VERSION ""

NS_ :

BS_:

BU_: APPS BMS Charger ContactorDriver Dash Dyno IMD_Monitor Inverter Logger PDU Screen TelemetryCar TelemetryPits TempMon

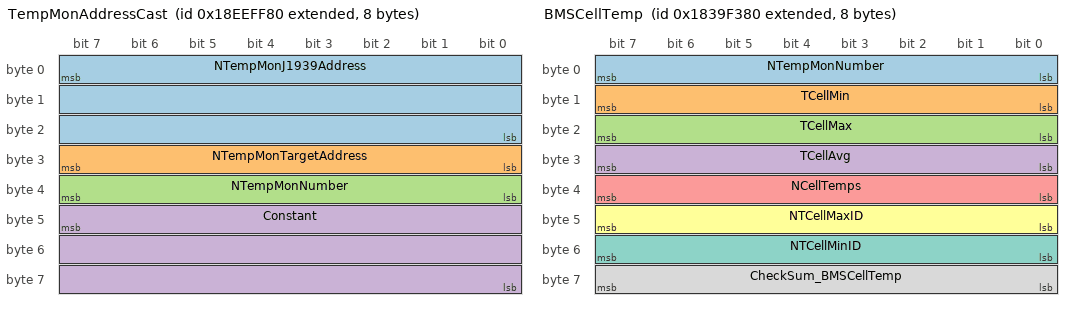
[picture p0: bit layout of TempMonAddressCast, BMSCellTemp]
BO_ 2565799808 TempMonAddressCast: 8 TempMon
 SG_ NTempMonJ1939Address : 7|24@0+ (1.000000,0.000000) [0.000000|16777215.000000] ""  BMS
 SG_ NTempMonTargetAddress : 31|8@0+ (1.000000,0.000000) [0.000000|255.000000] ""  BMS
 SG_ NTempMonNumber : 39|8@0+ (1.000000,0.000000) [0.000000|255.000000] ""  BMS
 SG_ Constant : 47|24@0+ (1.000000,0.000000) [0.000000|16777215.000000] ""  BMS

BO_ 2553934720 BMSCellTemp: 8 TempMon
 SG_ NTempMonNumber : 7|8@0+ (1.000000,0.000000) [0.000000|255.000000] ""  BMS
 SG_ TCellMin : 15|8@0- (1.000000,0.000000) [-128.000000|127.000000] "degC"  BMS
 SG_ TCellMax : 23|8@0- (1.000000,0.000000) [-128.000000|127.000000] "degC"  BMS
 SG_ TCellAvg : 31|8@0- (1.000000,0.000000) [-128.000000|127.000000] "degC"  BMS
 SG_ NCellTemps : 39|8@0+ (1.000000,0.000000) [0.000000|255.000000] ""  BMS
 SG_ NTCellMaxID : 47|8@0+ (1.000000,0.000000) [0.000000|255.000000] ""  BMS
 SG_ NTCellMinID : 55|8@0+ (1.000000,0.000000) [0.000000|255.000000] ""  BMS
 SG_ CheckSum_BMSCellTemp : 63|8@0+ (1.000000,0.000000) [0.000000|255.000000] ""  BMS

BO_ 2553869184 CellTempGeneral: 8 TempMon
 SG_ NTCellID M : 7|16@0+ (1.000000,0.000000) [0.000000|65535.000000] ""  BMS
 SG_ TCell001 m0 : 23|8@0- (1.000000,0.000000) [-128.000000|127.000000] "degC"  BMS
 SG_ TCell002 m1 : 23|8@0- (1.000000,0.000000) [-128.000000|127.000000] "degC"  BMS
 SG_ TCell003 m2 : 23|8@0- (1.000000,0.000000) [-128.000000|127.000000] "degC"  BMS
 SG_ TCell004 m3 : 23|8@0- (1.000000,0.000000) [-128.000000|127.000000] "degC"  BMS
 SG_ TCell005 m4 : 23|8@0- (1.000000,0.000000) [-128.000000|127.000000] "degC"  BMS
 SG_ TCell006 m5 : 23|8@0- (1.000000,0.000000) [-128.000000|127.000000] "degC"  BMS
 SG_ TCell007 m6 : 23|8@0- (1.000000,0.000000) [-128.000000|127.000000] "degC"  BMS
 SG_ TCell008 m7 : 23|8@0- (1.000000,0.000000) [-128.000000|127.000000] "degC"  BMS
 SG_ TCell009 m8 : 23|8@0- (1.000000,0.000000) [-128.000000|127.000000] "degC"  BMS
 SG_ TCell010 m9 : 23|8@0- (1.000000,0.000000) [-128.000000|127.000000] "degC"  BMS
 SG_ TCell011 m10 : 23|8@0- (1.000000,0.000000) [-128.000000|127.000000] "degC"  BMS
 SG_ TCell012 m11 : 23|8@0- (1.000000,0.000000) [-128.000000|127.000000] "degC"  BMS
 SG_ TCell013 m12 : 23|8@0- (1.000000,0.000000) [-128.000000|127.000000] "degC"  BMS
 SG_ TCell014 m13 : 23|8@0- (1.000000,0.000000) [-128.000000|127.000000] "degC"  BMS
 SG_ TCell015 m14 : 23|8@0- (1.000000,0.000000) [-128.000000|127.000000] "degC"  BMS
 SG_ TCell016 m15 : 23|8@0- (1.000000,0.000000) [-128.000000|127.000000] "degC"  BMS
 SG_ TCell017 m16 : 23|8@0- (1.000000,0.000000) [-128.000000|127.000000] "degC"  BMS
 SG_ TCell018 m17 : 23|8@0- (1.000000,0.000000) [-128.000000|127.000000] "degC"  BMS
 SG_ TCell019 m18 : 23|8@0- (1.000000,0.000000) [-128.000000|127.000000] "degC"  BMS
 SG_ TCell020 m19 : 23|8@0- (1.000000,0.000000) [-128.000000|127.000000] "degC"  BMS
 SG_ TCell021 m20 : 23|8@0- (1.000000,0.000000) [-128.000000|127.000000] "degC"  BMS
 SG_ TCell022 m21 : 23|8@0- (1.000000,0.000000) [-128.000000|127.000000] "degC"  BMS
 SG_ TCell023 m22 : 23|8@0- (1.000000,0.000000) [-128.000000|127.000000] "degC"  BMS
 SG_ TCell024 m23 : 23|8@0- (1.000000,0.000000) [-128.000000|127.000000] "degC"  BMS
 SG_ TCell025 m24 : 23|8@0- (1.000000,0.000000) [-128.000000|127.000000] "degC"  BMS
 SG_ TCell026 m25 : 23|8@0- (1.000000,0.000000) [-128.000000|127.000000] "degC"  BMS
 SG_ TCell027 m26 : 23|8@0- (1.000000,0.000000) [-128.000000|127.000000] "degC"  BMS
 SG_ TCell028 m27 : 23|8@0- (1.000000,0.000000) [-128.000000|127.000000] "degC"  BMS
 SG_ TCell029 m28 : 23|8@0- (1.000000,0.000000) [-128.000000|127.000000] "degC"  BMS
 SG_ TCell030 m29 : 23|8@0- (1.000000,0.000000) [-128.000000|127.000000] "degC"  BMS
 SG_ TCell031 m30 : 23|8@0- (1.000000,0.000000) [-128.000000|127.000000] "degC"  BMS
 SG_ TCell032 m31 : 23|8@0- (1.000000,0.000000) [-128.000000|127.000000] "degC"  BMS
 SG_ TCell033 m32 : 23|8@0- (1.000000,0.000000) [-128.000000|127.000000] "degC"  BMS
 SG_ TCell034 m33 : 23|8@0- (1.000000,0.000000) [-128.000000|127.000000] "degC"  BMS
 SG_ TCell035 m34 : 23|8@0- (1.000000,0.000000) [-128.000000|127.000000] "degC"  BMS
 SG_ TCell036 m35 : 23|8@0- (1.000000,0.000000) [-128.000000|127.000000] "degC"  BMS
 SG_ TCell037 m36 : 23|8@0- (1.000000,0.000000) [-128.000000|127.000000] "degC"  BMS
 SG_ TCell038 m37 : 23|8@0- (1.000000,0.000000) [-128.000000|127.000000] "degC"  BMS
 SG_ TCell039 m38 : 23|8@0- (1.000000,0.000000) [-128.000000|127.000000] "degC"  BMS
 SG_ TCell040 m39 : 23|8@0- (1.000000,0.000000) [-128.000000|127.000000] "degC"  BMS
 SG_ TCell041 m40 : 23|8@0- (1.000000,0.000000) [-128.000000|127.000000] "degC"  BMS
 SG_ TCell042 m41 : 23|8@0- (1.000000,0.000000) [-128.000000|127.000000] "degC"  BMS
 SG_ TCell043 m42 : 23|8@0- (1.000000,0.000000) [-128.000000|127.000000] "degC"  BMS
 SG_ TCell044 m43 : 23|8@0- (1.000000,0.000000) [-128.000000|127.000000] "degC"  BMS
 SG_ TCell045 m44 : 23|8@0- (1.000000,0.000000) [-128.000000|127.000000] "degC"  BMS
 SG_ TCell046 m45 : 23|8@0- (1.000000,0.000000) [-128.000000|127.000000] "degC"  BMS
 SG_ TCell047 m46 : 23|8@0- (1.000000,0.000000) [-128.000000|127.000000] "degC"  BMS
 SG_ TCell048 m47 : 23|8@0- (1.000000,0.000000) [-128.000000|127.000000] "degC"  BMS
 SG_ TCell049 m48 : 23|8@0- (1.000000,0.000000) [-128.000000|127.000000] "degC"  BMS
 SG_ TCell050 m49 : 23|8@0- (1.000000,0.000000) [-128.000000|127.000000] "degC"  BMS
 SG_ TCell051 m50 : 23|8@0- (1.000000,0.000000) [-128.000000|127.000000] "degC"  BMS
 SG_ TCell052 m51 : 23|8@0- (1.000000,0.000000) [-128.000000|127.000000] "degC"  BMS
 SG_ TCell053 m52 : 23|8@0- (1.000000,0.000000) [-128.000000|127.000000] "degC"  BMS
 SG_ TCell054 m53 : 23|8@0- (1.000000,0.000000) [-128.000000|127.000000] "degC"  BMS
 SG_ TCell055 m54 : 23|8@0- (1.000000,0.000000) [-128.000000|127.000000] "degC"  BMS
 SG_ TCell056 m55 : 23|8@0- (1.000000,0.000000) [-128.000000|127.000000] "degC"  BMS
 SG_ TCell057 m56 : 23|8@0- (1.000000,0.000000) [-128.000000|127.000000] "degC"  BMS
 SG_ TCell058 m57 : 23|8@0- (1.000000,0.000000) [-128.000000|127.000000] "degC"  BMS
 SG_ TCell059 m58 : 23|8@0- (1.000000,0.000000) [-128.000000|127.000000] "degC"  BMS
 SG_ TCell060 m59 : 23|8@0- (1.000000,0.000000) [-128.000000|127.000000] "degC"  BMS
 SG_ TCell061 m60 : 23|8@0- (1.000000,0.000000) [-128.000000|127.000000] "degC"  BMS
 SG_ TCell062 m61 : 23|8@0- (1.000000,0.000000) [-128.000000|127.000000] "degC"  BMS
 SG_ TCell063 m62 : 23|8@0- (1.000000,0.000000) [-128.000000|127.000000] "degC"  BMS
 SG_ TCell064 m63 : 23|8@0- (1.000000,0.000000) [-128.000000|127.000000] "degC"  BMS
 SG_ TCell065 m64 : 23|8@0- (1.000000,0.000000) [-128.000000|127.000000] "degC"  BMS
 SG_ TCell066 m65 : 23|8@0- (1.000000,0.000000) [-128.000000|127.000000] "degC"  BMS
 SG_ TCell067 m66 : 23|8@0- (1.000000,0.000000) [-128.000000|127.000000] "degC"  BMS
 SG_ TCell068 m67 : 23|8@0- (1.000000,0.000000) [-128.000000|127.000000] "degC"  BMS
 SG_ TCell069 m68 : 23|8@0- (1.000000,0.000000) [-128.000000|127.000000] "degC"  BMS
 SG_ TCell070 m69 : 23|8@0- (1.000000,0.000000) [-128.000000|127.000000] "degC"  BMS
 SG_ TCell071 m70 : 23|8@0- (1.000000,0.000000) [-128.000000|127.000000] "degC"  BMS
 SG_ TCell072 m71 : 23|8@0- (1.000000,0.000000) [-128.000000|127.000000] "degC"  BMS
 SG_ TCell073 m72 : 23|8@0- (1.000000,0.000000) [-128.000000|127.000000] "degC"  BMS
 SG_ TCell074 m73 : 23|8@0- (1.000000,0.000000) [-128.000000|127.000000] "degC"  BMS
 SG_ TCell075 m74 : 23|8@0- (1.000000,0.000000) [-128.000000|127.000000] "degC"  BMS
 SG_ TCell076 m75 : 23|8@0- (1.000000,0.000000) [-128.000000|127.000000] "degC"  BMS
 SG_ TCell077 m76 : 23|8@0- (1.000000,0.000000) [-128.000000|127.000000] "degC"  BMS
 SG_ TCell078 m77 : 23|8@0- (1.000000,0.000000) [-128.000000|127.000000] "degC"  BMS
 SG_ TCell079 m78 : 23|8@0- (1.000000,0.000000) [-128.000000|127.000000] "degC"  BMS
 SG_ TCell080 m79 : 23|8@0- (1.000000,0.000000) [-128.000000|127.000000] "degC"  BMS
 SG_ TCell081 m80 : 23|8@0- (1.000000,0.000000) [-128.000000|127.000000] "degC"  BMS
 SG_ TCell082 m81 : 23|8@0- (1.000000,0.000000) [-128.000000|127.000000] "degC"  BMS
 SG_ TCell083 m82 : 23|8@0- (1.000000,0.000000) [-128.000000|127.000000] "degC"  BMS
 SG_ TCell084 m83 : 23|8@0- (1.000000,0.000000) [-128.000000|127.000000] "degC"  BMS
 SG_ TCell085 m84 : 23|8@0- (1.000000,0.000000) [-128.000000|127.000000] "degC"  BMS
 SG_ TCell086 m85 : 23|8@0- (1.000000,0.000000) [-128.000000|127.000000] "degC"  BMS
 SG_ TCell087 m86 : 23|8@0- (1.000000,0.000000) [-128.000000|127.000000] "degC"  BMS
 SG_ TCell088 m87 : 23|8@0- (1.000000,0.000000) [-128.000000|127.000000] "degC"  BMS
 SG_ TCell089 m88 : 23|8@0- (1.000000,0.000000) [-128.000000|127.000000] "degC"  BMS
 SG_ TCell090 m89 : 23|8@0- (1.000000,0.000000) [-128.000000|127.000000] "degC"  BMS
 SG_ TCell091 m90 : 23|8@0- (1.000000,0.000000) [-128.000000|127.000000] "degC"  BMS
 SG_ TCell092 m91 : 23|8@0- (1.000000,0.000000) [-128.000000|127.000000] "degC"  BMS
 SG_ TCell093 m92 : 23|8@0- (1.000000,0.000000) [-128.000000|127.000000] "degC"  BMS
 SG_ TCell094 m93 : 23|8@0- (1.000000,0.000000) [-128.000000|127.000000] "degC"  BMS
 SG_ TCell095 m94 : 23|8@0- (1.000000,0.000000) [-128.000000|127.000000] "degC"  BMS
 SG_ TCell096 m95 : 23|8@0- (1.000000,0.000000) [-128.000000|127.000000] "degC"  BMS
 SG_ TCell097 m96 : 23|8@0- (1.000000,0.000000) [-128.000000|127.000000] "degC"  BMS
 SG_ TCell098 m97 : 23|8@0- (1.000000,0.000000) [-128.000000|127.000000] "degC"  BMS
 SG_ TCell099 m98 : 23|8@0- (1.000000,0.000000) [-128.000000|127.000000] "degC"  BMS
 SG_ TCell100 m99 : 23|8@0- (1.000000,0.000000) [-128.000000|127.000000] "degC"  BMS
 SG_ TCell101 m100 : 23|8@0- (1.000000,0.000000) [-128.000000|127.000000] "degC"  BMS
 SG_ TCell102 m101 : 23|8@0- (1.000000,0.000000) [-128.000000|127.000000] "degC"  BMS
 SG_ TCell103 m102 : 23|8@0- (1.000000,0.000000) [-128.000000|127.000000] "degC"  BMS
 SG_ TCell104 m103 : 23|8@0- (1.000000,0.000000) [-128.000000|127.000000] "degC"  BMS
 SG_ TCell105 m104 : 23|8@0- (1.000000,0.000000) [-128.000000|127.000000] "degC"  BMS
 SG_ TCell106 m105 : 23|8@0- (1.000000,0.000000) [-128.000000|127.000000] "degC"  BMS
 SG_ TCell107 m106 : 23|8@0- (1.000000,0.000000) [-128.000000|127.000000] "degC"  BMS
 SG_ TCell108 m107 : 23|8@0- (1.000000,0.000000) [-128.000000|127.000000] "degC"  BMS
 SG_ TCell109 m108 : 23|8@0- (1.000000,0.000000) [-128.000000|127.000000] "degC"  BMS
 SG_ TCell110 m109 : 23|8@0- (1.000000,0.000000) [-128.000000|127.000000] "degC"  BMS
 SG_ Constant m0 : 31|8@0+ (1.000000,0.000000) [0.000000|255.000000] ""  BMS
 SG_ Constant m1 : 31|8@0+ (1.000000,0.000000) [0.000000|255.000000] ""  BMS
 SG_ Constant m2 : 31|8@0+ (1.000000,0.000000) [0.000000|255.000000] ""  BMS
 SG_ Constant m3 : 31|8@0+ (1.000000,0.000000) [0.000000|255.000000] ""  BMS
 SG_ Constant m4 : 31|8@0+ (1.000000,0.000000) [0.000000|255.000000] ""  BMS
 SG_ Constant m5 : 31|8@0+ (1.000000,0.000000) [0.000000|255.000000] ""  BMS
 SG_ Constant m6 : 31|8@0+ (1.000000,0.000000) [0.000000|255.000000] ""  BMS
 SG_ Constant m7 : 31|8@0+ (1.000000,0.000000) [0.000000|255.000000] ""  BMS
 SG_ Constant m8 : 31|8@0+ (1.000000,0.000000) [0.000000|255.000000] ""  BMS
 SG_ Constant m9 : 31|8@0+ (1.000000,0.000000) [0.000000|255.000000] ""  BMS
 SG_ Constant m10 : 31|8@0+ (1.000000,0.000000) [0.000000|255.000000] ""  BMS
 SG_ Constant m11 : 31|8@0+ (1.000000,0.000000) [0.000000|255.000000] ""  BMS
 SG_ Constant m12 : 31|8@0+ (1.000000,0.000000) [0.000000|255.000000] ""  BMS
 SG_ Constant m13 : 31|8@0+ (1.000000,0.000000) [0.000000|255.000000] ""  BMS
 SG_ Constant m14 : 31|8@0+ (1.000000,0.000000) [0.000000|255.000000] ""  BMS
 SG_ Constant m15 : 31|8@0+ (1.000000,0.000000) [0.000000|255.000000] ""  BMS
 SG_ Constant m16 : 31|8@0+ (1.000000,0.000000) [0.000000|255.000000] ""  BMS
 SG_ Constant m17 : 31|8@0+ (1.000000,0.000000) [0.000000|255.000000] ""  BMS
 SG_ Constant m18 : 31|8@0+ (1.000000,0.000000) [0.000000|255.000000] ""  BMS
 SG_ Constant m19 : 31|8@0+ (1.000000,0.000000) [0.000000|255.000000] ""  BMS
 SG_ Constant m20 : 31|8@0+ (1.000000,0.000000) [0.000000|255.000000] ""  BMS
 SG_ Constant m21 : 31|8@0+ (1.000000,0.000000) [0.000000|255.000000] ""  BMS
 SG_ Constant m22 : 31|8@0+ (1.000000,0.000000) [0.000000|255.000000] ""  BMS
 SG_ Constant m23 : 31|8@0+ (1.000000,0.000000) [0.000000|255.000000] ""  BMS
 SG_ Constant m24 : 31|8@0+ (1.000000,0.000000) [0.000000|255.000000] ""  BMS
 SG_ Constant m25 : 31|8@0+ (1.000000,0.000000) [0.000000|255.000000] ""  BMS
 SG_ Constant m26 : 31|8@0+ (1.000000,0.000000) [0.000000|255.000000] ""  BMS
 SG_ Constant m27 : 31|8@0+ (1.000000,0.000000) [0.000000|255.000000] ""  BMS
 SG_ Constant m28 : 31|8@0+ (1.000000,0.000000) [0.000000|255.000000] ""  BMS
 SG_ Constant m29 : 31|8@0+ (1.000000,0.000000) [0.000000|255.000000] ""  BMS
 SG_ Constant m30 : 31|8@0+ (1.000000,0.000000) [0.000000|255.000000] ""  BMS
 SG_ Constant m31 : 31|8@0+ (1.000000,0.000000) [0.000000|255.000000] ""  BMS
 SG_ Constant m32 : 31|8@0+ (1.000000,0.000000) [0.000000|255.000000] ""  BMS
 SG_ Constant m33 : 31|8@0+ (1.000000,0.000000) [0.000000|255.000000] ""  BMS
 SG_ Constant m34 : 31|8@0+ (1.000000,0.000000) [0.000000|255.000000] ""  BMS
 SG_ Constant m35 : 31|8@0+ (1.000000,0.000000) [0.000000|255.000000] ""  BMS
 SG_ Constant m36 : 31|8@0+ (1.000000,0.000000) [0.000000|255.000000] ""  BMS
 SG_ Constant m37 : 31|8@0+ (1.000000,0.000000) [0.000000|255.000000] ""  BMS
 SG_ Constant m38 : 31|8@0+ (1.000000,0.000000) [0.000000|255.000000] ""  BMS
 SG_ Constant m39 : 31|8@0+ (1.000000,0.000000) [0.000000|255.000000] ""  BMS
 SG_ Constant m40 : 31|8@0+ (1.000000,0.000000) [0.000000|255.000000] ""  BMS
 SG_ Constant m41 : 31|8@0+ (1.000000,0.000000) [0.000000|255.000000] ""  BMS
 SG_ Constant m42 : 31|8@0+ (1.000000,0.000000) [0.000000|255.000000] ""  BMS
 SG_ Constant m43 : 31|8@0+ (1.000000,0.000000) [0.000000|255.000000] ""  BMS
 SG_ Constant m44 : 31|8@0+ (1.000000,0.000000) [0.000000|255.000000] ""  BMS
 SG_ Constant m45 : 31|8@0+ (1.000000,0.000000) [0.000000|255.000000] ""  BMS
 SG_ Constant m46 : 31|8@0+ (1.000000,0.000000) [0.000000|255.000000] ""  BMS
 SG_ Constant m47 : 31|8@0+ (1.000000,0.000000) [0.000000|255.000000] ""  BMS
 SG_ Constant m48 : 31|8@0+ (1.000000,0.000000) [0.000000|255.000000] ""  BMS
 SG_ Constant m49 : 31|8@0+ (1.000000,0.000000) [0.000000|255.000000] ""  BMS
 SG_ Constant m50 : 31|8@0+ (1.000000,0.000000) [0.000000|255.000000] ""  BMS
 SG_ Constant m51 : 31|8@0+ (1.000000,0.000000) [0.000000|255.000000] ""  BMS
 SG_ Constant m52 : 31|8@0+ (1.000000,0.000000) [0.000000|255.000000] ""  BMS
 SG_ Constant m53 : 31|8@0+ (1.000000,0.000000) [0.000000|255.000000] ""  BMS
 SG_ Constant m54 : 31|8@0+ (1.000000,0.000000) [0.000000|255.000000] ""  BMS
 SG_ Constant m55 : 31|8@0+ (1.000000,0.000000) [0.000000|255.000000] ""  BMS
 SG_ Constant m56 : 31|8@0+ (1.000000,0.000000) [0.000000|255.000000] ""  BMS
 SG_ Constant m57 : 31|8@0+ (1.000000,0.000000) [0.000000|255.000000] ""  BMS
 SG_ Constant m58 : 31|8@0+ (1.000000,0.000000) [0.000000|255.000000] ""  BMS
 SG_ Constant m59 : 31|8@0+ (1.000000,0.000000) [0.000000|255.000000] ""  BMS
 SG_ Constant m60 : 31|8@0+ (1.000000,0.000000) [0.000000|255.000000] ""  BMS
 SG_ Constant m61 : 31|8@0+ (1.000000,0.000000) [0.000000|255.000000] ""  BMS
 SG_ Constant m62 : 31|8@0+ (1.000000,0.000000) [0.000000|255.000000] ""  BMS
 SG_ Constant m63 : 31|8@0+ (1.000000,0.000000) [0.000000|255.000000] ""  BMS
 SG_ Constant m64 : 31|8@0+ (1.000000,0.000000) [0.000000|255.000000] ""  BMS
 SG_ Constant m65 : 31|8@0+ (1.000000,0.000000) [0.000000|255.000000] ""  BMS
 SG_ Constant m66 : 31|8@0+ (1.000000,0.000000) [0.000000|255.000000] ""  BMS
 SG_ Constant m67 : 31|8@0+ (1.000000,0.000000) [0.000000|255.000000] ""  BMS
 SG_ Constant m68 : 31|8@0+ (1.000000,0.000000) [0.000000|255.000000] ""  BMS
 SG_ Constant m69 : 31|8@0+ (1.000000,0.000000) [0.000000|255.000000] ""  BMS
 SG_ Constant m70 : 31|8@0+ (1.000000,0.000000) [0.000000|255.000000] ""  BMS
 SG_ Constant m71 : 31|8@0+ (1.000000,0.000000) [0.000000|255.000000] ""  BMS
 SG_ Constant m72 : 31|8@0+ (1.000000,0.000000) [0.000000|255.000000] ""  BMS
 SG_ Constant m73 : 31|8@0+ (1.000000,0.000000) [0.000000|255.000000] ""  BMS
 SG_ Constant m74 : 31|8@0+ (1.000000,0.000000) [0.000000|255.000000] ""  BMS
 SG_ Constant m75 : 31|8@0+ (1.000000,0.000000) [0.000000|255.000000] ""  BMS
 SG_ Constant m76 : 31|8@0+ (1.000000,0.000000) [0.000000|255.000000] ""  BMS
 SG_ Constant m77 : 31|8@0+ (1.000000,0.000000) [0.000000|255.000000] ""  BMS
 SG_ Constant m78 : 31|8@0+ (1.000000,0.000000) [0.000000|255.000000] ""  BMS
 SG_ Constant m79 : 31|8@0+ (1.000000,0.000000) [0.000000|255.000000] ""  BMS
 SG_ Constant m80 : 31|8@0+ (1.000000,0.000000) [0.000000|255.000000] ""  BMS
 SG_ Constant m81 : 31|8@0+ (1.000000,0.000000) [0.000000|255.000000] ""  BMS
 SG_ Constant m82 : 31|8@0+ (1.000000,0.000000) [0.000000|255.000000] ""  BMS
 SG_ Constant m83 : 31|8@0+ (1.000000,0.000000) [0.000000|255.000000] ""  BMS
 SG_ Constant m84 : 31|8@0+ (1.000000,0.000000) [0.000000|255.000000] ""  BMS
 SG_ Constant m85 : 31|8@0+ (1.000000,0.000000) [0.000000|255.000000] ""  BMS
 SG_ Constant m86 : 31|8@0+ (1.000000,0.000000) [0.000000|255.000000] ""  BMS
 SG_ Constant m87 : 31|8@0+ (1.000000,0.000000) [0.000000|255.000000] ""  BMS
 SG_ Constant m88 : 31|8@0+ (1.000000,0.000000) [0.000000|255.000000] ""  BMS
 SG_ Constant m89 : 31|8@0+ (1.000000,0.000000) [0.000000|255.000000] ""  BMS
 SG_ Constant m90 : 31|8@0+ (1.000000,0.000000) [0.000000|255.000000] ""  BMS
 SG_ Constant m91 : 31|8@0+ (1.000000,0.000000) [0.000000|255.000000] ""  BMS
 SG_ Constant m92 : 31|8@0+ (1.000000,0.000000) [0.000000|255.000000] ""  BMS
 SG_ Constant m93 : 31|8@0+ (1.000000,0.000000) [0.000000|255.000000] ""  BMS
 SG_ Constant m94 : 31|8@0+ (1.000000,0.000000) [0.000000|255.000000] ""  BMS
 SG_ Constant m95 : 31|8@0+ (1.000000,0.000000) [0.000000|255.000000] ""  BMS
 SG_ Constant m96 : 31|8@0+ (1.000000,0.000000) [0.000000|255.000000] ""  BMS
 SG_ Constant m97 : 31|8@0+ (1.000000,0.000000) [0.000000|255.000000] ""  BMS
 SG_ Constant m98 : 31|8@0+ (1.000000,0.000000) [0.000000|255.000000] ""  BMS
 SG_ Constant m99 : 31|8@0+ (1.000000,0.000000) [0.000000|255.000000] ""  BMS
 SG_ Constant m100 : 31|8@0+ (1.000000,0.000000) [0.000000|255.000000] ""  BMS
 SG_ Constant m101 : 31|8@0+ (1.000000,0.000000) [0.000000|255.000000] ""  BMS
 SG_ Constant m102 : 31|8@0+ (1.000000,0.000000) [0.000000|255.000000] ""  BMS
 SG_ Constant m103 : 31|8@0+ (1.000000,0.000000) [0.000000|255.000000] ""  BMS
 SG_ Constant m104 : 31|8@0+ (1.000000,0.000000) [0.000000|255.000000] ""  BMS
 SG_ Constant m105 : 31|8@0+ (1.000000,0.000000) [0.000000|255.000000] ""  BMS
 SG_ Constant m106 : 31|8@0+ (1.000000,0.000000) [0.000000|255.000000] ""  BMS
 SG_ Constant m107 : 31|8@0+ (1.000000,0.000000) [0.000000|255.000000] ""  BMS
 SG_ Constant m108 : 31|8@0+ (1.000000,0.000000) [0.000000|255.000000] ""  BMS
 SG_ Constant m109 : 31|8@0+ (1.000000,0.000000) [0.000000|255.000000] ""  BMS
 SG_ TCellMin : 39|8@0- (1.000000,0.000000) [-128.000000|127.000000] "degC"  BMS
 SG_ TCellMax : 47|8@0- (1.000000,0.000000) [-128.000000|127.000000] "degC"  BMS
 SG_ NTCellMaxID : 55|8@0+ (1.000000,0.000000) [0.000000|255.000000] ""  BMS
 SG_ NTCellMinID : 63|8@0+ (1.000000,0.000000) [0.000000|255.000000] ""  BMS

BO_ 2550589940 ElconInterface3: 8 BMS
 SG_ Maximum_Cell_Voltage : 7|16@0+ (0.100000,0.000000) [0.000000|6553.500000] "V"  Charger
 SG_ Pack_CCL : 23|16@0+ (0.100000,0.000000) [0.000000|6553.500000] "A"  Charger
 SG_ DTC_P0A08_Charger_Safety_Relay_Fault : 32|1@1+ (1.000000,0.000000) [0.000000|1.000000] ""  Charger
 SG_ Reserved : 38|31@0+ (1.000000,0.000000) [0.000000|2147483647.000000] ""  Charger

BO_ 2550589428 ElconInterface1: 8 BMS
 SG_ Maximum_Pack_Voltage : 7|16@0+ (0.100000,0.000000) [0.000000|6553.500000] "V"  Charger
 SG_ Pack_CCL : 23|16@0- (0.100000,0.000000) [-3276.800000|3276.700000] "A"  Charger
 SG_ DTC_P0A08_Charger_Safety_Relay_Fault : 32|1@1+ (1.000000,0.000000) [0.000000|1.000000] ""  Charger
 SG_ Reserved : 38|31@0+ (1.000000,0.000000) [0.000000|2147483647.000000] ""  Charger

BO_ 2550588916 ElconInterface2: 8 BMS
 SG_ Maximum_Cell_Voltage : 7|16@0+ (0.100000,0.000000) [0.000000|6553.500000] "V"  Charger
 SG_ Pack_CCL : 23|16@0- (0.100000,0.000000) [-3276.800000|3276.700000] "A"  Charger
 SG_ DTC_P0A08_Charger_Safety_Relay_Fault : 32|1@1+ (1.000000,0.000000) [0.000000|1.000000] ""  Charger
 SG_ Reserved : 38|31@0+ (1.000000,0.000000) [0.000000|2147483647.000000] ""  Charger

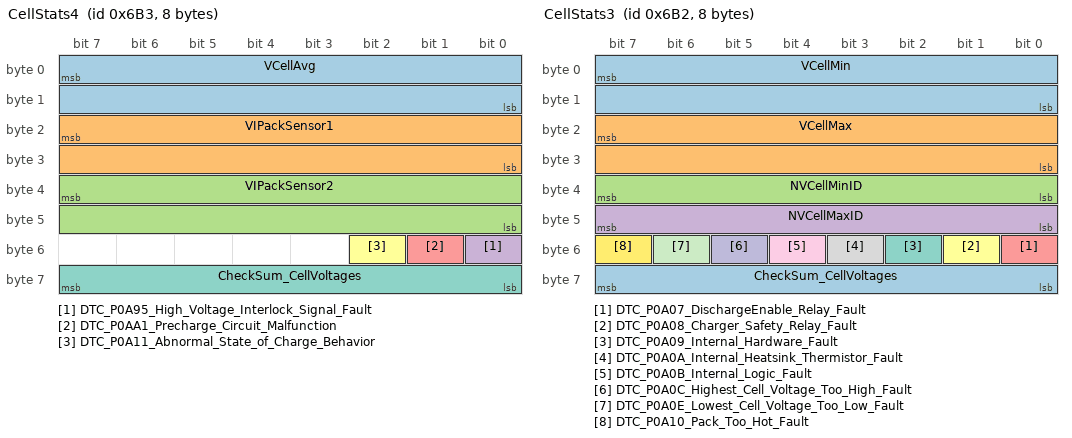
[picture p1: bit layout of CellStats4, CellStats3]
BO_ 1715 CellStats4: 8 BMS
 SG_ VCellAvg : 7|16@0+ (0.000100,0.000000) [0.000000|6.553500] "V"  Logger
 SG_ VIPackSensor1 : 23|16@0+ (1.000000,0.000000) [0.000000|65535.000000] ""  Logger
 SG_ VIPackSensor2 : 39|16@0+ (1.000000,0.000000) [0.000000|65535.000000] ""  Logger
 SG_ DTC_P0A95_High_Voltage_Interlock_Signal_Fault : 48|1@1+ (1.000000,0.000000) [0.000000|1.000000] ""  Logger
 SG_ DTC_P0AA1_Precharge_Circuit_Malfunction : 49|1@1+ (1.000000,0.000000) [0.000000|1.000000] ""  Logger
 SG_ DTC_P0A11_Abnormal_State_of_Charge_Behavior : 50|1@1+ (1.000000,0.000000) [0.000000|1.000000] ""  Logger
 SG_ CheckSum_CellVoltages : 63|8@0+ (1.000000,0.000000) [0.000000|255.000000] ""  Logger

BO_ 1714 CellStats3: 8 BMS
 SG_ VCellMin : 7|16@0+ (0.000100,0.000000) [0.000000|6.553500] "V"  Logger
 SG_ VCellMax : 23|16@0+ (0.000100,0.000000) [0.000000|6.553500] "V"  Logger
 SG_ NVCellMinID : 39|8@0+ (1.000000,0.000000) [0.000000|255.000000] "ID"  Logger
 SG_ NVCellMaxID : 47|8@0+ (1.000000,0.000000) [0.000000|255.000000] "ID"  Logger
 SG_ DTC_P0A07_DischargeEnable_Relay_Fault : 48|1@1+ (1.000000,0.000000) [0.000000|1.000000] ""  Logger
 SG_ DTC_P0A08_Charger_Safety_Relay_Fault : 49|1@1+ (1.000000,0.000000) [0.000000|1.000000] ""  Logger
 SG_ DTC_P0A09_Internal_Hardware_Fault : 50|1@1+ (1.000000,0.000000) [0.000000|1.000000] ""  Logger
 SG_ DTC_P0A0A_Internal_Heatsink_Thermistor_Fault : 51|1@1+ (1.000000,0.000000) [0.000000|1.000000] ""  Logger
 SG_ DTC_P0A0B_Internal_Logic_Fault : 52|1@1+ (1.000000,0.000000) [0.000000|1.000000] ""  Logger
 SG_ DTC_P0A0C_Highest_Cell_Voltage_Too_High_Fault : 53|1@1+ (1.000000,0.000000) [0.000000|1.000000] ""  Logger
 SG_ DTC_P0A0E_Lowest_Cell_Voltage_Too_Low_Fault : 54|1@1+ (1.000000,0.000000) [0.000000|1.000000] ""  Logger
 SG_ DTC_P0A10_Pack_Too_Hot_Fault : 55|1@1+ (1.000000,0.000000) [0.000000|1.000000] ""  Logger
 SG_ CheckSum_CellVoltages : 63|8@0+ (1.000000,0.000000) [0.000000|255.000000] ""  Logger

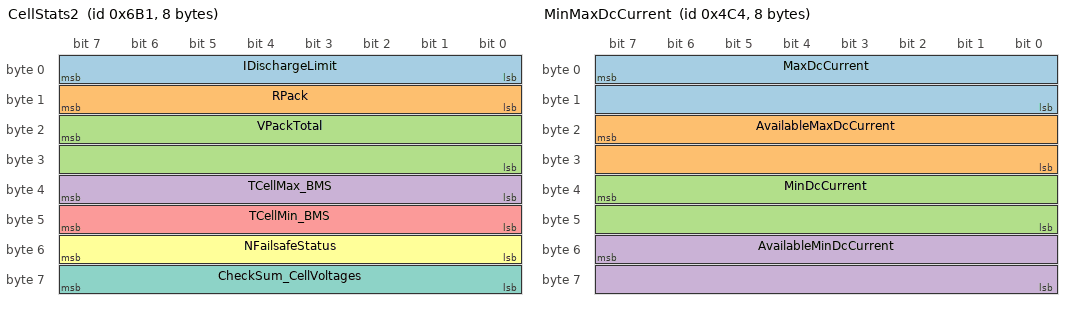
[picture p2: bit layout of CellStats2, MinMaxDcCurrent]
BO_ 1713 CellStats2: 8 BMS
 SG_ IDischargeLimit : 7|8@0+ (1.000000,0.000000) [0.000000|255.000000] "A"  Logger
 SG_ RPack : 15|8@0+ (0.001000,0.000000) [0.000000|0.255000] "Ohms"  Logger
 SG_ VPackTotal : 23|16@0+ (0.010000,0.000000) [0.000000|655.350000] "V"  Logger
 SG_ TCellMax_BMS : 39|8@0+ (1.000000,0.000000) [0.000000|255.000000] "degC"  Logger
 SG_ TCellMin_BMS : 47|8@0+ (1.000000,0.000000) [0.000000|255.000000] "degC"  Logger
 SG_ NFailsafeStatus : 55|8@0+ (1.000000,0.000000) [0.000000|255.000000] ""  Logger
 SG_ CheckSum_CellVoltages : 63|8@0+ (1.000000,1721.000000) [1721.000000|1976.000000] ""  Logger

BO_ 1712 CellStats1: 8 BMS
 SG_ IPack : 7|16@0+ (0.100000,0.000000) [0.000000|6553.500000] "A"  Logger
 SG_ VPackInstant : 23|16@0+ (0.100000,0.000000) [0.000000|6553.500000] "V"  Logger
 SG_ rSOC : 39|8@0+ (0.500000,0.000000) [0.000000|127.500000] "%"  Logger
 SG_ Ready_Power_Signal : 47|1@0+ (1.000000,0.000000) [0.000000|1.000000] ""  Logger
 SG_ Charge_Power_Signal : 41|1@1+ (1.000000,0.000000) [0.000000|1.000000] ""  Logger
 SG_ Charge_Interlock : 42|1@1+ (1.000000,0.000000) [0.000000|1.000000] ""  Logger
 SG_ Balancing_Active : 43|1@1+ (1.000000,0.000000) [0.000000|1.000000] ""  Logger
 SG_ Discharge_Enable_Inverted : 44|1@1+ (1.000000,0.000000) [0.000000|1.000000] ""  Logger
 SG_ Charge_Enable_Inverted : 45|1@1+ (1.000000,0.000000) [0.000000|1.000000] ""  Logger
 SG_ Charge_Mode_Active_CAN : 46|1@1+ (1.000000,0.000000) [0.000000|1.000000] ""  Logger
 SG_ MultiPurpose_Input : 47|1@1+ (1.000000,0.000000) [0.000000|1.000000] ""  Logger
 SG_ DTC_P0A1F_Internal_Cell_Communication_Fault : 48|1@1+ (1.000000,0.000000) [0.000000|1.000000] ""  Logger
 SG_ DTC_P0A12_Cell_Balancing_Stuck_Off_Fault : 49|1@1+ (1.000000,0.000000) [0.000000|1.000000] ""  Logger
 SG_ DTC_P0A80_Weak_Cell_Fault : 50|1@1+ (1.000000,0.000000) [0.000000|1.000000] ""  Logger
 SG_ DTC_P0AFA_Low_Cell_Voltage_Fault : 51|1@1+ (1.000000,0.000000) [0.000000|1.000000] ""  Logger
 SG_ DTC_P0A04_Cell_Open_Wiring_Fault : 52|1@1+ (1.000000,0.000000) [0.000000|1.000000] ""  Logger
 SG_ DTC_P0AC0_Current_Sensor_Fault : 53|1@1+ (1.000000,0.000000) [0.000000|1.000000] ""  Logger
 SG_ DTC_P0A0D_Cell_Voltage_Over_5V_Fault : 54|1@1+ (1.000000,0.000000) [0.000000|1.000000] ""  Logger
 SG_ DTC_P0A0F_Cell_Bank_Fault : 55|1@1+ (1.000000,0.000000) [0.000000|1.000000] ""  Logger
 SG_ CheckSum_CellVoltages : 63|8@0+ (1.000000,1720.000000) [1720.000000|1975.000000] ""  Logger

BO_ 1696 CellTempStats: 8 TempMon
 SG_ CellID_Temp M : 7|8@0+ (1.000000,0.000000) [0.000000|255.000000] ""  Logger
 SG_ BTCell001InError m1 : 15|1@0+ (1.000000,0.000000) [0.000000|1.000000] ""  Logger
 SG_ BTCell002InError m2 : 15|1@0+ (1.000000,0.000000) [0.000000|1.000000] ""  Logger
 SG_ BTCell003InError m3 : 15|1@0+ (1.000000,0.000000) [0.000000|1.000000] ""  Logger
 SG_ BTCell004InError m4 : 15|1@0+ (1.000000,0.000000) [0.000000|1.000000] ""  Logger
 SG_ BTCell005InError m5 : 15|1@0+ (1.000000,0.000000) [0.000000|1.000000] ""  Logger
 SG_ BTCell006InError m6 : 15|1@0+ (1.000000,0.000000) [0.000000|1.000000] ""  Logger
 SG_ BTCell007InError m7 : 15|1@0+ (1.000000,0.000000) [0.000000|1.000000] ""  Logger
 SG_ BTCell008InError m8 : 15|1@0+ (1.000000,0.000000) [0.000000|1.000000] ""  Logger
 SG_ BTCell009InError m9 : 15|1@0+ (1.000000,0.000000) [0.000000|1.000000] ""  Logger
 SG_ BTCell010InError m10 : 15|1@0+ (1.000000,0.000000) [0.000000|1.000000] ""  Logger
 SG_ BTCell011InError m11 : 15|1@0+ (1.000000,0.000000) [0.000000|1.000000] ""  Logger
 SG_ BTCell012InError m12 : 15|1@0+ (1.000000,0.000000) [0.000000|1.000000] ""  Logger
 SG_ BTCell013InError m13 : 15|1@0+ (1.000000,0.000000) [0.000000|1.000000] ""  Logger
 SG_ BTCell014InError m14 : 15|1@0+ (1.000000,0.000000) [0.000000|1.000000] ""  Logger
 SG_ BTCell015InError m15 : 15|1@0+ (1.000000,0.000000) [0.000000|1.000000] ""  Logger
 SG_ BTCell016InError m16 : 15|1@0+ (1.000000,0.000000) [0.000000|1.000000] ""  Logger
 SG_ BTCell017InError m17 : 15|1@0+ (1.000000,0.000000) [0.000000|1.000000] ""  Logger
 SG_ BTCell018InError m18 : 15|1@0+ (1.000000,0.000000) [0.000000|1.000000] ""  Logger
 SG_ BTCell019InError m19 : 15|1@0+ (1.000000,0.000000) [0.000000|1.000000] ""  Logger
 SG_ BTCell020InError m20 : 15|1@0+ (1.000000,0.000000) [0.000000|1.000000] ""  Logger
 SG_ BTCell021InError m21 : 15|1@0+ (1.000000,0.000000) [0.000000|1.000000] ""  Logger
 SG_ BTCell022InError m22 : 15|1@0+ (1.000000,0.000000) [0.000000|1.000000] ""  Logger
 SG_ BTCell023InError m23 : 15|1@0+ (1.000000,0.000000) [0.000000|1.000000] ""  Logger
 SG_ BTCell024InError m24 : 15|1@0+ (1.000000,0.000000) [0.000000|1.000000] ""  Logger
 SG_ BTCell025InError m25 : 15|1@0+ (1.000000,0.000000) [0.000000|1.000000] ""  Logger
 SG_ BTCell026InError m26 : 15|1@0+ (1.000000,0.000000) [0.000000|1.000000] ""  Logger
 SG_ BTCell027InError m27 : 15|1@0+ (1.000000,0.000000) [0.000000|1.000000] ""  Logger
 SG_ BTCell028InError m28 : 15|1@0+ (1.000000,0.000000) [0.000000|1.000000] ""  Logger
 SG_ BTCell029InError m29 : 15|1@0+ (1.000000,0.000000) [0.000000|1.000000] ""  Logger
 SG_ BTCell030InError m30 : 15|1@0+ (1.000000,0.000000) [0.000000|1.000000] ""  Logger
 SG_ BTCell031InError m31 : 15|1@0+ (1.000000,0.000000) [0.000000|1.000000] ""  Logger
 SG_ BTCell032InError m32 : 15|1@0+ (1.000000,0.000000) [0.000000|1.000000] ""  Logger
 SG_ BTCell033InError m33 : 15|1@0+ (1.000000,0.000000) [0.000000|1.000000] ""  Logger
 SG_ BTCell034InError m34 : 15|1@0+ (1.000000,0.000000) [0.000000|1.000000] ""  Logger
 SG_ BTCell035InError m35 : 15|1@0+ (1.000000,0.000000) [0.000000|1.000000] ""  Logger
 SG_ BTCell036InError m36 : 15|1@0+ (1.000000,0.000000) [0.000000|1.000000] ""  Logger
 SG_ BTCell037InError m37 : 15|1@0+ (1.000000,0.000000) [0.000000|1.000000] ""  Logger
 SG_ BTCell038InError m38 : 15|1@0+ (1.000000,0.000000) [0.000000|1.000000] ""  Logger
 SG_ BTCell039InError m39 : 15|1@0+ (1.000000,0.000000) [0.000000|1.000000] ""  Logger
 SG_ BTCell040InError m40 : 15|1@0+ (1.000000,0.000000) [0.000000|1.000000] ""  Logger
 SG_ BTCell041InError m41 : 15|1@0+ (1.000000,0.000000) [0.000000|1.000000] ""  Logger
 SG_ BTCell042InError m42 : 15|1@0+ (1.000000,0.000000) [0.000000|1.000000] ""  Logger
 SG_ BTCell043InError m43 : 15|1@0+ (1.000000,0.000000) [0.000000|1.000000] ""  Logger
 SG_ BTCell044InError m44 : 15|1@0+ (1.000000,0.000000) [0.000000|1.000000] ""  Logger
 SG_ BTCell045InError m45 : 15|1@0+ (1.000000,0.000000) [0.000000|1.000000] ""  Logger
 SG_ BTCell046InError m46 : 15|1@0+ (1.000000,0.000000) [0.000000|1.000000] ""  Logger
 SG_ BTCell047InError m47 : 15|1@0+ (1.000000,0.000000) [0.000000|1.000000] ""  Logger
 SG_ BTCell048InError m48 : 15|1@0+ (1.000000,0.000000) [0.000000|1.000000] ""  Logger
 SG_ BTCell049InError m49 : 15|1@0+ (1.000000,0.000000) [0.000000|1.000000] ""  Logger
 SG_ BTCell050InError m50 : 15|1@0+ (1.000000,0.000000) [0.000000|1.000000] ""  Logger
 SG_ BTCell051InError m51 : 15|1@0+ (1.000000,0.000000) [0.000000|1.000000] ""  Logger
 SG_ BTCell052InError m52 : 15|1@0+ (1.000000,0.000000) [0.000000|1.000000] ""  Logger
 SG_ BTCell053InError m53 : 15|1@0+ (1.000000,0.000000) [0.000000|1.000000] ""  Logger
 SG_ BTCell054InError m54 : 15|1@0+ (1.000000,0.000000) [0.000000|1.000000] ""  Logger
 SG_ BTCell055InError m55 : 15|1@0+ (1.000000,0.000000) [0.000000|1.000000] ""  Logger
 SG_ BTCell056InError m56 : 15|1@0+ (1.000000,0.000000) [0.000000|1.000000] ""  Logger
 SG_ BTCell057InError m57 : 15|1@0+ (1.000000,0.000000) [0.000000|1.000000] ""  Logger
 SG_ BTCell058InError m58 : 15|1@0+ (1.000000,0.000000) [0.000000|1.000000] ""  Logger
 SG_ BTCell059InError m59 : 15|1@0+ (1.000000,0.000000) [0.000000|1.000000] ""  Logger
 SG_ BTCell060InError m60 : 15|1@0+ (1.000000,0.000000) [0.000000|1.000000] ""  Logger
 SG_ BTCell061InError m61 : 15|1@0+ (1.000000,0.000000) [0.000000|1.000000] ""  Logger
 SG_ BTCell062InError m62 : 15|1@0+ (1.000000,0.000000) [0.000000|1.000000] ""  Logger
 SG_ BTCell063InError m63 : 15|1@0+ (1.000000,0.000000) [0.000000|1.000000] ""  Logger
 SG_ BTCell064InError m64 : 15|1@0+ (1.000000,0.000000) [0.000000|1.000000] ""  Logger
 SG_ BTCell065InError m65 : 15|1@0+ (1.000000,0.000000) [0.000000|1.000000] ""  Logger
 SG_ BTCell066InError m66 : 15|1@0+ (1.000000,0.000000) [0.000000|1.000000] ""  Logger
 SG_ BTCell067InError m67 : 15|1@0+ (1.000000,0.000000) [0.000000|1.000000] ""  Logger
 SG_ BTCell068InError m68 : 15|1@0+ (1.000000,0.000000) [0.000000|1.000000] ""  Logger
 SG_ BTCell069InError m69 : 15|1@0+ (1.000000,0.000000) [0.000000|1.000000] ""  Logger
 SG_ BTCell070InError m70 : 15|1@0+ (1.000000,0.000000) [0.000000|1.000000] ""  Logger
 SG_ BTCell071InError m71 : 15|1@0+ (1.000000,0.000000) [0.000000|1.000000] ""  Logger
 SG_ BTCell072InError m72 : 15|1@0+ (1.000000,0.000000) [0.000000|1.000000] ""  Logger
 SG_ BTCell073InError m73 : 15|1@0+ (1.000000,0.000000) [0.000000|1.000000] ""  Logger
 SG_ BTCell074InError m74 : 15|1@0+ (1.000000,0.000000) [0.000000|1.000000] ""  Logger
 SG_ BTCell075InError m75 : 15|1@0+ (1.000000,0.000000) [0.000000|1.000000] ""  Logger
 SG_ BTCell076InError m76 : 15|1@0+ (1.000000,0.000000) [0.000000|1.000000] ""  Logger
 SG_ BTCell077InError m77 : 15|1@0+ (1.000000,0.000000) [0.000000|1.000000] ""  Logger
 SG_ BTCell078InError m78 : 15|1@0+ (1.000000,0.000000) [0.000000|1.000000] ""  Logger
 SG_ BTCell079InError m79 : 15|1@0+ (1.000000,0.000000) [0.000000|1.000000] ""  Logger
 SG_ BTCell080InError m80 : 15|1@0+ (1.000000,0.000000) [0.000000|1.000000] ""  Logger
 SG_ BTCell081InError m81 : 15|1@0+ (1.000000,0.000000) [0.000000|1.000000] ""  Logger
 SG_ BTCell082InError m82 : 15|1@0+ (1.000000,0.000000) [0.000000|1.000000] ""  Logger
 SG_ BTCell083InError m83 : 15|1@0+ (1.000000,0.000000) [0.000000|1.000000] ""  Logger
 SG_ BTCell084InError m84 : 15|1@0+ (1.000000,0.000000) [0.000000|1.000000] ""  Logger
 SG_ BTCell085InError m85 : 15|1@0+ (1.000000,0.000000) [0.000000|1.000000] ""  Logger
 SG_ BTCell086InError m86 : 15|1@0+ (1.000000,0.000000) [0.000000|1.000000] ""  Logger
 SG_ BTCell087InError m87 : 15|1@0+ (1.000000,0.000000) [0.000000|1.000000] ""  Logger
 SG_ BTCell088InError m88 : 15|1@0+ (1.000000,0.000000) [0.000000|1.000000] ""  Logger
 SG_ BTCell001Simulated m1 : 14|1@0+ (1.000000,0.000000) [0.000000|1.000000] ""  Logger
 SG_ BTCell002Simulated m2 : 14|1@0+ (1.000000,0.000000) [0.000000|1.000000] ""  Logger
 SG_ BTCell003Simulated m3 : 14|1@0+ (1.000000,0.000000) [0.000000|1.000000] ""  Logger
 SG_ BTCell004Simulated m4 : 14|1@0+ (1.000000,0.000000) [0.000000|1.000000] ""  Logger
 SG_ BTCell005Simulated m5 : 14|1@0+ (1.000000,0.000000) [0.000000|1.000000] ""  Logger
 SG_ BTCell006Simulated m6 : 14|1@0+ (1.000000,0.000000) [0.000000|1.000000] ""  Logger
 SG_ BTCell007Simulated m7 : 14|1@0+ (1.000000,0.000000) [0.000000|1.000000] ""  Logger
 SG_ BTCell008Simulated m8 : 14|1@0+ (1.000000,0.000000) [0.000000|1.000000] ""  Logger
 SG_ BTCell009Simulated m9 : 14|1@0+ (1.000000,0.000000) [0.000000|1.000000] ""  Logger
 SG_ BTCell010Simulated m10 : 14|1@0+ (1.000000,0.000000) [0.000000|1.000000] ""  Logger
 SG_ BTCell011Simulated m11 : 14|1@0+ (1.000000,0.000000) [0.000000|1.000000] ""  Logger
 SG_ BTCell012Simulated m12 : 14|1@0+ (1.000000,0.000000) [0.000000|1.000000] ""  Logger
 SG_ BTCell013Simulated m13 : 14|1@0+ (1.000000,0.000000) [0.000000|1.000000] ""  Logger
 SG_ BTCell014Simulated m14 : 14|1@0+ (1.000000,0.000000) [0.000000|1.000000] ""  Logger
 SG_ BTCell015Simulated m15 : 14|1@0+ (1.000000,0.000000) [0.000000|1.000000] ""  Logger
 SG_ BTCell016Simulated m16 : 14|1@0+ (1.000000,0.000000) [0.000000|1.000000] ""  Logger
 SG_ BTCell017Simulated m17 : 14|1@0+ (1.000000,0.000000) [0.000000|1.000000] ""  Logger
 SG_ BTCell018Simulated m18 : 14|1@0+ (1.000000,0.000000) [0.000000|1.000000] ""  Logger
 SG_ BTCell019Simulated m19 : 14|1@0+ (1.000000,0.000000) [0.000000|1.000000] ""  Logger
 SG_ BTCell020Simulated m20 : 14|1@0+ (1.000000,0.000000) [0.000000|1.000000] ""  Logger
 SG_ BTCell021Simulated m21 : 14|1@0+ (1.000000,0.000000) [0.000000|1.000000] ""  Logger
 SG_ BTCell022Simulated m22 : 14|1@0+ (1.000000,0.000000) [0.000000|1.000000] ""  Logger
 SG_ BTCell023Simulated m23 : 14|1@0+ (1.000000,0.000000) [0.000000|1.000000] ""  Logger
 SG_ BTCell024Simulated m24 : 14|1@0+ (1.000000,0.000000) [0.000000|1.000000] ""  Logger
 SG_ BTCell025Simulated m25 : 14|1@0+ (1.000000,0.000000) [0.000000|1.000000] ""  Logger
 SG_ BTCell026Simulated m26 : 14|1@0+ (1.000000,0.000000) [0.000000|1.000000] ""  Logger
 SG_ BTCell027Simulated m27 : 14|1@0+ (1.000000,0.000000) [0.000000|1.000000] ""  Logger
 SG_ BTCell028Simulated m28 : 14|1@0+ (1.000000,0.000000) [0.000000|1.000000] ""  Logger
 SG_ BTCell029Simulated m29 : 14|1@0+ (1.000000,0.000000) [0.000000|1.000000] ""  Logger
 SG_ BTCell030Simulated m30 : 14|1@0+ (1.000000,0.000000) [0.000000|1.000000] ""  Logger
 SG_ BTCell031Simulated m31 : 14|1@0+ (1.000000,0.000000) [0.000000|1.000000] ""  Logger
 SG_ BTCell032Simulated m32 : 14|1@0+ (1.000000,0.000000) [0.000000|1.000000] ""  Logger
 SG_ BTCell033Simulated m33 : 14|1@0+ (1.000000,0.000000) [0.000000|1.000000] ""  Logger
 SG_ BTCell034Simulated m34 : 14|1@0+ (1.000000,0.000000) [0.000000|1.000000] ""  Logger
 SG_ BTCell035Simulated m35 : 14|1@0+ (1.000000,0.000000) [0.000000|1.000000] ""  Logger
 SG_ BTCell036Simulated m36 : 14|1@0+ (1.000000,0.000000) [0.000000|1.000000] ""  Logger
 SG_ BTCell037Simulated m37 : 14|1@0+ (1.000000,0.000000) [0.000000|1.000000] ""  Logger
 SG_ BTCell038Simulated m38 : 14|1@0+ (1.000000,0.000000) [0.000000|1.000000] ""  Logger
 SG_ BTCell039Simulated m39 : 14|1@0+ (1.000000,0.000000) [0.000000|1.000000] ""  Logger
 SG_ BTCell040Simulated m40 : 14|1@0+ (1.000000,0.000000) [0.000000|1.000000] ""  Logger
 SG_ BTCell041Simulated m41 : 14|1@0+ (1.000000,0.000000) [0.000000|1.000000] ""  Logger
 SG_ BTCell042Simulated m42 : 14|1@0+ (1.000000,0.000000) [0.000000|1.000000] ""  Logger
 SG_ BTCell043Simulated m43 : 14|1@0+ (1.000000,0.000000) [0.000000|1.000000] ""  Logger
 SG_ BTCell044Simulated m44 : 14|1@0+ (1.000000,0.000000) [0.000000|1.000000] ""  Logger
 SG_ BTCell045Simulated m45 : 14|1@0+ (1.000000,0.000000) [0.000000|1.000000] ""  Logger
 SG_ BTCell046Simulated m46 : 14|1@0+ (1.000000,0.000000) [0.000000|1.000000] ""  Logger
 SG_ BTCell047Simulated m47 : 14|1@0+ (1.000000,0.000000) [0.000000|1.000000] ""  Logger
 SG_ BTCell048Simulated m48 : 14|1@0+ (1.000000,0.000000) [0.000000|1.000000] ""  Logger
 SG_ BTCell049Simulated m49 : 14|1@0+ (1.000000,0.000000) [0.000000|1.000000] ""  Logger
 SG_ BTCell050Simulated m50 : 14|1@0+ (1.000000,0.000000) [0.000000|1.000000] ""  Logger
 SG_ BTCell051Simulated m51 : 14|1@0+ (1.000000,0.000000) [0.000000|1.000000] ""  Logger
 SG_ BTCell052Simulated m52 : 14|1@0+ (1.000000,0.000000) [0.000000|1.000000] ""  Logger
 SG_ BTCell053Simulated m53 : 14|1@0+ (1.000000,0.000000) [0.000000|1.000000] ""  Logger
 SG_ BTCell054Simulated m54 : 14|1@0+ (1.000000,0.000000) [0.000000|1.000000] ""  Logger
 SG_ BTCell055Simulated m55 : 14|1@0+ (1.000000,0.000000) [0.000000|1.000000] ""  Logger
 SG_ BTCell056Simulated m56 : 14|1@0+ (1.000000,0.000000) [0.000000|1.000000] ""  Logger
 SG_ BTCell057Simulated m57 : 14|1@0+ (1.000000,0.000000) [0.000000|1.000000] ""  Logger
 SG_ BTCell058Simulated m58 : 14|1@0+ (1.000000,0.000000) [0.000000|1.000000] ""  Logger
 SG_ BTCell059Simulated m59 : 14|1@0+ (1.000000,0.000000) [0.000000|1.000000] ""  Logger
 SG_ BTCell060Simulated m60 : 14|1@0+ (1.000000,0.000000) [0.000000|1.000000] ""  Logger
 SG_ BTCell061Simulated m61 : 14|1@0+ (1.000000,0.000000) [0.000000|1.000000] ""  Logger
 SG_ BTCell062Simulated m62 : 14|1@0+ (1.000000,0.000000) [0.000000|1.000000] ""  Logger
 SG_ BTCell063Simulated m63 : 14|1@0+ (1.000000,0.000000) [0.000000|1.000000] ""  Logger
 SG_ BTCell064Simulated m64 : 14|1@0+ (1.000000,0.000000) [0.000000|1.000000] ""  Logger
 SG_ BTCell065Simulated m65 : 14|1@0+ (1.000000,0.000000) [0.000000|1.000000] ""  Logger
 SG_ BTCell066Simulated m66 : 14|1@0+ (1.000000,0.000000) [0.000000|1.000000] ""  Logger
 SG_ BTCell067Simulated m67 : 14|1@0+ (1.000000,0.000000) [0.000000|1.000000] ""  Logger
 SG_ BTCell068Simulated m68 : 14|1@0+ (1.000000,0.000000) [0.000000|1.000000] ""  Logger
 SG_ BTCell069Simulated m69 : 14|1@0+ (1.000000,0.000000) [0.000000|1.000000] ""  Logger
 SG_ BTCell070Simulated m70 : 14|1@0+ (1.000000,0.000000) [0.000000|1.000000] ""  Logger
 SG_ BTCell071Simulated m71 : 14|1@0+ (1.000000,0.000000) [0.000000|1.000000] ""  Logger
 SG_ BTCell072Simulated m72 : 14|1@0+ (1.000000,0.000000) [0.000000|1.000000] ""  Logger
 SG_ BTCell073Simulated m73 : 14|1@0+ (1.000000,0.000000) [0.000000|1.000000] ""  Logger
 SG_ BTCell074Simulated m74 : 14|1@0+ (1.000000,0.000000) [0.000000|1.000000] ""  Logger
 SG_ BTCell075Simulated m75 : 14|1@0+ (1.000000,0.000000) [0.000000|1.000000] ""  Logger
 SG_ BTCell076Simulated m76 : 14|1@0+ (1.000000,0.000000) [0.000000|1.000000] ""  Logger
 SG_ BTCell077Simulated m77 : 14|1@0+ (1.000000,0.000000) [0.000000|1.000000] ""  Logger
 SG_ BTCell078Simulated m78 : 14|1@0+ (1.000000,0.000000) [0.000000|1.000000] ""  Logger
 SG_ BTCell079Simulated m79 : 14|1@0+ (1.000000,0.000000) [0.000000|1.000000] ""  Logger
 SG_ BTCell080Simulated m80 : 14|1@0+ (1.000000,0.000000) [0.000000|1.000000] ""  Logger
 SG_ BTCell081Simulated m81 : 14|1@0+ (1.000000,0.000000) [0.000000|1.000000] ""  Logger
 SG_ BTCell082Simulated m82 : 14|1@0+ (1.000000,0.000000) [0.000000|1.000000] ""  Logger
 SG_ BTCell083Simulated m83 : 14|1@0+ (1.000000,0.000000) [0.000000|1.000000] ""  Logger
 SG_ BTCell084Simulated m84 : 14|1@0+ (1.000000,0.000000) [0.000000|1.000000] ""  Logger
 SG_ BTCell085Simulated m85 : 14|1@0+ (1.000000,0.000000) [0.000000|1.000000] ""  Logger
 SG_ BTCell086Simulated m86 : 14|1@0+ (1.000000,0.000000) [0.000000|1.000000] ""  Logger
 SG_ BTCell087Simulated m87 : 14|1@0+ (1.000000,0.000000) [0.000000|1.000000] ""  Logger
 SG_ BTCell088Simulated m88 : 14|1@0+ (1.000000,0.000000) [0.000000|1.000000] ""  Logger
 SG_ NTConversionMethodCell001 m1 : 13|2@0+ (1.000000,0.000000) [0.000000|3.000000] ""  Logger
 SG_ NTConversionMethodCell002 m2 : 13|2@0+ (1.000000,0.000000) [0.000000|3.000000] ""  Logger
 SG_ NTConversionMethodCell003 m3 : 13|2@0+ (1.000000,0.000000) [0.000000|3.000000] ""  Logger
 SG_ NTConversionMethodCell004 m4 : 13|2@0+ (1.000000,0.000000) [0.000000|3.000000] ""  Logger
 SG_ NTConversionMethodCell005 m5 : 13|2@0+ (1.000000,0.000000) [0.000000|3.000000] ""  Logger
 SG_ NTConversionMethodCell006 m6 : 13|2@0+ (1.000000,0.000000) [0.000000|3.000000] ""  Logger
 SG_ NTConversionMethodCell007 m7 : 13|2@0+ (1.000000,0.000000) [0.000000|3.000000] ""  Logger
 SG_ NTConversionMethodCell008 m8 : 13|2@0+ (1.000000,0.000000) [0.000000|3.000000] ""  Logger
 SG_ NTConversionMethodCell009 m9 : 13|2@0+ (1.000000,0.000000) [0.000000|3.000000] ""  Logger
 SG_ NTConversionMethodCell010 m10 : 13|2@0+ (1.000000,0.000000) [0.000000|3.000000] ""  Logger
 SG_ NTConversionMethodCell011 m11 : 13|2@0+ (1.000000,0.000000) [0.000000|3.000000] ""  Logger
 SG_ NTConversionMethodCell012 m12 : 13|2@0+ (1.000000,0.000000) [0.000000|3.000000] ""  Logger
 SG_ NTConversionMethodCell013 m13 : 13|2@0+ (1.000000,0.000000) [0.000000|3.000000] ""  Logger
 SG_ NTConversionMethodCell014 m14 : 13|2@0+ (1.000000,0.000000) [0.000000|3.000000] ""  Logger
 SG_ NTConversionMethodCell015 m15 : 13|2@0+ (1.000000,0.000000) [0.000000|3.000000] ""  Logger
 SG_ NTConversionMethodCell016 m16 : 13|2@0+ (1.000000,0.000000) [0.000000|3.000000] ""  Logger
 SG_ NTConversionMethodCell017 m17 : 13|2@0+ (1.000000,0.000000) [0.000000|3.000000] ""  Logger
 SG_ NTConversionMethodCell018 m18 : 13|2@0+ (1.000000,0.000000) [0.000000|3.000000] ""  Logger
 SG_ NTConversionMethodCell019 m19 : 13|2@0+ (1.000000,0.000000) [0.000000|3.000000] ""  Logger
 SG_ NTConversionMethodCell020 m20 : 13|2@0+ (1.000000,0.000000) [0.000000|3.000000] ""  Logger
 SG_ NTConversionMethodCell021 m21 : 13|2@0+ (1.000000,0.000000) [0.000000|3.000000] ""  Logger
 SG_ NTConversionMethodCell022 m22 : 13|2@0+ (1.000000,0.000000) [0.000000|3.000000] ""  Logger
 SG_ NTConversionMethodCell023 m23 : 13|2@0+ (1.000000,0.000000) [0.000000|3.000000] ""  Logger
 SG_ NTConversionMethodCell024 m24 : 13|2@0+ (1.000000,0.000000) [0.000000|3.000000] ""  Logger
 SG_ NTConversionMethodCell025 m25 : 13|2@0+ (1.000000,0.000000) [0.000000|3.000000] ""  Logger
 SG_ NTConversionMethodCell026 m26 : 13|2@0+ (1.000000,0.000000) [0.000000|3.000000] ""  Logger
 SG_ NTConversionMethodCell027 m27 : 13|2@0+ (1.000000,0.000000) [0.000000|3.000000] ""  Logger
 SG_ NTConversionMethodCell028 m28 : 13|2@0+ (1.000000,0.000000) [0.000000|3.000000] ""  Logger
 SG_ NTConversionMethodCell029 m29 : 13|2@0+ (1.000000,0.000000) [0.000000|3.000000] ""  Logger
 SG_ NTConversionMethodCell030 m30 : 13|2@0+ (1.000000,0.000000) [0.000000|3.000000] ""  Logger
 SG_ NTConversionMethodCell031 m31 : 13|2@0+ (1.000000,0.000000) [0.000000|3.000000] ""  Logger
 SG_ NTConversionMethodCell032 m32 : 13|2@0+ (1.000000,0.000000) [0.000000|3.000000] ""  Logger
 SG_ NTConversionMethodCell033 m33 : 13|2@0+ (1.000000,0.000000) [0.000000|3.000000] ""  Logger
 SG_ NTConversionMethodCell034 m34 : 13|2@0+ (1.000000,0.000000) [0.000000|3.000000] ""  Logger
 SG_ NTConversionMethodCell035 m35 : 13|2@0+ (1.000000,0.000000) [0.000000|3.000000] ""  Logger
 SG_ NTConversionMethodCell036 m36 : 13|2@0+ (1.000000,0.000000) [0.000000|3.000000] ""  Logger
 SG_ NTConversionMethodCell037 m37 : 13|2@0+ (1.000000,0.000000) [0.000000|3.000000] ""  Logger
 SG_ NTConversionMethodCell038 m38 : 13|2@0+ (1.000000,0.000000) [0.000000|3.000000] ""  Logger
 SG_ NTConversionMethodCell039 m39 : 13|2@0+ (1.000000,0.000000) [0.000000|3.000000] ""  Logger
 SG_ NTConversionMethodCell040 m40 : 13|2@0+ (1.000000,0.000000) [0.000000|3.000000] ""  Logger
 SG_ NTConversionMethodCell041 m41 : 13|2@0+ (1.000000,0.000000) [0.000000|3.000000] ""  Logger
 SG_ NTConversionMethodCell042 m42 : 13|2@0+ (1.000000,0.000000) [0.000000|3.000000] ""  Logger
 SG_ NTConversionMethodCell043 m43 : 13|2@0+ (1.000000,0.000000) [0.000000|3.000000] ""  Logger
 SG_ NTConversionMethodCell044 m44 : 13|2@0+ (1.000000,0.000000) [0.000000|3.000000] ""  Logger
 SG_ NTConversionMethodCell045 m45 : 13|2@0+ (1.000000,0.000000) [0.000000|3.000000] ""  Logger
 SG_ NTConversionMethodCell046 m46 : 13|2@0+ (1.000000,0.000000) [0.000000|3.000000] ""  Logger
 SG_ NTConversionMethodCell047 m47 : 13|2@0+ (1.000000,0.000000) [0.000000|3.000000] ""  Logger
 SG_ NTConversionMethodCell048 m48 : 13|2@0+ (1.000000,0.000000) [0.000000|3.000000] ""  Logger
 SG_ NTConversionMethodCell049 m49 : 13|2@0+ (1.000000,0.000000) [0.000000|3.000000] ""  Logger
 SG_ NTConversionMethodCell050 m50 : 13|2@0+ (1.000000,0.000000) [0.000000|3.000000] ""  Logger
 SG_ NTConversionMethodCell051 m51 : 13|2@0+ (1.000000,0.000000) [0.000000|3.000000] ""  Logger
 SG_ NTConversionMethodCell052 m52 : 13|2@0+ (1.000000,0.000000) [0.000000|3.000000] ""  Logger
 SG_ NTConversionMethodCell053 m53 : 13|2@0+ (1.000000,0.000000) [0.000000|3.000000] ""  Logger
 SG_ NTConversionMethodCell054 m54 : 13|2@0+ (1.000000,0.000000) [0.000000|3.000000] ""  Logger
 SG_ NTConversionMethodCell055 m55 : 13|2@0+ (1.000000,0.000000) [0.000000|3.000000] ""  Logger
 SG_ NTConversionMethodCell056 m56 : 13|2@0+ (1.000000,0.000000) [0.000000|3.000000] ""  Logger
 SG_ NTConversionMethodCell057 m57 : 13|2@0+ (1.000000,0.000000) [0.000000|3.000000] ""  Logger
 SG_ NTConversionMethodCell058 m58 : 13|2@0+ (1.000000,0.000000) [0.000000|3.000000] ""  Logger
 SG_ NTConversionMethodCell059 m59 : 13|2@0+ (1.000000,0.000000) [0.000000|3.000000] ""  Logger
 SG_ NTConversionMethodCell060 m60 : 13|2@0+ (1.000000,0.000000) [0.000000|3.000000] ""  Logger
 SG_ NTConversionMethodCell061 m61 : 13|2@0+ (1.000000,0.000000) [0.000000|3.000000] ""  Logger
 SG_ NTConversionMethodCell062 m62 : 13|2@0+ (1.000000,0.000000) [0.000000|3.000000] ""  Logger
 SG_ NTConversionMethodCell063 m63 : 13|2@0+ (1.000000,0.000000) [0.000000|3.000000] ""  Logger
 SG_ NTConversionMethodCell064 m64 : 13|2@0+ (1.000000,0.000000) [0.000000|3.000000] ""  Logger
 SG_ NTConversionMethodCell065 m65 : 13|2@0+ (1.000000,0.000000) [0.000000|3.000000] ""  Logger
 SG_ NTConversionMethodCell066 m66 : 13|2@0+ (1.000000,0.000000) [0.000000|3.000000] ""  Logger
 SG_ NTConversionMethodCell067 m67 : 13|2@0+ (1.000000,0.000000) [0.000000|3.000000] ""  Logger
 SG_ NTConversionMethodCell068 m68 : 13|2@0+ (1.000000,0.000000) [0.000000|3.000000] ""  Logger
 SG_ NTConversionMethodCell069 m69 : 13|2@0+ (1.000000,0.000000) [0.000000|3.000000] ""  Logger
 SG_ NTConversionMethodCell070 m70 : 13|2@0+ (1.000000,0.000000) [0.000000|3.000000] ""  Logger
 SG_ NTConversionMethodCell071 m71 : 13|2@0+ (1.000000,0.000000) [0.000000|3.000000] ""  Logger
 SG_ NTConversionMethodCell072 m72 : 13|2@0+ (1.000000,0.000000) [0.000000|3.000000] ""  Logger
 SG_ NTConversionMethodCell073 m73 : 13|2@0+ (1.000000,0.000000) [0.000000|3.000000] ""  Logger
 SG_ NTConversionMethodCell074 m74 : 13|2@0+ (1.000000,0.000000) [0.000000|3.000000] ""  Logger
 SG_ NTConversionMethodCell075 m75 : 13|2@0+ (1.000000,0.000000) [0.000000|3.000000] ""  Logger
 SG_ NTConversionMethodCell076 m76 : 13|2@0+ (1.000000,0.000000) [0.000000|3.000000] ""  Logger
 SG_ NTConversionMethodCell077 m77 : 13|2@0+ (1.000000,0.000000) [0.000000|3.000000] ""  Logger
 SG_ NTConversionMethodCell078 m78 : 13|2@0+ (1.000000,0.000000) [0.000000|3.000000] ""  Logger
 SG_ NTConversionMethodCell079 m79 : 13|2@0+ (1.000000,0.000000) [0.000000|3.000000] ""  Logger
 SG_ NTConversionMethodCell080 m80 : 13|2@0+ (1.000000,0.000000) [0.000000|3.000000] ""  Logger
 SG_ NTConversionMethodCell081 m81 : 13|2@0+ (1.000000,0.000000) [0.000000|3.000000] ""  Logger
 SG_ NTConversionMethodCell082 m82 : 13|2@0+ (1.000000,0.000000) [0.000000|3.000000] ""  Logger
 SG_ NTConversionMethodCell083 m83 : 13|2@0+ (1.000000,0.000000) [0.000000|3.000000] ""  Logger
 SG_ NTConversionMethodCell084 m84 : 13|2@0+ (1.000000,0.000000) [0.000000|3.000000] ""  Logger
 SG_ NTConversionMethodCell085 m85 : 13|2@0+ (1.000000,0.000000) [0.000000|3.000000] ""  Logger
 SG_ NTConversionMethodCell086 m86 : 13|2@0+ (1.000000,0.000000) [0.000000|3.000000] ""  Logger
 SG_ NTConversionMethodCell087 m87 : 13|2@0+ (1.000000,0.000000) [0.000000|3.000000] ""  Logger
 SG_ NTConversionMethodCell088 m88 : 13|2@0+ (1.000000,0.000000) [0.000000|3.000000] ""  Logger
 SG_ VTADCCell001 m1 : 11|16@0+ (0.000100,0.000000) [0.000000|6.553500] "V"  Logger
 SG_ VTADCCell002 m2 : 11|16@0+ (0.000100,0.000000) [0.000000|6.553500] "V"  Logger
 SG_ VTADCCell003 m3 : 11|16@0+ (0.000100,0.000000) [0.000000|6.553500] "V"  Logger
 SG_ VTADCCell004 m4 : 11|16@0+ (0.000100,0.000000) [0.000000|6.553500] "V"  Logger
 SG_ VTADCCell005 m5 : 11|16@0+ (0.000100,0.000000) [0.000000|6.553500] "V"  Logger
 SG_ VTADCCell006 m6 : 11|16@0+ (0.000100,0.000000) [0.000000|6.553500] "V"  Logger
 SG_ VTADCCell007 m7 : 11|16@0+ (0.000100,0.000000) [0.000000|6.553500] "V"  Logger
 SG_ VTADCCell008 m8 : 11|16@0+ (0.000100,0.000000) [0.000000|6.553500] "V"  Logger
 SG_ VTADCCell009 m9 : 11|16@0+ (0.000100,0.000000) [0.000000|6.553500] "V"  Logger
 SG_ VTADCCell010 m10 : 11|16@0+ (0.000100,0.000000) [0.000000|6.553500] "V"  Logger
 SG_ VTADCCell011 m11 : 11|16@0+ (0.000100,0.000000) [0.000000|6.553500] "V"  Logger
 SG_ VTADCCell012 m12 : 11|16@0+ (0.000100,0.000000) [0.000000|6.553500] "V"  Logger
 SG_ VTADCCell013 m13 : 11|16@0+ (0.000100,0.000000) [0.000000|6.553500] "V"  Logger
 SG_ VTADCCell014 m14 : 11|16@0+ (0.000100,0.000000) [0.000000|6.553500] "V"  Logger
 SG_ VTADCCell015 m15 : 11|16@0+ (0.000100,0.000000) [0.000000|6.553500] "V"  Logger
 SG_ VTADCCell016 m16 : 11|16@0+ (0.000100,0.000000) [0.000000|6.553500] "V"  Logger
 SG_ VTADCCell017 m17 : 11|16@0+ (0.000100,0.000000) [0.000000|6.553500] "V"  Logger
 SG_ VTADCCell018 m18 : 11|16@0+ (0.000100,0.000000) [0.000000|6.553500] "V"  Logger
 SG_ VTADCCell019 m19 : 11|16@0+ (0.000100,0.000000) [0.000000|6.553500] "V"  Logger
 SG_ VTADCCell020 m20 : 11|16@0+ (0.000100,0.000000) [0.000000|6.553500] "V"  Logger
 SG_ VTADCCell021 m21 : 11|16@0+ (0.000100,0.000000) [0.000000|6.553500] "V"  Logger
 SG_ VTADCCell022 m22 : 11|16@0+ (0.000100,0.000000) [0.000000|6.553500] "V"  Logger
 SG_ VTADCCell023 m23 : 11|16@0+ (0.000100,0.000000) [0.000000|6.553500] "V"  Logger
 SG_ VTADCCell024 m24 : 11|16@0+ (0.000100,0.000000) [0.000000|6.553500] "V"  Logger
 SG_ VTADCCell025 m25 : 11|16@0+ (0.000100,0.000000) [0.000000|6.553500] "V"  Logger
 SG_ VTADCCell026 m26 : 11|16@0+ (0.000100,0.000000) [0.000000|6.553500] "V"  Logger
 SG_ VTADCCell027 m27 : 11|16@0+ (0.000100,0.000000) [0.000000|6.553500] "V"  Logger
 SG_ VTADCCell028 m28 : 11|16@0+ (0.000100,0.000000) [0.000000|6.553500] "V"  Logger
 SG_ VTADCCell029 m29 : 11|16@0+ (0.000100,0.000000) [0.000000|6.553500] "V"  Logger
 SG_ VTADCCell030 m30 : 11|16@0+ (0.000100,0.000000) [0.000000|6.553500] "V"  Logger
 SG_ VTADCCell031 m31 : 11|16@0+ (0.000100,0.000000) [0.000000|6.553500] "V"  Logger
 SG_ VTADCCell032 m32 : 11|16@0+ (0.000100,0.000000) [0.000000|6.553500] "V"  Logger
 SG_ VTADCCell033 m33 : 11|16@0+ (0.000100,0.000000) [0.000000|6.553500] "V"  Logger
 SG_ VTADCCell034 m34 : 11|16@0+ (0.000100,0.000000) [0.000000|6.553500] "V"  Logger
 SG_ VTADCCell035 m35 : 11|16@0+ (0.000100,0.000000) [0.000000|6.553500] "V"  Logger
 SG_ VTADCCell036 m36 : 11|16@0+ (0.000100,0.000000) [0.000000|6.553500] "V"  Logger
 SG_ VTADCCell037 m37 : 11|16@0+ (0.000100,0.000000) [0.000000|6.553500] "V"  Logger
 SG_ VTADCCell038 m38 : 11|16@0+ (0.000100,0.000000) [0.000000|6.553500] "V"  Logger
 SG_ VTADCCell039 m39 : 11|16@0+ (0.000100,0.000000) [0.000000|6.553500] "V"  Logger
 SG_ VTADCCell040 m40 : 11|16@0+ (0.000100,0.000000) [0.000000|6.553500] "V"  Logger
 SG_ VTADCCell041 m41 : 11|16@0+ (0.000100,0.000000) [0.000000|6.553500] "V"  Logger
 SG_ VTADCCell042 m42 : 11|16@0+ (0.000100,0.000000) [0.000000|6.553500] "V"  Logger
 SG_ VTADCCell043 m43 : 11|16@0+ (0.000100,0.000000) [0.000000|6.553500] "V"  Logger
 SG_ VTADCCell044 m44 : 11|16@0+ (0.000100,0.000000) [0.000000|6.553500] "V"  Logger
 SG_ VTADCCell045 m45 : 11|16@0+ (0.000100,0.000000) [0.000000|6.553500] "V"  Logger
 SG_ VTADCCell046 m46 : 11|16@0+ (0.000100,0.000000) [0.000000|6.553500] "V"  Logger
 SG_ VTADCCell047 m47 : 11|16@0+ (0.000100,0.000000) [0.000000|6.553500] "V"  Logger
 SG_ VTADCCell048 m48 : 11|16@0+ (0.000100,0.000000) [0.000000|6.553500] "V"  Logger
 SG_ VTADCCell049 m49 : 11|16@0+ (0.000100,0.000000) [0.000000|6.553500] "V"  Logger
 SG_ VTADCCell050 m50 : 11|16@0+ (0.000100,0.000000) [0.000000|6.553500] "V"  Logger
 SG_ VTADCCell051 m51 : 11|16@0+ (0.000100,0.000000) [0.000000|6.553500] "V"  Logger
 SG_ VTADCCell052 m52 : 11|16@0+ (0.000100,0.000000) [0.000000|6.553500] "V"  Logger
 SG_ VTADCCell053 m53 : 11|16@0+ (0.000100,0.000000) [0.000000|6.553500] "V"  Logger
 SG_ VTADCCell054 m54 : 11|16@0+ (0.000100,0.000000) [0.000000|6.553500] "V"  Logger
 SG_ VTADCCell055 m55 : 11|16@0+ (0.000100,0.000000) [0.000000|6.553500] "V"  Logger
 SG_ VTADCCell056 m56 : 11|16@0+ (0.000100,0.000000) [0.000000|6.553500] "V"  Logger
 SG_ VTADCCell057 m57 : 11|16@0+ (0.000100,0.000000) [0.000000|6.553500] "V"  Logger
 SG_ VTADCCell058 m58 : 11|16@0+ (0.000100,0.000000) [0.000000|6.553500] "V"  Logger
 SG_ VTADCCell059 m59 : 11|16@0+ (0.000100,0.000000) [0.000000|6.553500] "V"  Logger
 SG_ VTADCCell060 m60 : 11|16@0+ (0.000100,0.000000) [0.000000|6.553500] "V"  Logger
 SG_ VTADCCell061 m61 : 11|16@0+ (0.000100,0.000000) [0.000000|6.553500] "V"  Logger
 SG_ VTADCCell062 m62 : 11|16@0+ (0.000100,0.000000) [0.000000|6.553500] "V"  Logger
 SG_ VTADCCell063 m63 : 11|16@0+ (0.000100,0.000000) [0.000000|6.553500] "V"  Logger
 SG_ VTADCCell064 m64 : 11|16@0+ (0.000100,0.000000) [0.000000|6.553500] "V"  Logger
 SG_ VTADCCell065 m65 : 11|16@0+ (0.000100,0.000000) [0.000000|6.553500] "V"  Logger
 SG_ VTADCCell066 m66 : 11|16@0+ (0.000100,0.000000) [0.000000|6.553500] "V"  Logger
 SG_ VTADCCell067 m67 : 11|16@0+ (0.000100,0.000000) [0.000000|6.553500] "V"  Logger
 SG_ VTADCCell068 m68 : 11|16@0+ (0.000100,0.000000) [0.000000|6.553500] "V"  Logger
 SG_ VTADCCell069 m69 : 11|16@0+ (0.000100,0.000000) [0.000000|6.553500] "V"  Logger
 SG_ VTADCCell070 m70 : 11|16@0+ (0.000100,0.000000) [0.000000|6.553500] "V"  Logger
 SG_ VTADCCell071 m71 : 11|16@0+ (0.000100,0.000000) [0.000000|6.553500] "V"  Logger
 SG_ VTADCCell072 m72 : 11|16@0+ (0.000100,0.000000) [0.000000|6.553500] "V"  Logger
 SG_ VTADCCell073 m73 : 11|16@0+ (0.000100,0.000000) [0.000000|6.553500] "V"  Logger
 SG_ VTADCCell074 m74 : 11|16@0+ (0.000100,0.000000) [0.000000|6.553500] "V"  Logger
 SG_ VTADCCell075 m75 : 11|16@0+ (0.000100,0.000000) [0.000000|6.553500] "V"  Logger
 SG_ VTADCCell076 m76 : 11|16@0+ (0.000100,0.000000) [0.000000|6.553500] "V"  Logger
 SG_ VTADCCell077 m77 : 11|16@0+ (0.000100,0.000000) [0.000000|6.553500] "V"  Logger
 SG_ VTADCCell078 m78 : 11|16@0+ (0.000100,0.000000) [0.000000|6.553500] "V"  Logger
 SG_ VTADCCell079 m79 : 11|16@0+ (0.000100,0.000000) [0.000000|6.553500] "V"  Logger
 SG_ VTADCCell080 m80 : 11|16@0+ (0.000100,0.000000) [0.000000|6.553500] "V"  Logger
 SG_ VTADCCell081 m81 : 11|16@0+ (0.000100,0.000000) [0.000000|6.553500] "V"  Logger
 SG_ VTADCCell082 m82 : 11|16@0+ (0.000100,0.000000) [0.000000|6.553500] "V"  Logger
 SG_ VTADCCell083 m83 : 11|16@0+ (0.000100,0.000000) [0.000000|6.553500] "V"  Logger
 SG_ VTADCCell084 m84 : 11|16@0+ (0.000100,0.000000) [0.000000|6.553500] "V"  Logger
 SG_ VTADCCell085 m85 : 11|16@0+ (0.000100,0.000000) [0.000000|6.553500] "V"  Logger
 SG_ VTADCCell086 m86 : 11|16@0+ (0.000100,0.000000) [0.000000|6.553500] "V"  Logger
 SG_ VTADCCell087 m87 : 11|16@0+ (0.000100,0.000000) [0.000000|6.553500] "V"  Logger
 SG_ VTADCCell088 m88 : 11|16@0+ (0.000100,0.000000) [0.000000|6.553500] "V"  Logger
 SG_ rTHealthStack1 : 27|8@0+ (0.500000,0.000000) [0.000000|127.500000] "%"  Logger
 SG_ rTHealthStack2 : 35|8@0+ (0.500000,0.000000) [0.000000|127.500000] "%"  Logger
 SG_ rTHealthStack3 : 43|8@0+ (0.500000,0.000000) [0.000000|127.500000] "%"  Logger
 SG_ rTHealthStack4 : 51|8@0+ (0.500000,0.000000) [0.000000|127.500000] "%"  Logger

BO_ 1220 MinMaxDcCurrent: 8 Inverter
 SG_ MaxDcCurrent : 7|16@0- (0.100000,0.000000) [-3276.800000|3276.700000] "Adc"  Logger
 SG_ AvailableMaxDcCurrent : 23|16@0- (0.100000,0.000000) [-3276.800000|3276.700000] "Adc"  Logger
 SG_ MinDcCurrent : 39|16@0- (0.100000,0.000000) [-3276.800000|3276.700000] "Adc"  Logger
 SG_ AvailableMinDcCurrent : 55|16@0- (0.100000,0.000000) [-3276.800000|3276.700000] "Adc"  Logger

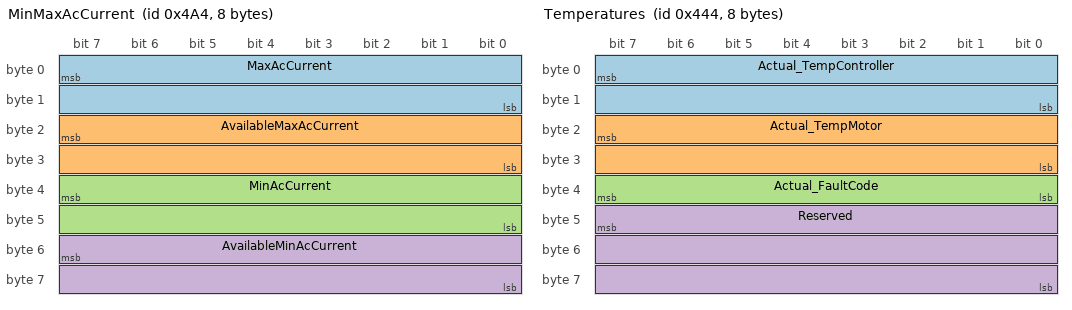
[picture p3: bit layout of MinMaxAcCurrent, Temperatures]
BO_ 1188 MinMaxAcCurrent: 8 Inverter
 SG_ MaxAcCurrent : 7|16@0- (0.100000,0.000000) [-3276.800000|3276.700000] "Apk"  Logger
 SG_ AvailableMaxAcCurrent : 23|16@0- (0.100000,0.000000) [-3276.800000|3276.700000] "Apk"  Logger
 SG_ MinAcCurrent : 39|16@0- (0.100000,0.000000) [-3276.800000|3276.700000] "Apk"  Logger
 SG_ AvailableMinAcCurrent : 55|16@0- (0.100000,0.000000) [-3276.800000|3276.700000] "Apk"  Logger

BO_ 1156 Inverter_MISC: 8 Inverter
 SG_ Actual_Throttle : 7|8@0- (1.000000,0.000000) [-128.000000|127.000000] "%"  Logger
 SG_ Actual_Brake : 15|8@0- (1.000000,0.000000) [-128.000000|127.000000] "%"  Logger
 SG_ Digital_output_4 : 23|1@0+ (1.000000,0.000000) [0.000000|1.000000] ""  Logger
 SG_ Digital_output_3 : 22|1@0+ (1.000000,0.000000) [0.000000|1.000000] ""  Logger
 SG_ Digital_output_2 : 21|1@0+ (1.000000,0.000000) [0.000000|1.000000] ""  Logger
 SG_ Digital_output_1 : 20|1@0+ (1.000000,0.000000) [0.000000|1.000000] ""  Logger
 SG_ Digital_input_4 : 19|1@0+ (1.000000,0.000000) [0.000000|1.000000] ""  Logger
 SG_ Digital_input_3 : 18|1@0+ (1.000000,0.000000) [0.000000|1.000000] ""  Logger
 SG_ Digital_input_2 : 17|1@0+ (1.000000,0.000000) [0.000000|1.000000] ""  Logger
 SG_ Digital_input_1 : 16|1@0+ (1.000000,0.000000) [0.000000|1.000000] ""  Logger
 SG_ Drive_enable : 31|8@0+ (1.000000,0.000000) [0.000000|255.000000] ""  Logger
 SG_ Motor_temp_limit : 39|1@0+ (1.000000,0.000000) [0.000000|1.000000] ""  Logger
 SG_ Motor_accel_limit : 38|1@0+ (1.000000,0.000000) [0.000000|1.000000] ""  Logger
 SG_ Input_voltage_limit : 37|1@0+ (1.000000,0.000000) [0.000000|1.000000] ""  Logger
 SG_ IGBT_temp_limit : 36|1@0+ (1.000000,0.000000) [0.000000|1.000000] ""  Logger
 SG_ IGBT_accel_limit : 35|1@0+ (1.000000,0.000000) [0.000000|1.000000] ""  Logger
 SG_ Drive_enable_limit : 34|1@0+ (1.000000,0.000000) [0.000000|1.000000] ""  Logger
 SG_ DC_current_limit : 33|1@0+ (1.000000,0.000000) [0.000000|1.000000] ""  Logger
 SG_ Capacitor_temp_limit : 32|1@0+ (1.000000,0.000000) [0.000000|1.000000] ""  Logger
 SG_ Power_limit : 47|1@0+ (1.000000,0.000000) [0.000000|1.000000] ""  Logger
 SG_ RPM_max_limit : 46|1@0+ (1.000000,0.000000) [0.000000|1.000000] ""  Logger
 SG_ RPM_min_limit : 45|1@0+ (1.000000,0.000000) [0.000000|1.000000] ""  Logger
 SG_ CAN_map_version : 44|8@0+ (0.100000,0.000000) [0.000000|25.500000] "Version"  Logger
 SG_ Reserved : 52|13@0+ (1.000000,0.000000) [0.000000|8191.000000] ""  Logger

BO_ 1124 FOC: 8 Inverter
 SG_ Actual_FOC_id : 7|32@0- (0.010000,0.000000) [-21474836.480000|21474836.470000] "Apk"  Logger
 SG_ Actual_FOC_iq : 39|32@0- (0.010000,0.000000) [-21474836.480000|21474836.470000] "Apk"  Logger

BO_ 1092 Temperatures: 8 Inverter
 SG_ Actual_TempController : 7|16@0- (0.100000,0.000000) [-3276.800000|3276.700000] "C"  Dash
 SG_ Actual_TempMotor : 23|16@0- (0.100000,0.000000) [-3276.800000|3276.700000] "C"  Dash
 SG_ Actual_FaultCode : 39|8@0+ (1.000000,0.000000) [0.000000|255.000000] ""  Dash
 SG_ Reserved : 47|24@0+ (1.000000,0.000000) [0.000000|16777215.000000] ""  Dash

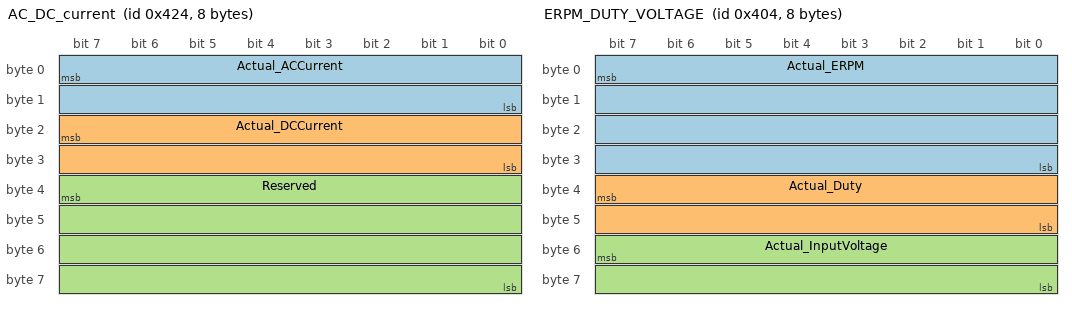
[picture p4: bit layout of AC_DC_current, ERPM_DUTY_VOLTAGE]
BO_ 1060 AC_DC_current: 8 Inverter
 SG_ Actual_ACCurrent : 7|16@0- (0.100000,0.000000) [-3276.800000|3276.700000] "Apk"  Logger
 SG_ Actual_DCCurrent : 23|16@0- (0.100000,0.000000) [-3276.800000|3276.700000] "A"  Logger
 SG_ Reserved : 39|32@0+ (1.000000,0.000000) [0.000000|4294967295.000000] ""  Logger

BO_ 1028 ERPM_DUTY_VOLTAGE: 8 Inverter
 SG_ Actual_ERPM : 7|32@0- (1.000000,0.000000) [-2147483648.000000|2147483647.000000] "ERPM"  Dash
 SG_ Actual_Duty : 39|16@0- (0.100000,0.000000) [-3276.800000|3276.700000] "%"  Dash
 SG_ Actual_InputVoltage : 55|16@0- (1.000000,0.000000) [-32768.000000|32767.000000] "V"  Dash

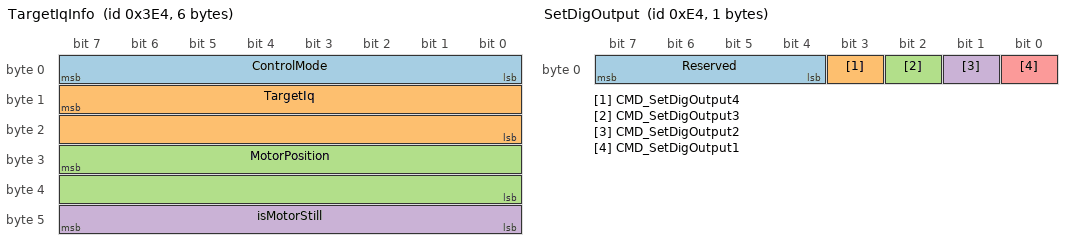
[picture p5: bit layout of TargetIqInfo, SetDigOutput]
BO_ 996 TargetIqInfo: 6 Inverter
 SG_ ControlMode : 7|8@0+ (1.000000,0.000000) [0.000000|255.000000] ""  Logger
 SG_ TargetIq : 15|16@0- (0.100000,0.000000) [-3276.800000|3276.700000] "Apk"  Logger
 SG_ MotorPosition : 31|16@0+ (0.100000,0.000000) [0.000000|6553.500000] "degree"  Logger
 SG_ isMotorStill : 47|8@0+ (1.000000,0.000000) [0.000000|255.000000] ""  Logger

BO_ 388 SetDriveEnable: 1 APPS
 SG_ CMD_DriveEnable : 7|8@0+ (1.000000,0.000000) [0.000000|255.000000] ""  Inverter

BO_ 356 SetMaxDcBrakeCurrent: 2 Dash
 SG_ CMD_MaxDcBrakeCurrent : 7|16@0- (0.100000,0.000000) [-3276.800000|3276.700000] "A"  Inverter

BO_ 324 SetMaxDcCurrent: 2 Dash
 SG_ CMD_MaxDcCurrent : 7|16@0- (0.100000,0.000000) [-3276.800000|3276.700000] "A"  Inverter

BO_ 292 SetMaxAcBrakeCurrent: 2 Dash
 SG_ CMD_MaxAcBrakeCurrent : 7|16@0- (0.100000,0.000000) [-3276.800000|3276.700000] "A"  Inverter

BO_ 260 SetMaxAcCurrent: 2 Dash
 SG_ CMD_MaxAcCurrent : 7|16@0- (0.100000,0.000000) [-3276.800000|3276.700000] "A"  Inverter

BO_ 228 SetDigOutput: 1 Dash
 SG_ Reserved : 7|4@0+ (1.000000,0.000000) [0.000000|15.000000] ""  Inverter
 SG_ CMD_SetDigOutput4 : 3|1@0+ (1.000000,0.000000) [0.000000|1.000000] ""  Inverter
 SG_ CMD_SetDigOutput3 : 2|1@0+ (1.000000,0.000000) [0.000000|1.000000] ""  Inverter
 SG_ CMD_SetDigOutput2 : 1|1@0+ (1.000000,0.000000) [0.000000|1.000000] ""  Inverter
 SG_ CMD_SetDigOutput1 : 0|1@0+ (1.000000,0.000000) [0.000000|1.000000] ""  Inverter

BO_ 178 PDUStats3: 4 PDU
 SG_ IAccuFan2 : 7|16@0+ (0.001000,0.000000) [0.000000|65.535000] "A"  Logger
 SG_ IHorn : 23|16@0+ (0.001000,0.000000) [0.000000|65.535000] "A"  Logger

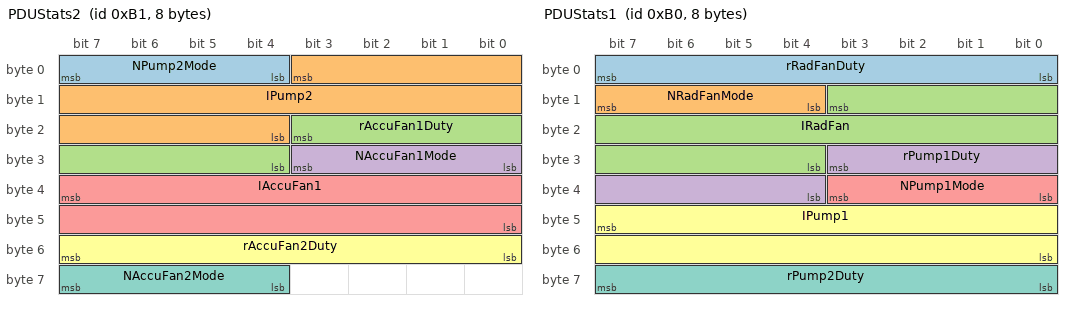
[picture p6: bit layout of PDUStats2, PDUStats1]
BO_ 177 PDUStats2: 8 PDU
 SG_ NPump2Mode : 7|4@0+ (1.000000,0.000000) [0.000000|15.000000] ""  Logger
 SG_ IPump2 : 3|16@0+ (0.001000,0.000000) [0.000000|65.535000] "A"  Logger
 SG_ rAccuFan1Duty : 19|8@0+ (1.000000,0.000000) [0.000000|255.000000] "%"  Logger
 SG_ NAccuFan1Mode : 27|4@0+ (1.000000,0.000000) [0.000000|15.000000] ""  Logger
 SG_ IAccuFan1 : 39|16@0+ (0.001000,0.000000) [0.000000|65.535000] "A"  Logger
 SG_ rAccuFan2Duty : 55|8@0+ (1.000000,0.000000) [0.000000|255.000000] "%"  Logger
 SG_ NAccuFan2Mode : 63|4@0+ (1.000000,0.000000) [0.000000|15.000000] ""  Logger

BO_ 176 PDUStats1: 8 PDU
 SG_ rRadFanDuty : 7|8@0+ (1.000000,0.000000) [0.000000|255.000000] "%"  Logger
 SG_ NRadFanMode : 15|4@0+ (1.000000,0.000000) [0.000000|15.000000] ""  Logger
 SG_ IRadFan : 11|16@0+ (0.001000,0.000000) [0.000000|65.535000] "A"  Logger
 SG_ rPump1Duty : 27|8@0+ (1.000000,0.000000) [0.000000|255.000000] "%"  Logger
 SG_ NPump1Mode : 35|4@0+ (1.000000,0.000000) [0.000000|15.000000] ""  Logger
 SG_ IPump1 : 47|16@0+ (0.001000,0.000000) [0.000000|65.535000] "A"  Logger
 SG_ rPump2Duty : 63|8@0+ (1.000000,0.000000) [0.000000|255.000000] "%"  Logger

BO_ 164 SetRelCurrent: 2 APPS
 SG_ CMD_TargetRelativeCurrent : 7|16@0- (0.100000,0.000000) [-3276.800000|3276.700000] "%"  Inverter

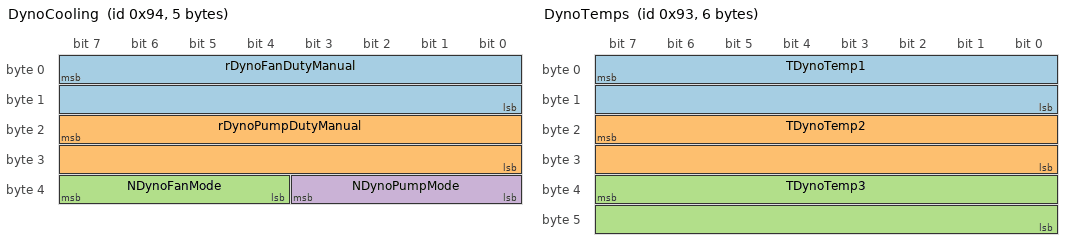
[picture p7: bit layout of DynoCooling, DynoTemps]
BO_ 148 DynoCooling: 5 Logger
 SG_ rDynoFanDutyManual : 7|16@0+ (0.002000,0.000000) [0.000000|131.070000] "%"  Dyno
 SG_ rDynoPumpDutyManual : 23|16@0+ (0.002000,0.000000) [0.000000|131.070000] "%"  Dyno
 SG_ NDynoFanMode : 39|4@0+ (1.000000,0.000000) [0.000000|15.000000] ""  Dyno
 SG_ NDynoPumpMode : 35|4@0+ (1.000000,0.000000) [0.000000|15.000000] ""  Dyno

BO_ 147 DynoTemps: 6 Dyno
 SG_ TDynoTemp1 : 7|16@0+ (0.005000,-30.000000) [-30.000000|297.675000] "degC"  Logger
 SG_ TDynoTemp2 : 23|16@0+ (0.005000,-30.000000) [-30.000000|297.675000] "degC"  Logger
 SG_ TDynoTemp3 : 39|16@0+ (0.005000,-30.000000) [-30.000000|297.675000] "degC"  Logger

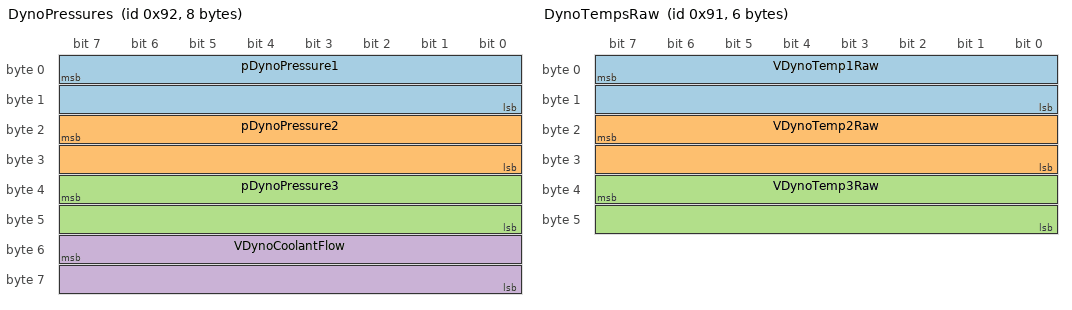
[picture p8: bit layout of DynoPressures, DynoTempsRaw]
BO_ 146 DynoPressures: 8 Dyno
 SG_ pDynoPressure1 : 7|16@0+ (0.000500,-6.000000) [-6.000000|26.767500] "Bar"  Logger
 SG_ pDynoPressure2 : 23|16@0+ (0.000500,-6.000000) [-6.000000|26.767500] "Bar"  Logger
 SG_ pDynoPressure3 : 39|16@0+ (0.000500,-6.000000) [-6.000000|26.767500] "Bar"  Logger
 SG_ VDynoCoolantFlow : 55|16@0+ (0.000010,0.000000) [0.000000|0.655350] "L/Min"  Logger

BO_ 145 DynoTempsRaw: 6 Dyno
 SG_ VDynoTemp1Raw : 7|16@0+ (0.000100,0.000000) [0.000000|6.553500] "V"  Logger
 SG_ VDynoTemp2Raw : 23|16@0+ (0.000100,0.000000) [0.000000|6.553500] "V"  Logger
 SG_ VDynoTemp3Raw : 39|16@0+ (0.000100,0.000000) [0.000000|6.553500] "V"  Logger

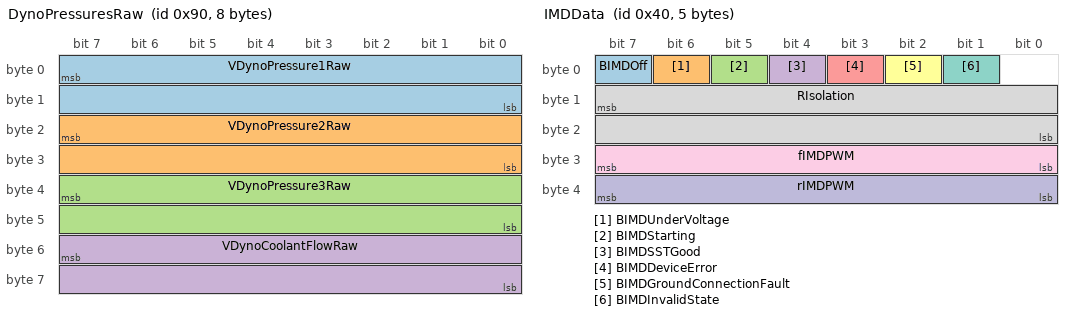
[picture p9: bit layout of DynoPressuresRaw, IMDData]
BO_ 144 DynoPressuresRaw: 8 Dyno
 SG_ VDynoPressure1Raw : 7|16@0+ (0.000100,0.000000) [0.000000|6.553500] "V"  Logger
 SG_ VDynoPressure2Raw : 23|16@0+ (0.000100,0.000000) [0.000000|6.553500] "V"  Logger
 SG_ VDynoPressure3Raw : 39|16@0+ (0.000100,0.000000) [0.000000|6.553500] "V"  Logger
 SG_ VDynoCoolantFlowRaw : 55|16@0+ (0.000100,0.000000) [0.000000|6.553500] "V"  Logger

BO_ 129 StatusAPPSSensor: 1 APPS
 SG_ rAPPs1 : 7|8@0- (1.000000,0.000000) [-128.000000|127.000000] ""  Screen

BO_ 64 IMDData: 5 IMD_Monitor
 SG_ BIMDOff : 7|1@0+ (1.000000,0.000000) [0.000000|1.000000] ""  Screen
 SG_ BIMDUnderVoltage : 6|1@0+ (1.000000,0.000000) [0.000000|1.000000] ""  Screen
 SG_ BIMDStarting : 5|1@0+ (1.000000,0.000000) [0.000000|1.000000] ""  Screen
 SG_ BIMDSSTGood : 4|1@0+ (1.000000,0.000000) [0.000000|1.000000] ""  Screen
 SG_ BIMDDeviceError : 3|1@0+ (1.000000,0.000000) [0.000000|1.000000] ""  Screen
 SG_ BIMDGroundConnectionFault : 2|1@0+ (1.000000,0.000000) [0.000000|1.000000] ""  Screen
 SG_ BIMDInvalidState : 1|1@0+ (1.000000,0.000000) [0.000000|1.000000] ""  Screen
 SG_ RIsolation : 15|16@0+ (200.000000,0.000000) [0.000000|13107000.000000] "ohm"  Screen
 SG_ fIMDPWM : 31|8@0+ (1.000000,0.000000) [0.000000|255.000000] "Hz"  Screen
 SG_ rIMDPWM : 39|8@0+ (1.000000,0.000000) [0.000000|255.000000] "%"  Screen

BO_ 54 CellVoltages: 8 BMS
 SG_ CellID M : 7|8@0+ (1.000000,0.000000) [0.000000|255.000000] ""  Logger
 SG_ VCell001 m0 : 15|16@0+ (0.000100,0.000000) [0.000000|6.553500] "V"  Logger
 SG_ VCell002 m1 : 15|16@0+ (0.000100,0.000000) [0.000000|6.553500] "V"  Logger
 SG_ VCell003 m2 : 15|16@0+ (0.000100,0.000000) [0.000000|6.553500] "V"  Logger
 SG_ VCell004 m3 : 15|16@0+ (0.000100,0.000000) [0.000000|6.553500] "V"  Logger
 SG_ VCell005 m4 : 15|16@0+ (0.000100,0.000000) [0.000000|6.553500] "V"  Logger
 SG_ VCell006 m5 : 15|16@0+ (0.000100,0.000000) [0.000000|6.553500] "V"  Logger
 SG_ VCell007 m6 : 15|16@0+ (0.000100,0.000000) [0.000000|6.553500] "V"  Logger
 SG_ VCell008 m7 : 15|16@0+ (0.000100,0.000000) [0.000000|6.553500] "V"  Logger
 SG_ VCell009 m8 : 15|16@0+ (0.000100,0.000000) [0.000000|6.553500] "V"  Logger
 SG_ VCell010 m9 : 15|16@0+ (0.000100,0.000000) [0.000000|6.553500] "V"  Logger
 SG_ VCell011 m10 : 15|16@0+ (0.000100,0.000000) [0.000000|6.553500] "V"  Logger
 SG_ VCell012 m11 : 15|16@0+ (0.000100,0.000000) [0.000000|6.553500] "V"  Logger
 SG_ VCell013 m12 : 15|16@0+ (0.000100,0.000000) [0.000000|6.553500] "V"  Logger
 SG_ VCell014 m13 : 15|16@0+ (0.000100,0.000000) [0.000000|6.553500] "V"  Logger
 SG_ VCell015 m14 : 15|16@0+ (0.000100,0.000000) [0.000000|6.553500] "V"  Logger
 SG_ VCell016 m15 : 15|16@0+ (0.000100,0.000000) [0.000000|6.553500] "V"  Logger
 SG_ VCell017 m16 : 15|16@0+ (0.000100,0.000000) [0.000000|6.553500] "V"  Logger
 SG_ VCell018 m17 : 15|16@0+ (0.000100,0.000000) [0.000000|6.553500] "V"  Logger
 SG_ VCell019 m18 : 15|16@0+ (0.000100,0.000000) [0.000000|6.553500] "V"  Logger
 SG_ VCell020 m19 : 15|16@0+ (0.000100,0.000000) [0.000000|6.553500] "V"  Logger
 SG_ VCell021 m20 : 15|16@0+ (0.000100,0.000000) [0.000000|6.553500] "V"  Logger
 SG_ VCell022 m21 : 15|16@0+ (0.000100,0.000000) [0.000000|6.553500] "V"  Logger
 SG_ VCell023 m22 : 15|16@0+ (0.000100,0.000000) [0.000000|6.553500] "V"  Logger
 SG_ VCell024 m23 : 15|16@0+ (0.000100,0.000000) [0.000000|6.553500] "V"  Logger
 SG_ VCell025 m24 : 15|16@0+ (0.000100,0.000000) [0.000000|6.553500] "V"  Logger
 SG_ VCell026 m25 : 15|16@0+ (0.000100,0.000000) [0.000000|6.553500] "V"  Logger
 SG_ VCell027 m26 : 15|16@0+ (0.000100,0.000000) [0.000000|6.553500] "V"  Logger
 SG_ VCell028 m27 : 15|16@0+ (0.000100,0.000000) [0.000000|6.553500] "V"  Logger
 SG_ VCell029 m28 : 15|16@0+ (0.000100,0.000000) [0.000000|6.553500] "V"  Logger
 SG_ VCell030 m29 : 15|16@0+ (0.000100,0.000000) [0.000000|6.553500] "V"  Logger
 SG_ VCell031 m30 : 15|16@0+ (0.000100,0.000000) [0.000000|6.553500] "V"  Logger
 SG_ VCell032 m31 : 15|16@0+ (0.000100,0.000000) [0.000000|6.553500] "V"  Logger
 SG_ VCell033 m32 : 15|16@0+ (0.000100,0.000000) [0.000000|6.553500] "V"  Logger
 SG_ VCell034 m33 : 15|16@0+ (0.000100,0.000000) [0.000000|6.553500] "V"  Logger
 SG_ VCell035 m34 : 15|16@0+ (0.000100,0.000000) [0.000000|6.553500] "V"  Logger
 SG_ VCell036 m35 : 15|16@0+ (0.000100,0.000000) [0.000000|6.553500] "V"  Logger
 SG_ VCell037 m36 : 15|16@0+ (0.000100,0.000000) [0.000000|6.553500] "V"  Logger
 SG_ VCell038 m37 : 15|16@0+ (0.000100,0.000000) [0.000000|6.553500] "V"  Logger
 SG_ VCell039 m38 : 15|16@0+ (0.000100,0.000000) [0.000000|6.553500] "V"  Logger
 SG_ VCell040 m39 : 15|16@0+ (0.000100,0.000000) [0.000000|6.553500] "V"  Logger
 SG_ VCell041 m40 : 15|16@0+ (0.000100,0.000000) [0.000000|6.553500] "V"  Logger
 SG_ VCell042 m41 : 15|16@0+ (0.000100,0.000000) [0.000000|6.553500] "V"  Logger
 SG_ VCell043 m42 : 15|16@0+ (0.000100,0.000000) [0.000000|6.553500] "V"  Logger
 SG_ VCell044 m43 : 15|16@0+ (0.000100,0.000000) [0.000000|6.553500] "V"  Logger
 SG_ VCell045 m44 : 15|16@0+ (0.000100,0.000000) [0.000000|6.553500] "V"  Logger
 SG_ VCell046 m45 : 15|16@0+ (0.000100,0.000000) [0.000000|6.553500] "V"  Logger
 SG_ VCell047 m46 : 15|16@0+ (0.000100,0.000000) [0.000000|6.553500] "V"  Logger
 SG_ VCell048 m47 : 15|16@0+ (0.000100,0.000000) [0.000000|6.553500] "V"  Logger
 SG_ VCell049 m48 : 15|16@0+ (0.000100,0.000000) [0.000000|6.553500] "V"  Logger
 SG_ VCell050 m49 : 15|16@0+ (0.000100,0.000000) [0.000000|6.553500] "V"  Logger
 SG_ VCell051 m50 : 15|16@0+ (0.000100,0.000000) [0.000000|6.553500] "V"  Logger
 SG_ VCell052 m51 : 15|16@0+ (0.000100,0.000000) [0.000000|6.553500] "V"  Logger
 SG_ VCell053 m52 : 15|16@0+ (0.000100,0.000000) [0.000000|6.553500] "V"  Logger
 SG_ VCell054 m53 : 15|16@0+ (0.000100,0.000000) [0.000000|6.553500] "V"  Logger
 SG_ VCell055 m54 : 15|16@0+ (0.000100,0.000000) [0.000000|6.553500] "V"  Logger
 SG_ VCell056 m55 : 15|16@0+ (0.000100,0.000000) [0.000000|6.553500] "V"  Logger
 SG_ VCell057 m56 : 15|16@0+ (0.000100,0.000000) [0.000000|6.553500] "V"  Logger
 SG_ VCell058 m57 : 15|16@0+ (0.000100,0.000000) [0.000000|6.553500] "V"  Logger
 SG_ VCell059 m58 : 15|16@0+ (0.000100,0.000000) [0.000000|6.553500] "V"  Logger
 SG_ VCell060 m59 : 15|16@0+ (0.000100,0.000000) [0.000000|6.553500] "V"  Logger
 SG_ VCell061 m60 : 15|16@0+ (0.000100,0.000000) [0.000000|6.553500] "V"  Logger
 SG_ VCell062 m61 : 15|16@0+ (0.000100,0.000000) [0.000000|6.553500] "V"  Logger
 SG_ VCell063 m62 : 15|16@0+ (0.000100,0.000000) [0.000000|6.553500] "V"  Logger
 SG_ VCell064 m63 : 15|16@0+ (0.000100,0.000000) [0.000000|6.553500] "V"  Logger
 SG_ VCell065 m64 : 15|16@0+ (0.000100,0.000000) [0.000000|6.553500] "V"  Logger
 SG_ VCell066 m65 : 15|16@0+ (0.000100,0.000000) [0.000000|6.553500] "V"  Logger
 SG_ VCell067 m66 : 15|16@0+ (0.000100,0.000000) [0.000000|6.553500] "V"  Logger
 SG_ VCell068 m67 : 15|16@0+ (0.000100,0.000000) [0.000000|6.553500] "V"  Logger
 SG_ VCell069 m68 : 15|16@0+ (0.000100,0.000000) [0.000000|6.553500] "V"  Logger
 SG_ VCell070 m69 : 15|16@0+ (0.000100,0.000000) [0.000000|6.553500] "V"  Logger
 SG_ VCell071 m70 : 15|16@0+ (0.000100,0.000000) [0.000000|6.553500] "V"  Logger
 SG_ VCell072 m71 : 15|16@0+ (0.000100,0.000000) [0.000000|6.553500] "V"  Logger
 SG_ VCell073 m72 : 15|16@0+ (0.000100,0.000000) [0.000000|6.553500] "V"  Logger
 SG_ VCell074 m73 : 15|16@0+ (0.000100,0.000000) [0.000000|6.553500] "V"  Logger
 SG_ VCell075 m74 : 15|16@0+ (0.000100,0.000000) [0.000000|6.553500] "V"  Logger
 SG_ VCell076 m75 : 15|16@0+ (0.000100,0.000000) [0.000000|6.553500] "V"  Logger
 SG_ VCell077 m76 : 15|16@0+ (0.000100,0.000000) [0.000000|6.553500] "V"  Logger
 SG_ VCell078 m77 : 15|16@0+ (0.000100,0.000000) [0.000000|6.553500] "V"  Logger
 SG_ VCell079 m78 : 15|16@0+ (0.000100,0.000000) [0.000000|6.553500] "V"  Logger
 SG_ VCell080 m79 : 15|16@0+ (0.000100,0.000000) [0.000000|6.553500] "V"  Logger
 SG_ VCell081 m80 : 15|16@0+ (0.000100,0.000000) [0.000000|6.553500] "V"  Logger
 SG_ VCell082 m81 : 15|16@0+ (0.000100,0.000000) [0.000000|6.553500] "V"  Logger
 SG_ VCell083 m82 : 15|16@0+ (0.000100,0.000000) [0.000000|6.553500] "V"  Logger
 SG_ VCell084 m83 : 15|16@0+ (0.000100,0.000000) [0.000000|6.553500] "V"  Logger
 SG_ VCell085 m84 : 15|16@0+ (0.000100,0.000000) [0.000000|6.553500] "V"  Logger
 SG_ VCell086 m85 : 15|16@0+ (0.000100,0.000000) [0.000000|6.553500] "V"  Logger
 SG_ VCell087 m86 : 15|16@0+ (0.000100,0.000000) [0.000000|6.553500] "V"  Logger
 SG_ VCell088 m87 : 15|16@0+ (0.000100,0.000000) [0.000000|6.553500] "V"  Logger
 SG_ VCell089 m88 : 15|16@0+ (0.000100,0.000000) [0.000000|6.553500] "V"  Logger
 SG_ VCell090 m89 : 15|16@0+ (0.000100,0.000000) [0.000000|6.553500] "V"  Logger
 SG_ VCell091 m90 : 15|16@0+ (0.000100,0.000000) [0.000000|6.553500] "V"  Logger
 SG_ VCell092 m91 : 15|16@0+ (0.000100,0.000000) [0.000000|6.553500] "V"  Logger
 SG_ VCell093 m92 : 15|16@0+ (0.000100,0.000000) [0.000000|6.553500] "V"  Logger
 SG_ VCell094 m93 : 15|16@0+ (0.000100,0.000000) [0.000000|6.553500] "V"  Logger
 SG_ VCell095 m94 : 15|16@0+ (0.000100,0.000000) [0.000000|6.553500] "V"  Logger
 SG_ VCell096 m95 : 15|16@0+ (0.000100,0.000000) [0.000000|6.553500] "V"  Logger
 SG_ VCell097 m96 : 15|16@0+ (0.000100,0.000000) [0.000000|6.553500] "V"  Logger
 SG_ VCell098 m97 : 15|16@0+ (0.000100,0.000000) [0.000000|6.553500] "V"  Logger
 SG_ VCell099 m98 : 15|16@0+ (0.000100,0.000000) [0.000000|6.553500] "V"  Logger
 SG_ VCell100 m99 : 15|16@0+ (0.000100,0.000000) [0.000000|6.553500] "V"  Logger
 SG_ VCell101 m100 : 15|16@0+ (0.000100,0.000000) [0.000000|6.553500] "V"  Logger
 SG_ VCell102 m101 : 15|16@0+ (0.000100,0.000000) [0.000000|6.553500] "V"  Logger
 SG_ VCell103 m102 : 15|16@0+ (0.000100,0.000000) [0.000000|6.553500] "V"  Logger
 SG_ VCell104 m103 : 15|16@0+ (0.000100,0.000000) [0.000000|6.553500] "V"  Logger
 SG_ VCell105 m104 : 15|16@0+ (0.000100,0.000000) [0.000000|6.553500] "V"  Logger
 SG_ VCell106 m105 : 15|16@0+ (0.000100,0.000000) [0.000000|6.553500] "V"  Logger
 SG_ VCell107 m106 : 15|16@0+ (0.000100,0.000000) [0.000000|6.553500] "V"  Logger
 SG_ VCell108 m107 : 15|16@0+ (0.000100,0.000000) [0.000000|6.553500] "V"  Logger
 SG_ VCell109 m108 : 15|16@0+ (0.000100,0.000000) [0.000000|6.553500] "V"  Logger
 SG_ VCell110 m109 : 15|16@0+ (0.000100,0.000000) [0.000000|6.553500] "V"  Logger
 SG_ VCell111 m110 : 15|16@0+ (0.000100,0.000000) [0.000000|6.553500] "V"  Logger
 SG_ VCell112 m111 : 15|16@0+ (0.000100,0.000000) [0.000000|6.553500] "V"  Logger
 SG_ RCell001 m0 : 30|15@0+ (0.010000,0.000000) [0.000000|327.670000] "mOhm"  Logger
 SG_ RCell002 m1 : 30|15@0+ (0.010000,0.000000) [0.000000|327.670000] "mOhm"  Logger
 SG_ RCell003 m2 : 30|15@0+ (0.010000,0.000000) [0.000000|327.670000] "mOhm"  Logger
 SG_ RCell004 m3 : 30|15@0+ (0.010000,0.000000) [0.000000|327.670000] "mOhm"  Logger
 SG_ RCell005 m4 : 30|15@0+ (0.010000,0.000000) [0.000000|327.670000] "mOhm"  Logger
 SG_ RCell006 m5 : 30|15@0+ (0.010000,0.000000) [0.000000|327.670000] "mOhm"  Logger
 SG_ RCell007 m6 : 30|15@0+ (0.010000,0.000000) [0.000000|327.670000] "mOhm"  Logger
 SG_ RCell008 m7 : 30|15@0+ (0.010000,0.000000) [0.000000|327.670000] "mOhm"  Logger
 SG_ RCell009 m8 : 30|15@0+ (0.010000,0.000000) [0.000000|327.670000] "mOhm"  Logger
 SG_ RCell010 m9 : 30|15@0+ (0.010000,0.000000) [0.000000|327.670000] "mOhm"  Logger
 SG_ RCell011 m10 : 30|15@0+ (0.010000,0.000000) [0.000000|327.670000] "mOhm"  Logger
 SG_ RCell012 m11 : 30|15@0+ (0.010000,0.000000) [0.000000|327.670000] "mOhm"  Logger
 SG_ RCell013 m12 : 30|15@0+ (0.010000,0.000000) [0.000000|327.670000] "mOhm"  Logger
 SG_ RCell014 m13 : 30|15@0+ (0.010000,0.000000) [0.000000|327.670000] "mOhm"  Logger
 SG_ RCell015 m14 : 30|15@0+ (0.010000,0.000000) [0.000000|327.670000] "mOhm"  Logger
 SG_ RCell016 m15 : 30|15@0+ (0.010000,0.000000) [0.000000|327.670000] "mOhm"  Logger
 SG_ RCell017 m16 : 30|15@0+ (0.010000,0.000000) [0.000000|327.670000] "mOhm"  Logger
 SG_ RCell018 m17 : 30|15@0+ (0.010000,0.000000) [0.000000|327.670000] "mOhm"  Logger
 SG_ RCell019 m18 : 30|15@0+ (0.010000,0.000000) [0.000000|327.670000] "mOhm"  Logger
 SG_ RCell020 m19 : 30|15@0+ (0.010000,0.000000) [0.000000|327.670000] "mOhm"  Logger
 SG_ RCell021 m20 : 30|15@0+ (0.010000,0.000000) [0.000000|327.670000] "mOhm"  Logger
 SG_ RCell022 m21 : 30|15@0+ (0.010000,0.000000) [0.000000|327.670000] "mOhm"  Logger
 SG_ RCell023 m22 : 30|15@0+ (0.010000,0.000000) [0.000000|327.670000] "mOhm"  Logger
 SG_ RCell024 m23 : 30|15@0+ (0.010000,0.000000) [0.000000|327.670000] "mOhm"  Logger
 SG_ RCell025 m24 : 30|15@0+ (0.010000,0.000000) [0.000000|327.670000] "mOhm"  Logger
 SG_ RCell026 m25 : 30|15@0+ (0.010000,0.000000) [0.000000|327.670000] "mOhm"  Logger
 SG_ RCell027 m26 : 30|15@0+ (0.010000,0.000000) [0.000000|327.670000] "mOhm"  Logger
 SG_ RCell028 m27 : 30|15@0+ (0.010000,0.000000) [0.000000|327.670000] "mOhm"  Logger
 SG_ RCell029 m28 : 30|15@0+ (0.010000,0.000000) [0.000000|327.670000] "mOhm"  Logger
 SG_ RCell030 m29 : 30|15@0+ (0.010000,0.000000) [0.000000|327.670000] "mOhm"  Logger
 SG_ RCell031 m30 : 30|15@0+ (0.010000,0.000000) [0.000000|327.670000] "mOhm"  Logger
 SG_ RCell032 m31 : 30|15@0+ (0.010000,0.000000) [0.000000|327.670000] "mOhm"  Logger
 SG_ RCell033 m32 : 30|15@0+ (0.010000,0.000000) [0.000000|327.670000] "mOhm"  Logger
 SG_ RCell034 m33 : 30|15@0+ (0.010000,0.000000) [0.000000|327.670000] "mOhm"  Logger
 SG_ RCell035 m34 : 30|15@0+ (0.010000,0.000000) [0.000000|327.670000] "mOhm"  Logger
 SG_ RCell036 m35 : 30|15@0+ (0.010000,0.000000) [0.000000|327.670000] "mOhm"  Logger
 SG_ RCell037 m36 : 30|15@0+ (0.010000,0.000000) [0.000000|327.670000] "mOhm"  Logger
 SG_ RCell038 m37 : 30|15@0+ (0.010000,0.000000) [0.000000|327.670000] "mOhm"  Logger
 SG_ RCell039 m38 : 30|15@0+ (0.010000,0.000000) [0.000000|327.670000] "mOhm"  Logger
 SG_ RCell040 m39 : 30|15@0+ (0.010000,0.000000) [0.000000|327.670000] "mOhm"  Logger
 SG_ RCell041 m40 : 30|15@0+ (0.010000,0.000000) [0.000000|327.670000] "mOhm"  Logger
 SG_ RCell042 m41 : 30|15@0+ (0.010000,0.000000) [0.000000|327.670000] "mOhm"  Logger
 SG_ RCell043 m42 : 30|15@0+ (0.010000,0.000000) [0.000000|327.670000] "mOhm"  Logger
 SG_ RCell044 m43 : 30|15@0+ (0.010000,0.000000) [0.000000|327.670000] "mOhm"  Logger
 SG_ RCell045 m44 : 30|15@0+ (0.010000,0.000000) [0.000000|327.670000] "mOhm"  Logger
 SG_ RCell046 m45 : 30|15@0+ (0.010000,0.000000) [0.000000|327.670000] "mOhm"  Logger
 SG_ RCell047 m46 : 30|15@0+ (0.010000,0.000000) [0.000000|327.670000] "mOhm"  Logger
 SG_ RCell048 m47 : 30|15@0+ (0.010000,0.000000) [0.000000|327.670000] "mOhm"  Logger
 SG_ RCell049 m48 : 30|15@0+ (0.010000,0.000000) [0.000000|327.670000] "mOhm"  Logger
 SG_ RCell050 m49 : 30|15@0+ (0.010000,0.000000) [0.000000|327.670000] "mOhm"  Logger
 SG_ RCell051 m50 : 30|15@0+ (0.010000,0.000000) [0.000000|327.670000] "mOhm"  Logger
 SG_ RCell052 m51 : 30|15@0+ (0.010000,0.000000) [0.000000|327.670000] "mOhm"  Logger
 SG_ RCell053 m52 : 30|15@0+ (0.010000,0.000000) [0.000000|327.670000] "mOhm"  Logger
 SG_ RCell054 m53 : 30|15@0+ (0.010000,0.000000) [0.000000|327.670000] "mOhm"  Logger
 SG_ RCell055 m54 : 30|15@0+ (0.010000,0.000000) [0.000000|327.670000] "mOhm"  Logger
 SG_ RCell056 m55 : 30|15@0+ (0.010000,0.000000) [0.000000|327.670000] "mOhm"  Logger
 SG_ RCell057 m56 : 30|15@0+ (0.010000,0.000000) [0.000000|327.670000] "mOhm"  Logger
 SG_ RCell058 m57 : 30|15@0+ (0.010000,0.000000) [0.000000|327.670000] "mOhm"  Logger
 SG_ RCell059 m58 : 30|15@0+ (0.010000,0.000000) [0.000000|327.670000] "mOhm"  Logger
 SG_ RCell060 m59 : 30|15@0+ (0.010000,0.000000) [0.000000|327.670000] "mOhm"  Logger
 SG_ RCell061 m60 : 30|15@0+ (0.010000,0.000000) [0.000000|327.670000] "mOhm"  Logger
 SG_ RCell062 m61 : 30|15@0+ (0.010000,0.000000) [0.000000|327.670000] "mOhm"  Logger
 SG_ RCell063 m62 : 30|15@0+ (0.010000,0.000000) [0.000000|327.670000] "mOhm"  Logger
 SG_ RCell064 m63 : 30|15@0+ (0.010000,0.000000) [0.000000|327.670000] "mOhm"  Logger
 SG_ RCell065 m64 : 30|15@0+ (0.010000,0.000000) [0.000000|327.670000] "mOhm"  Logger
 SG_ RCell066 m65 : 30|15@0+ (0.010000,0.000000) [0.000000|327.670000] "mOhm"  Logger
 SG_ RCell067 m66 : 30|15@0+ (0.010000,0.000000) [0.000000|327.670000] "mOhm"  Logger
 SG_ RCell068 m67 : 30|15@0+ (0.010000,0.000000) [0.000000|327.670000] "mOhm"  Logger
 SG_ RCell069 m68 : 30|15@0+ (0.010000,0.000000) [0.000000|327.670000] "mOhm"  Logger
 SG_ RCell070 m69 : 30|15@0+ (0.010000,0.000000) [0.000000|327.670000] "mOhm"  Logger
 SG_ RCell071 m70 : 30|15@0+ (0.010000,0.000000) [0.000000|327.670000] "mOhm"  Logger
 SG_ RCell072 m71 : 30|15@0+ (0.010000,0.000000) [0.000000|327.670000] "mOhm"  Logger
 SG_ RCell073 m72 : 30|15@0+ (0.010000,0.000000) [0.000000|327.670000] "mOhm"  Logger
 SG_ RCell074 m73 : 30|15@0+ (0.010000,0.000000) [0.000000|327.670000] "mOhm"  Logger
 SG_ RCell075 m74 : 30|15@0+ (0.010000,0.000000) [0.000000|327.670000] "mOhm"  Logger
 SG_ RCell076 m75 : 30|15@0+ (0.010000,0.000000) [0.000000|327.670000] "mOhm"  Logger
 SG_ RCell077 m76 : 30|15@0+ (0.010000,0.000000) [0.000000|327.670000] "mOhm"  Logger
 SG_ RCell078 m77 : 30|15@0+ (0.010000,0.000000) [0.000000|327.670000] "mOhm"  Logger
 SG_ RCell079 m78 : 30|15@0+ (0.010000,0.000000) [0.000000|327.670000] "mOhm"  Logger
 SG_ RCell080 m79 : 30|15@0+ (0.010000,0.000000) [0.000000|327.670000] "mOhm"  Logger
 SG_ RCell081 m80 : 30|15@0+ (0.010000,0.000000) [0.000000|327.670000] "mOhm"  Logger
 SG_ RCell082 m81 : 30|15@0+ (0.010000,0.000000) [0.000000|327.670000] "mOhm"  Logger
 SG_ RCell083 m82 : 30|15@0+ (0.010000,0.000000) [0.000000|327.670000] "mOhm"  Logger
 SG_ RCell084 m83 : 30|15@0+ (0.010000,0.000000) [0.000000|327.670000] "mOhm"  Logger
 SG_ RCell085 m84 : 30|15@0+ (0.010000,0.000000) [0.000000|327.670000] "mOhm"  Logger
 SG_ RCell086 m85 : 30|15@0+ (0.010000,0.000000) [0.000000|327.670000] "mOhm"  Logger
 SG_ RCell087 m86 : 30|15@0+ (0.010000,0.000000) [0.000000|327.670000] "mOhm"  Logger
 SG_ RCell088 m87 : 30|15@0+ (0.010000,0.000000) [0.000000|327.670000] "mOhm"  Logger
 SG_ RCell089 m88 : 30|15@0+ (0.010000,0.000000) [0.000000|327.670000] "mOhm"  Logger
 SG_ RCell090 m89 : 30|15@0+ (0.010000,0.000000) [0.000000|327.670000] "mOhm"  Logger
 SG_ RCell091 m90 : 30|15@0+ (0.010000,0.000000) [0.000000|327.670000] "mOhm"  Logger
 SG_ RCell092 m91 : 30|15@0+ (0.010000,0.000000) [0.000000|327.670000] "mOhm"  Logger
 SG_ RCell093 m92 : 30|15@0+ (0.010000,0.000000) [0.000000|327.670000] "mOhm"  Logger
 SG_ RCell094 m93 : 30|15@0+ (0.010000,0.000000) [0.000000|327.670000] "mOhm"  Logger
 SG_ RCell095 m94 : 30|15@0+ (0.010000,0.000000) [0.000000|327.670000] "mOhm"  Logger
 SG_ RCell096 m95 : 30|15@0+ (0.010000,0.000000) [0.000000|327.670000] "mOhm"  Logger
 SG_ RCell097 m96 : 30|15@0+ (0.010000,0.000000) [0.000000|327.670000] "mOhm"  Logger
 SG_ RCell098 m97 : 30|15@0+ (0.010000,0.000000) [0.000000|327.670000] "mOhm"  Logger
 SG_ RCell099 m98 : 30|15@0+ (0.010000,0.000000) [0.000000|327.670000] "mOhm"  Logger
 SG_ RCell100 m99 : 30|15@0+ (0.010000,0.000000) [0.000000|327.670000] "mOhm"  Logger
 SG_ RCell101 m100 : 30|15@0+ (0.010000,0.000000) [0.000000|327.670000] "mOhm"  Logger
 SG_ RCell102 m101 : 30|15@0+ (0.010000,0.000000) [0.000000|327.670000] "mOhm"  Logger
 SG_ RCell103 m102 : 30|15@0+ (0.010000,0.000000) [0.000000|327.670000] "mOhm"  Logger
 SG_ RCell104 m103 : 30|15@0+ (0.010000,0.000000) [0.000000|327.670000] "mOhm"  Logger
 SG_ RCell105 m104 : 30|15@0+ (0.010000,0.000000) [0.000000|327.670000] "mOhm"  Logger
 SG_ RCell106 m105 : 30|15@0+ (0.010000,0.000000) [0.000000|327.670000] "mOhm"  Logger
 SG_ RCell107 m106 : 30|15@0+ (0.010000,0.000000) [0.000000|327.670000] "mOhm"  Logger
 SG_ RCell108 m107 : 30|15@0+ (0.010000,0.000000) [0.000000|327.670000] "mOhm"  Logger
 SG_ RCell109 m108 : 30|15@0+ (0.010000,0.000000) [0.000000|327.670000] "mOhm"  Logger
 SG_ RCell110 m109 : 30|15@0+ (0.010000,0.000000) [0.000000|327.670000] "mOhm"  Logger
 SG_ RCell111 m110 : 30|15@0+ (0.010000,0.000000) [0.000000|327.670000] "mOhm"  Logger
 SG_ RCell112 m111 : 30|15@0+ (0.010000,0.000000) [0.000000|327.670000] "mOhm"  Logger
 SG_ BBalancingCell001 m0 : 31|1@1+ (1.000000,0.000000) [0.000000|1.000000] ""  Logger
 SG_ BBalancingCell002 m1 : 31|1@1+ (1.000000,0.000000) [0.000000|1.000000] ""  Logger
 SG_ BBalancingCell003 m2 : 31|1@1+ (1.000000,0.000000) [0.000000|1.000000] ""  Logger
 SG_ BBalancingCell004 m3 : 31|1@1+ (1.000000,0.000000) [0.000000|1.000000] ""  Logger
 SG_ BBalancingCell005 m4 : 31|1@1+ (1.000000,0.000000) [0.000000|1.000000] ""  Logger
 SG_ BBalancingCell006 m5 : 31|1@1+ (1.000000,0.000000) [0.000000|1.000000] ""  Logger
 SG_ BBalancingCell007 m6 : 31|1@1+ (1.000000,0.000000) [0.000000|1.000000] ""  Logger
 SG_ BBalancingCell008 m7 : 31|1@1+ (1.000000,0.000000) [0.000000|1.000000] ""  Logger
 SG_ BBalancingCell009 m8 : 31|1@1+ (1.000000,0.000000) [0.000000|1.000000] ""  Logger
 SG_ BBalancingCell010 m9 : 31|1@1+ (1.000000,0.000000) [0.000000|1.000000] ""  Logger
 SG_ BBalancingCell011 m10 : 31|1@1+ (1.000000,0.000000) [0.000000|1.000000] ""  Logger
 SG_ BBalancingCell012 m11 : 31|1@1+ (1.000000,0.000000) [0.000000|1.000000] ""  Logger
 SG_ BBalancingCell013 m12 : 31|1@1+ (1.000000,0.000000) [0.000000|1.000000] ""  Logger
 SG_ BBalancingCell014 m13 : 31|1@1+ (1.000000,0.000000) [0.000000|1.000000] ""  Logger
 SG_ BBalancingCell015 m14 : 31|1@1+ (1.000000,0.000000) [0.000000|1.000000] ""  Logger
 SG_ BBalancingCell016 m15 : 31|1@1+ (1.000000,0.000000) [0.000000|1.000000] ""  Logger
 SG_ BBalancingCell017 m16 : 31|1@1+ (1.000000,0.000000) [0.000000|1.000000] ""  Logger
 SG_ BBalancingCell018 m17 : 31|1@1+ (1.000000,0.000000) [0.000000|1.000000] ""  Logger
 SG_ BBalancingCell019 m18 : 31|1@1+ (1.000000,0.000000) [0.000000|1.000000] ""  Logger
 SG_ BBalancingCell020 m19 : 31|1@1+ (1.000000,0.000000) [0.000000|1.000000] ""  Logger
 SG_ BBalancingCell021 m20 : 31|1@1+ (1.000000,0.000000) [0.000000|1.000000] ""  Logger
 SG_ BBalancingCell022 m21 : 31|1@1+ (1.000000,0.000000) [0.000000|1.000000] ""  Logger
 SG_ BBalancingCell023 m22 : 31|1@1+ (1.000000,0.000000) [0.000000|1.000000] ""  Logger
 SG_ BBalancingCell024 m23 : 31|1@1+ (1.000000,0.000000) [0.000000|1.000000] ""  Logger
 SG_ BBalancingCell025 m24 : 31|1@1+ (1.000000,0.000000) [0.000000|1.000000] ""  Logger
 SG_ BBalancingCell026 m25 : 31|1@1+ (1.000000,0.000000) [0.000000|1.000000] ""  Logger
 SG_ BBalancingCell027 m26 : 31|1@1+ (1.000000,0.000000) [0.000000|1.000000] ""  Logger
 SG_ BBalancingCell028 m27 : 31|1@1+ (1.000000,0.000000) [0.000000|1.000000] ""  Logger
 SG_ BBalancingCell029 m28 : 31|1@1+ (1.000000,0.000000) [0.000000|1.000000] ""  Logger
 SG_ BBalancingCell030 m29 : 31|1@1+ (1.000000,0.000000) [0.000000|1.000000] ""  Logger
 SG_ BBalancingCell031 m30 : 31|1@1+ (1.000000,0.000000) [0.000000|1.000000] ""  Logger
 SG_ BBalancingCell032 m31 : 31|1@1+ (1.000000,0.000000) [0.000000|1.000000] ""  Logger
 SG_ BBalancingCell033 m32 : 31|1@1+ (1.000000,0.000000) [0.000000|1.000000] ""  Logger
 SG_ BBalancingCell034 m33 : 31|1@1+ (1.000000,0.000000) [0.000000|1.000000] ""  Logger
 SG_ BBalancingCell035 m34 : 31|1@1+ (1.000000,0.000000) [0.000000|1.000000] ""  Logger
 SG_ BBalancingCell036 m35 : 31|1@1+ (1.000000,0.000000) [0.000000|1.000000] ""  Logger
 SG_ BBalancingCell037 m36 : 31|1@1+ (1.000000,0.000000) [0.000000|1.000000] ""  Logger
 SG_ BBalancingCell038 m37 : 31|1@1+ (1.000000,0.000000) [0.000000|1.000000] ""  Logger
 SG_ BBalancingCell039 m38 : 31|1@1+ (1.000000,0.000000) [0.000000|1.000000] ""  Logger
 SG_ BBalancingCell040 m39 : 31|1@1+ (1.000000,0.000000) [0.000000|1.000000] ""  Logger
 SG_ BBalancingCell041 m40 : 31|1@1+ (1.000000,0.000000) [0.000000|1.000000] ""  Logger
 SG_ BBalancingCell042 m41 : 31|1@1+ (1.000000,0.000000) [0.000000|1.000000] ""  Logger
 SG_ BBalancingCell043 m42 : 31|1@1+ (1.000000,0.000000) [0.000000|1.000000] ""  Logger
 SG_ BBalancingCell044 m43 : 31|1@1+ (1.000000,0.000000) [0.000000|1.000000] ""  Logger
 SG_ BBalancingCell045 m44 : 31|1@1+ (1.000000,0.000000) [0.000000|1.000000] ""  Logger
 SG_ BBalancingCell046 m45 : 31|1@1+ (1.000000,0.000000) [0.000000|1.000000] ""  Logger
 SG_ BBalancingCell047 m46 : 31|1@1+ (1.000000,0.000000) [0.000000|1.000000] ""  Logger
 SG_ BBalancingCell048 m47 : 31|1@1+ (1.000000,0.000000) [0.000000|1.000000] ""  Logger
 SG_ BBalancingCell049 m48 : 31|1@1+ (1.000000,0.000000) [0.000000|1.000000] ""  Logger
 SG_ BBalancingCell050 m49 : 31|1@1+ (1.000000,0.000000) [0.000000|1.000000] ""  Logger
 SG_ BBalancingCell051 m50 : 31|1@1+ (1.000000,0.000000) [0.000000|1.000000] ""  Logger
 SG_ BBalancingCell052 m51 : 31|1@1+ (1.000000,0.000000) [0.000000|1.000000] ""  Logger
 SG_ BBalancingCell053 m52 : 31|1@1+ (1.000000,0.000000) [0.000000|1.000000] ""  Logger
 SG_ BBalancingCell054 m53 : 31|1@1+ (1.000000,0.000000) [0.000000|1.000000] ""  Logger
 SG_ BBalancingCell055 m54 : 31|1@1+ (1.000000,0.000000) [0.000000|1.000000] ""  Logger
 SG_ BBalancingCell056 m55 : 31|1@1+ (1.000000,0.000000) [0.000000|1.000000] ""  Logger
 SG_ BBalancingCell057 m56 : 31|1@1+ (1.000000,0.000000) [0.000000|1.000000] ""  Logger
 SG_ BBalancingCell058 m57 : 31|1@1+ (1.000000,0.000000) [0.000000|1.000000] ""  Logger
 SG_ BBalancingCell059 m58 : 31|1@1+ (1.000000,0.000000) [0.000000|1.000000] ""  Logger
 SG_ BBalancingCell060 m59 : 31|1@1+ (1.000000,0.000000) [0.000000|1.000000] ""  Logger
 SG_ BBalancingCell061 m60 : 31|1@1+ (1.000000,0.000000) [0.000000|1.000000] ""  Logger
 SG_ BBalancingCell062 m61 : 31|1@1+ (1.000000,0.000000) [0.000000|1.000000] ""  Logger
 SG_ BBalancingCell063 m62 : 31|1@1+ (1.000000,0.000000) [0.000000|1.000000] ""  Logger
 SG_ BBalancingCell064 m63 : 31|1@1+ (1.000000,0.000000) [0.000000|1.000000] ""  Logger
 SG_ BBalancingCell065 m64 : 31|1@1+ (1.000000,0.000000) [0.000000|1.000000] ""  Logger
 SG_ BBalancingCell066 m65 : 31|1@1+ (1.000000,0.000000) [0.000000|1.000000] ""  Logger
 SG_ BBalancingCell067 m66 : 31|1@1+ (1.000000,0.000000) [0.000000|1.000000] ""  Logger
 SG_ BBalancingCell068 m67 : 31|1@1+ (1.000000,0.000000) [0.000000|1.000000] ""  Logger
 SG_ BBalancingCell069 m68 : 31|1@1+ (1.000000,0.000000) [0.000000|1.000000] ""  Logger
 SG_ BBalancingCell070 m69 : 31|1@1+ (1.000000,0.000000) [0.000000|1.000000] ""  Logger
 SG_ BBalancingCell071 m70 : 31|1@1+ (1.000000,0.000000) [0.000000|1.000000] ""  Logger
 SG_ BBalancingCell072 m71 : 31|1@1+ (1.000000,0.000000) [0.000000|1.000000] ""  Logger
 SG_ BBalancingCell073 m72 : 31|1@1+ (1.000000,0.000000) [0.000000|1.000000] ""  Logger
 SG_ BBalancingCell074 m73 : 31|1@1+ (1.000000,0.000000) [0.000000|1.000000] ""  Logger
 SG_ BBalancingCell075 m74 : 31|1@1+ (1.000000,0.000000) [0.000000|1.000000] ""  Logger
 SG_ BBalancingCell076 m75 : 31|1@1+ (1.000000,0.000000) [0.000000|1.000000] ""  Logger
 SG_ BBalancingCell077 m76 : 31|1@1+ (1.000000,0.000000) [0.000000|1.000000] ""  Logger
 SG_ BBalancingCell078 m77 : 31|1@1+ (1.000000,0.000000) [0.000000|1.000000] ""  Logger
 SG_ BBalancingCell079 m78 : 31|1@1+ (1.000000,0.000000) [0.000000|1.000000] ""  Logger
 SG_ BBalancingCell080 m79 : 31|1@1+ (1.000000,0.000000) [0.000000|1.000000] ""  Logger
 SG_ BBalancingCell081 m80 : 31|1@1+ (1.000000,0.000000) [0.000000|1.000000] ""  Logger
 SG_ BBalancingCell082 m81 : 31|1@1+ (1.000000,0.000000) [0.000000|1.000000] ""  Logger
 SG_ BBalancingCell083 m82 : 31|1@1+ (1.000000,0.000000) [0.000000|1.000000] ""  Logger
 SG_ BBalancingCell084 m83 : 31|1@1+ (1.000000,0.000000) [0.000000|1.000000] ""  Logger
 SG_ BBalancingCell085 m84 : 31|1@1+ (1.000000,0.000000) [0.000000|1.000000] ""  Logger
 SG_ BBalancingCell086 m85 : 31|1@1+ (1.000000,0.000000) [0.000000|1.000000] ""  Logger
 SG_ BBalancingCell087 m86 : 31|1@1+ (1.000000,0.000000) [0.000000|1.000000] ""  Logger
 SG_ BBalancingCell088 m87 : 31|1@1+ (1.000000,0.000000) [0.000000|1.000000] ""  Logger
 SG_ BBalancingCell089 m88 : 31|1@1+ (1.000000,0.000000) [0.000000|1.000000] ""  Logger
 SG_ BBalancingCell090 m89 : 31|1@1+ (1.000000,0.000000) [0.000000|1.000000] ""  Logger
 SG_ BBalancingCell091 m90 : 31|1@1+ (1.000000,0.000000) [0.000000|1.000000] ""  Logger
 SG_ BBalancingCell092 m91 : 31|1@1+ (1.000000,0.000000) [0.000000|1.000000] ""  Logger
 SG_ BBalancingCell093 m92 : 31|1@1+ (1.000000,0.000000) [0.000000|1.000000] ""  Logger
 SG_ BBalancingCell094 m93 : 31|1@1+ (1.000000,0.000000) [0.000000|1.000000] ""  Logger
 SG_ BBalancingCell095 m94 : 31|1@1+ (1.000000,0.000000) [0.000000|1.000000] ""  Logger
 SG_ BBalancingCell096 m95 : 31|1@1+ (1.000000,0.000000) [0.000000|1.000000] ""  Logger
 SG_ BBalancingCell097 m96 : 31|1@1+ (1.000000,0.000000) [0.000000|1.000000] ""  Logger
 SG_ BBalancingCell098 m97 : 31|1@1+ (1.000000,0.000000) [0.000000|1.000000] ""  Logger
 SG_ BBalancingCell099 m98 : 31|1@1+ (1.000000,0.000000) [0.000000|1.000000] ""  Logger
 SG_ BBalancingCell100 m99 : 31|1@1+ (1.000000,0.000000) [0.000000|1.000000] ""  Logger
 SG_ BBalancingCell101 m100 : 31|1@1+ (1.000000,0.000000) [0.000000|1.000000] ""  Logger
 SG_ BBalancingCell102 m101 : 31|1@1+ (1.000000,0.000000) [0.000000|1.000000] ""  Logger
 SG_ BBalancingCell103 m102 : 31|1@1+ (1.000000,0.000000) [0.000000|1.000000] ""  Logger
 SG_ BBalancingCell104 m103 : 31|1@1+ (1.000000,0.000000) [0.000000|1.000000] ""  Logger
 SG_ BBalancingCell105 m104 : 31|1@1+ (1.000000,0.000000) [0.000000|1.000000] ""  Logger
 SG_ BBalancingCell106 m105 : 31|1@1+ (1.000000,0.000000) [0.000000|1.000000] ""  Logger
 SG_ BBalancingCell107 m106 : 31|1@1+ (1.000000,0.000000) [0.000000|1.000000] ""  Logger
 SG_ BBalancingCell108 m107 : 31|1@1+ (1.000000,0.000000) [0.000000|1.000000] ""  Logger
 SG_ BBalancingCell109 m108 : 31|1@1+ (1.000000,0.000000) [0.000000|1.000000] ""  Logger
 SG_ BBalancingCell110 m109 : 31|1@1+ (1.000000,0.000000) [0.000000|1.000000] ""  Logger
 SG_ BBalancingCell111 m110 : 31|1@1+ (1.000000,0.000000) [0.000000|1.000000] ""  Logger
 SG_ BBalancingCell112 m111 : 31|1@1+ (1.000000,0.000000) [0.000000|1.000000] ""  Logger
 SG_ VOpenCell001 m0 : 47|16@0+ (0.000100,0.000000) [0.000000|6.553500] "V"  Logger
 SG_ VOpenCell002 m1 : 47|16@0+ (0.000100,0.000000) [0.000000|6.553500] "V"  Logger
 SG_ VOpenCell003 m2 : 47|16@0+ (0.000100,0.000000) [0.000000|6.553500] "V"  Logger
 SG_ VOpenCell004 m3 : 47|16@0+ (0.000100,0.000000) [0.000000|6.553500] "V"  Logger
 SG_ VOpenCell005 m4 : 47|16@0+ (0.000100,0.000000) [0.000000|6.553500] "V"  Logger
 SG_ VOpenCell006 m5 : 47|16@0+ (0.000100,0.000000) [0.000000|6.553500] "V"  Logger
 SG_ VOpenCell007 m6 : 47|16@0+ (0.000100,0.000000) [0.000000|6.553500] "V"  Logger
 SG_ VOpenCell008 m7 : 47|16@0+ (0.000100,0.000000) [0.000000|6.553500] "V"  Logger
 SG_ VOpenCell009 m8 : 47|16@0+ (0.000100,0.000000) [0.000000|6.553500] "V"  Logger
 SG_ VOpenCell010 m9 : 47|16@0+ (0.000100,0.000000) [0.000000|6.553500] "V"  Logger
 SG_ VOpenCell011 m10 : 47|16@0+ (0.000100,0.000000) [0.000000|6.553500] "V"  Logger
 SG_ VOpenCell012 m11 : 47|16@0+ (0.000100,0.000000) [0.000000|6.553500] "V"  Logger
 SG_ VOpenCell013 m12 : 47|16@0+ (0.000100,0.000000) [0.000000|6.553500] "V"  Logger
 SG_ VOpenCell014 m13 : 47|16@0+ (0.000100,0.000000) [0.000000|6.553500] "V"  Logger
 SG_ VOpenCell015 m14 : 47|16@0+ (0.000100,0.000000) [0.000000|6.553500] "V"  Logger
 SG_ VOpenCell016 m15 : 47|16@0+ (0.000100,0.000000) [0.000000|6.553500] "V"  Logger
 SG_ VOpenCell017 m16 : 47|16@0+ (0.000100,0.000000) [0.000000|6.553500] "V"  Logger
 SG_ VOpenCell018 m17 : 47|16@0+ (0.000100,0.000000) [0.000000|6.553500] "V"  Logger
 SG_ VOpenCell019 m18 : 47|16@0+ (0.000100,0.000000) [0.000000|6.553500] "V"  Logger
 SG_ VOpenCell020 m19 : 47|16@0+ (0.000100,0.000000) [0.000000|6.553500] "V"  Logger
 SG_ VOpenCell021 m20 : 47|16@0+ (0.000100,0.000000) [0.000000|6.553500] "V"  Logger
 SG_ VOpenCell022 m21 : 47|16@0+ (0.000100,0.000000) [0.000000|6.553500] "V"  Logger
 SG_ VOpenCell023 m22 : 47|16@0+ (0.000100,0.000000) [0.000000|6.553500] "V"  Logger
 SG_ VOpenCell024 m23 : 47|16@0+ (0.000100,0.000000) [0.000000|6.553500] "V"  Logger
 SG_ VOpenCell025 m24 : 47|16@0+ (0.000100,0.000000) [0.000000|6.553500] "V"  Logger
 SG_ VOpenCell026 m25 : 47|16@0+ (0.000100,0.000000) [0.000000|6.553500] "V"  Logger
 SG_ VOpenCell027 m26 : 47|16@0+ (0.000100,0.000000) [0.000000|6.553500] "V"  Logger
 SG_ VOpenCell028 m27 : 47|16@0+ (0.000100,0.000000) [0.000000|6.553500] "V"  Logger
 SG_ VOpenCell029 m28 : 47|16@0+ (0.000100,0.000000) [0.000000|6.553500] "V"  Logger
 SG_ VOpenCell030 m29 : 47|16@0+ (0.000100,0.000000) [0.000000|6.553500] "V"  Logger
 SG_ VOpenCell031 m30 : 47|16@0+ (0.000100,0.000000) [0.000000|6.553500] "V"  Logger
 SG_ VOpenCell032 m31 : 47|16@0+ (0.000100,0.000000) [0.000000|6.553500] "V"  Logger
 SG_ VOpenCell033 m32 : 47|16@0+ (0.000100,0.000000) [0.000000|6.553500] "V"  Logger
 SG_ VOpenCell034 m33 : 47|16@0+ (0.000100,0.000000) [0.000000|6.553500] "V"  Logger
 SG_ VOpenCell035 m34 : 47|16@0+ (0.000100,0.000000) [0.000000|6.553500] "V"  Logger
 SG_ VOpenCell036 m35 : 47|16@0+ (0.000100,0.000000) [0.000000|6.553500] "V"  Logger
 SG_ VOpenCell037 m36 : 47|16@0+ (0.000100,0.000000) [0.000000|6.553500] "V"  Logger
 SG_ VOpenCell038 m37 : 47|16@0+ (0.000100,0.000000) [0.000000|6.553500] "V"  Logger
 SG_ VOpenCell039 m38 : 47|16@0+ (0.000100,0.000000) [0.000000|6.553500] "V"  Logger
 SG_ VOpenCell040 m39 : 47|16@0+ (0.000100,0.000000) [0.000000|6.553500] "V"  Logger
 SG_ VOpenCell041 m40 : 47|16@0+ (0.000100,0.000000) [0.000000|6.553500] "V"  Logger
 SG_ VOpenCell042 m41 : 47|16@0+ (0.000100,0.000000) [0.000000|6.553500] "V"  Logger
 SG_ VOpenCell043 m42 : 47|16@0+ (0.000100,0.000000) [0.000000|6.553500] "V"  Logger
 SG_ VOpenCell044 m43 : 47|16@0+ (0.000100,0.000000) [0.000000|6.553500] "V"  Logger
 SG_ VOpenCell045 m44 : 47|16@0+ (0.000100,0.000000) [0.000000|6.553500] "V"  Logger
 SG_ VOpenCell046 m45 : 47|16@0+ (0.000100,0.000000) [0.000000|6.553500] "V"  Logger
 SG_ VOpenCell047 m46 : 47|16@0+ (0.000100,0.000000) [0.000000|6.553500] "V"  Logger
 SG_ VOpenCell048 m47 : 47|16@0+ (0.000100,0.000000) [0.000000|6.553500] "V"  Logger
 SG_ VOpenCell049 m48 : 47|16@0+ (0.000100,0.000000) [0.000000|6.553500] "V"  Logger
 SG_ VOpenCell050 m49 : 47|16@0+ (0.000100,0.000000) [0.000000|6.553500] "V"  Logger
 SG_ VOpenCell051 m50 : 47|16@0+ (0.000100,0.000000) [0.000000|6.553500] "V"  Logger
 SG_ VOpenCell052 m51 : 47|16@0+ (0.000100,0.000000) [0.000000|6.553500] "V"  Logger
 SG_ VOpenCell053 m52 : 47|16@0+ (0.000100,0.000000) [0.000000|6.553500] "V"  Logger
 SG_ VOpenCell054 m53 : 47|16@0+ (0.000100,0.000000) [0.000000|6.553500] "V"  Logger
 SG_ VOpenCell055 m54 : 47|16@0+ (0.000100,0.000000) [0.000000|6.553500] "V"  Logger
 SG_ VOpenCell056 m55 : 47|16@0+ (0.000100,0.000000) [0.000000|6.553500] "V"  Logger
 SG_ VOpenCell057 m56 : 47|16@0+ (0.000100,0.000000) [0.000000|6.553500] "V"  Logger
 SG_ VOpenCell058 m57 : 47|16@0+ (0.000100,0.000000) [0.000000|6.553500] "V"  Logger
 SG_ VOpenCell059 m58 : 47|16@0+ (0.000100,0.000000) [0.000000|6.553500] "V"  Logger
 SG_ VOpenCell060 m59 : 47|16@0+ (0.000100,0.000000) [0.000000|6.553500] "V"  Logger
 SG_ VOpenCell061 m60 : 47|16@0+ (0.000100,0.000000) [0.000000|6.553500] "V"  Logger
 SG_ VOpenCell062 m61 : 47|16@0+ (0.000100,0.000000) [0.000000|6.553500] "V"  Logger
 SG_ VOpenCell063 m62 : 47|16@0+ (0.000100,0.000000) [0.000000|6.553500] "V"  Logger
 SG_ VOpenCell064 m63 : 47|16@0+ (0.000100,0.000000) [0.000000|6.553500] "V"  Logger
 SG_ VOpenCell065 m64 : 47|16@0+ (0.000100,0.000000) [0.000000|6.553500] "V"  Logger
 SG_ VOpenCell066 m65 : 47|16@0+ (0.000100,0.000000) [0.000000|6.553500] "V"  Logger
 SG_ VOpenCell067 m66 : 47|16@0+ (0.000100,0.000000) [0.000000|6.553500] "V"  Logger
 SG_ VOpenCell068 m67 : 47|16@0+ (0.000100,0.000000) [0.000000|6.553500] "V"  Logger
 SG_ VOpenCell069 m68 : 47|16@0+ (0.000100,0.000000) [0.000000|6.553500] "V"  Logger
 SG_ VOpenCell070 m69 : 47|16@0+ (0.000100,0.000000) [0.000000|6.553500] "V"  Logger
 SG_ VOpenCell071 m70 : 47|16@0+ (0.000100,0.000000) [0.000000|6.553500] "V"  Logger
 SG_ VOpenCell072 m71 : 47|16@0+ (0.000100,0.000000) [0.000000|6.553500] "V"  Logger
 SG_ VOpenCell073 m72 : 47|16@0+ (0.000100,0.000000) [0.000000|6.553500] "V"  Logger
 SG_ VOpenCell074 m73 : 47|16@0+ (0.000100,0.000000) [0.000000|6.553500] "V"  Logger
 SG_ VOpenCell075 m74 : 47|16@0+ (0.000100,0.000000) [0.000000|6.553500] "V"  Logger
 SG_ VOpenCell076 m75 : 47|16@0+ (0.000100,0.000000) [0.000000|6.553500] "V"  Logger
 SG_ VOpenCell077 m76 : 47|16@0+ (0.000100,0.000000) [0.000000|6.553500] "V"  Logger
 SG_ VOpenCell078 m77 : 47|16@0+ (0.000100,0.000000) [0.000000|6.553500] "V"  Logger
 SG_ VOpenCell079 m78 : 47|16@0+ (0.000100,0.000000) [0.000000|6.553500] "V"  Logger
 SG_ VOpenCell080 m79 : 47|16@0+ (0.000100,0.000000) [0.000000|6.553500] "V"  Logger
 SG_ VOpenCell081 m80 : 47|16@0+ (0.000100,0.000000) [0.000000|6.553500] "V"  Logger
 SG_ VOpenCell082 m81 : 47|16@0+ (0.000100,0.000000) [0.000000|6.553500] "V"  Logger
 SG_ VOpenCell083 m82 : 47|16@0+ (0.000100,0.000000) [0.000000|6.553500] "V"  Logger
 SG_ VOpenCell084 m83 : 47|16@0+ (0.000100,0.000000) [0.000000|6.553500] "V"  Logger
 SG_ VOpenCell085 m84 : 47|16@0+ (0.000100,0.000000) [0.000000|6.553500] "V"  Logger
 SG_ VOpenCell086 m85 : 47|16@0+ (0.000100,0.000000) [0.000000|6.553500] "V"  Logger
 SG_ VOpenCell087 m86 : 47|16@0+ (0.000100,0.000000) [0.000000|6.553500] "V"  Logger
 SG_ VOpenCell088 m87 : 47|16@0+ (0.000100,0.000000) [0.000000|6.553500] "V"  Logger
 SG_ VOpenCell089 m88 : 47|16@0+ (0.000100,0.000000) [0.000000|6.553500] "V"  Logger
 SG_ VOpenCell090 m89 : 47|16@0+ (0.000100,0.000000) [0.000000|6.553500] "V"  Logger
 SG_ VOpenCell091 m90 : 47|16@0+ (0.000100,0.000000) [0.000000|6.553500] "V"  Logger
 SG_ VOpenCell092 m91 : 47|16@0+ (0.000100,0.000000) [0.000000|6.553500] "V"  Logger
 SG_ VOpenCell093 m92 : 47|16@0+ (0.000100,0.000000) [0.000000|6.553500] "V"  Logger
 SG_ VOpenCell094 m93 : 47|16@0+ (0.000100,0.000000) [0.000000|6.553500] "V"  Logger
 SG_ VOpenCell095 m94 : 47|16@0+ (0.000100,0.000000) [0.000000|6.553500] "V"  Logger
 SG_ VOpenCell096 m95 : 47|16@0+ (0.000100,0.000000) [0.000000|6.553500] "V"  Logger
 SG_ VOpenCell097 m96 : 47|16@0+ (0.000100,0.000000) [0.000000|6.553500] "V"  Logger
 SG_ VOpenCell098 m97 : 47|16@0+ (0.000100,0.000000) [0.000000|6.553500] "V"  Logger
 SG_ VOpenCell099 m98 : 47|16@0+ (0.000100,0.000000) [0.000000|6.553500] "V"  Logger
 SG_ VOpenCell100 m99 : 47|16@0+ (0.000100,0.000000) [0.000000|6.553500] "V"  Logger
 SG_ VOpenCell101 m100 : 47|16@0+ (0.000100,0.000000) [0.000000|6.553500] "V"  Logger
 SG_ VOpenCell102 m101 : 47|16@0+ (0.000100,0.000000) [0.000000|6.553500] "V"  Logger
 SG_ VOpenCell103 m102 : 47|16@0+ (0.000100,0.000000) [0.000000|6.553500] "V"  Logger
 SG_ VOpenCell104 m103 : 47|16@0+ (0.000100,0.000000) [0.000000|6.553500] "V"  Logger
 SG_ VOpenCell105 m104 : 47|16@0+ (0.000100,0.000000) [0.000000|6.553500] "V"  Logger
 SG_ VOpenCell106 m105 : 47|16@0+ (0.000100,0.000000) [0.000000|6.553500] "V"  Logger
 SG_ VOpenCell107 m106 : 47|16@0+ (0.000100,0.000000) [0.000000|6.553500] "V"  Logger
 SG_ VOpenCell108 m107 : 47|16@0+ (0.000100,0.000000) [0.000000|6.553500] "V"  Logger
 SG_ VOpenCell109 m108 : 47|16@0+ (0.000100,0.000000) [0.000000|6.553500] "V"  Logger
 SG_ VOpenCell110 m109 : 47|16@0+ (0.000100,0.000000) [0.000000|6.553500] "V"  Logger
 SG_ VOpenCell111 m110 : 47|16@0+ (0.000100,0.000000) [0.000000|6.553500] "V"  Logger
 SG_ VOpenCell112 m111 : 47|16@0+ (0.000100,0.000000) [0.000000|6.553500] "V"  Logger
 SG_ CheckSum_CellVoltages : 63|8@0+ (1.000000,0.000000) [0.000000|255.000000] ""  Logger

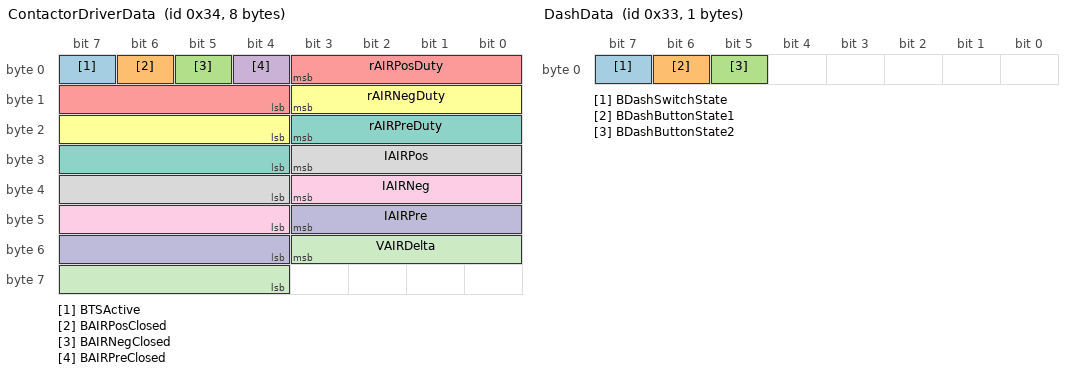
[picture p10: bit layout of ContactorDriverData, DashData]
BO_ 52 ContactorDriverData: 8 ContactorDriver
 SG_ BTSActive : 7|1@0+ (1.000000,0.000000) [0.000000|1.000000] ""  Dash
 SG_ BAIRPosClosed : 6|1@0+ (1.000000,0.000000) [0.000000|1.000000] ""  Dash
 SG_ BAIRNegClosed : 5|1@0+ (1.000000,0.000000) [0.000000|1.000000] ""  Dash
 SG_ BAIRPreClosed : 4|1@0+ (1.000000,0.000000) [0.000000|1.000000] ""  Dash
 SG_ rAIRPosDuty : 3|8@0+ (0.500000,0.000000) [0.000000|127.500000] "%"  Dash
 SG_ rAIRNegDuty : 11|8@0+ (0.500000,0.000000) [0.000000|127.500000] "%"  Dash
 SG_ rAIRPreDuty : 19|8@0+ (0.500000,0.000000) [0.000000|127.500000] "%"  Dash
 SG_ IAIRPos : 27|8@0+ (0.100000,0.000000) [0.000000|25.500000] "A"  Dash
 SG_ IAIRNeg : 35|8@0+ (0.100000,0.000000) [0.000000|25.500000] "A"  Dash
 SG_ IAIRPre : 43|8@0+ (0.100000,0.000000) [0.000000|25.500000] "A"  Dash
 SG_ VAIRDelta : 51|8@0+ (1.000000,0.000000) [0.000000|255.000000] "V"  Dash

BO_ 51 DashData: 1 Dash
 SG_ BDashSwitchState : 7|1@0+ (1.000000,0.000000) [0.000000|1.000000] ""  ContactorDriver
 SG_ BDashButtonState1 : 6|1@0+ (1.000000,0.000000) [0.000000|1.000000] ""  ContactorDriver
 SG_ BDashButtonState2 : 5|1@0+ (1.000000,0.000000) [0.000000|1.000000] ""  ContactorDriver

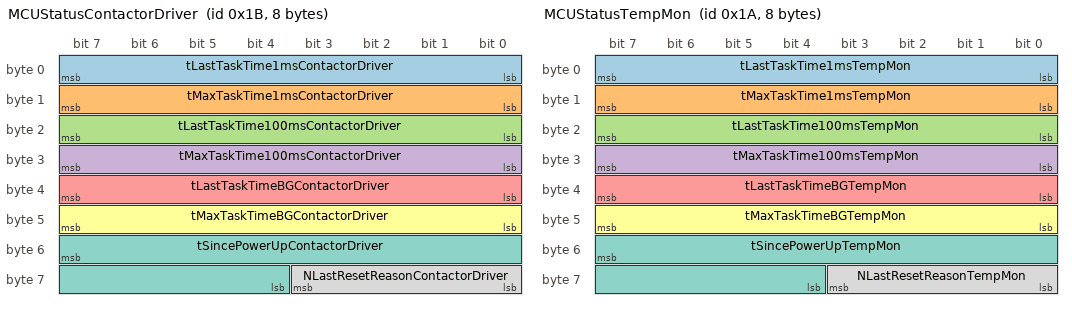
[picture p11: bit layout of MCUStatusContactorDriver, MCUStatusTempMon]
BO_ 27 MCUStatusContactorDriver: 8 ContactorDriver
 SG_ tLastTaskTime1msContactorDriver : 7|8@0+ (50.000000,0.000000) [0.000000|12750.000000] "us"  Logger
 SG_ tMaxTaskTime1msContactorDriver : 15|8@0+ (50.000000,0.000000) [0.000000|12750.000000] "us"  Logger
 SG_ tLastTaskTime100msContactorDriver : 23|8@0+ (500.000000,0.000000) [0.000000|127500.000000] "us"  Logger
 SG_ tMaxTaskTime100msContactorDriver : 31|8@0+ (500.000000,0.000000) [0.000000|127500.000000] "us"  Logger
 SG_ tLastTaskTimeBGContactorDriver : 39|8@0+ (500.000000,0.000000) [0.000000|127500.000000] "us"  Logger
 SG_ tMaxTaskTimeBGContactorDriver : 47|8@0+ (500.000000,0.000000) [0.000000|127500.000000] "us"  Logger
 SG_ tSincePowerUpContactorDriver : 55|12@0+ (4.000000,0.000000) [0.000000|16380.000000] "s"  Logger
 SG_ NLastResetReasonContactorDriver : 59|4@0+ (1.000000,0.000000) [0.000000|15.000000] ""  Logger

BO_ 26 MCUStatusTempMon: 8 TempMon
 SG_ tLastTaskTime1msTempMon : 7|8@0+ (50.000000,0.000000) [0.000000|12750.000000] "us"  Logger
 SG_ tMaxTaskTime1msTempMon : 15|8@0+ (50.000000,0.000000) [0.000000|12750.000000] "us"  Logger
 SG_ tLastTaskTime100msTempMon : 23|8@0+ (500.000000,0.000000) [0.000000|127500.000000] "us"  Logger
 SG_ tMaxTaskTime100msTempMon : 31|8@0+ (500.000000,0.000000) [0.000000|127500.000000] "us"  Logger
 SG_ tLastTaskTimeBGTempMon : 39|8@0+ (500.000000,0.000000) [0.000000|127500.000000] "us"  Logger
 SG_ tMaxTaskTimeBGTempMon : 47|8@0+ (500.000000,0.000000) [0.000000|127500.000000] "us"  Logger
 SG_ tSincePowerUpTempMon : 55|12@0+ (4.000000,0.000000) [0.000000|16380.000000] "s"  Logger
 SG_ NLastResetReasonTempMon : 59|4@0+ (1.000000,0.000000) [0.000000|15.000000] ""  Logger

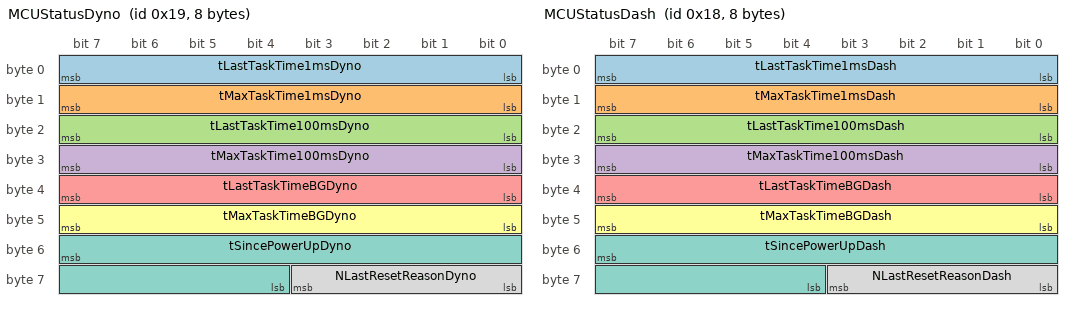
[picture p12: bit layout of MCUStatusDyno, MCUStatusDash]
BO_ 25 MCUStatusDyno: 8 Dyno
 SG_ tLastTaskTime1msDyno : 7|8@0+ (50.000000,0.000000) [0.000000|12750.000000] "us"  Logger
 SG_ tMaxTaskTime1msDyno : 15|8@0+ (50.000000,0.000000) [0.000000|12750.000000] "us"  Logger
 SG_ tLastTaskTime100msDyno : 23|8@0+ (500.000000,0.000000) [0.000000|127500.000000] "us"  Logger
 SG_ tMaxTaskTime100msDyno : 31|8@0+ (500.000000,0.000000) [0.000000|127500.000000] "us"  Logger
 SG_ tLastTaskTimeBGDyno : 39|8@0+ (500.000000,0.000000) [0.000000|127500.000000] "us"  Logger
 SG_ tMaxTaskTimeBGDyno : 47|8@0+ (500.000000,0.000000) [0.000000|127500.000000] "us"  Logger
 SG_ tSincePowerUpDyno : 55|12@0+ (4.000000,0.000000) [0.000000|16380.000000] "s"  Logger
 SG_ NLastResetReasonDyno : 59|4@0+ (1.000000,0.000000) [0.000000|15.000000] ""  Logger

BO_ 24 MCUStatusDash: 8 Dash
 SG_ tLastTaskTime1msDash : 7|8@0+ (50.000000,0.000000) [0.000000|12750.000000] "us"  Logger
 SG_ tMaxTaskTime1msDash : 15|8@0+ (50.000000,0.000000) [0.000000|12750.000000] "us"  Logger
 SG_ tLastTaskTime100msDash : 23|8@0+ (500.000000,0.000000) [0.000000|127500.000000] "us"  Logger
 SG_ tMaxTaskTime100msDash : 31|8@0+ (500.000000,0.000000) [0.000000|127500.000000] "us"  Logger
 SG_ tLastTaskTimeBGDash : 39|8@0+ (500.000000,0.000000) [0.000000|127500.000000] "us"  Logger
 SG_ tMaxTaskTimeBGDash : 47|8@0+ (500.000000,0.000000) [0.000000|127500.000000] "us"  Logger
 SG_ tSincePowerUpDash : 55|12@0+ (4.000000,0.000000) [0.000000|16380.000000] "s"  Logger
 SG_ NLastResetReasonDash : 59|4@0+ (1.000000,0.000000) [0.000000|15.000000] ""  Logger

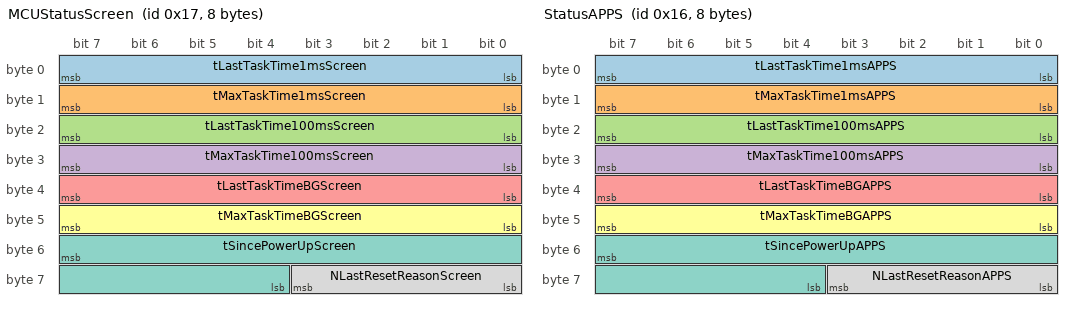
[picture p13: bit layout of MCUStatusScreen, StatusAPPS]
BO_ 23 MCUStatusScreen: 8 Screen
 SG_ tLastTaskTime1msScreen : 7|8@0+ (50.000000,0.000000) [0.000000|12750.000000] "us"  Logger
 SG_ tMaxTaskTime1msScreen : 15|8@0+ (50.000000,0.000000) [0.000000|12750.000000] "us"  Logger
 SG_ tLastTaskTime100msScreen : 23|8@0+ (500.000000,0.000000) [0.000000|127500.000000] "us"  Logger
 SG_ tMaxTaskTime100msScreen : 31|8@0+ (500.000000,0.000000) [0.000000|127500.000000] "us"  Logger
 SG_ tLastTaskTimeBGScreen : 39|8@0+ (500.000000,0.000000) [0.000000|127500.000000] "us"  Logger
 SG_ tMaxTaskTimeBGScreen : 47|8@0+ (500.000000,0.000000) [0.000000|127500.000000] "us"  Logger
 SG_ tSincePowerUpScreen : 55|12@0+ (4.000000,0.000000) [0.000000|16380.000000] "s"  Logger
 SG_ NLastResetReasonScreen : 59|4@0+ (1.000000,0.000000) [0.000000|15.000000] ""  Logger

BO_ 22 StatusAPPS: 8 APPS
 SG_ tLastTaskTime1msAPPS : 7|8@0+ (50.000000,0.000000) [0.000000|12750.000000] "us"  Logger
 SG_ tMaxTaskTime1msAPPS : 15|8@0+ (50.000000,0.000000) [0.000000|12750.000000] "us"  Logger
 SG_ tLastTaskTime100msAPPS : 23|8@0+ (500.000000,0.000000) [0.000000|127500.000000] "us"  Logger
 SG_ tMaxTaskTime100msAPPS : 31|8@0+ (500.000000,0.000000) [0.000000|127500.000000] "us"  Logger
 SG_ tLastTaskTimeBGAPPS : 39|8@0+ (500.000000,0.000000) [0.000000|127500.000000] "us"  Logger
 SG_ tMaxTaskTimeBGAPPS : 47|8@0+ (500.000000,0.000000) [0.000000|127500.000000] "us"  Logger
 SG_ tSincePowerUpAPPS : 55|12@0+ (4.000000,0.000000) [0.000000|16380.000000] "s"  Logger
 SG_ NLastResetReasonAPPS : 59|4@0+ (1.000000,0.000000) [0.000000|15.000000] ""  Logger

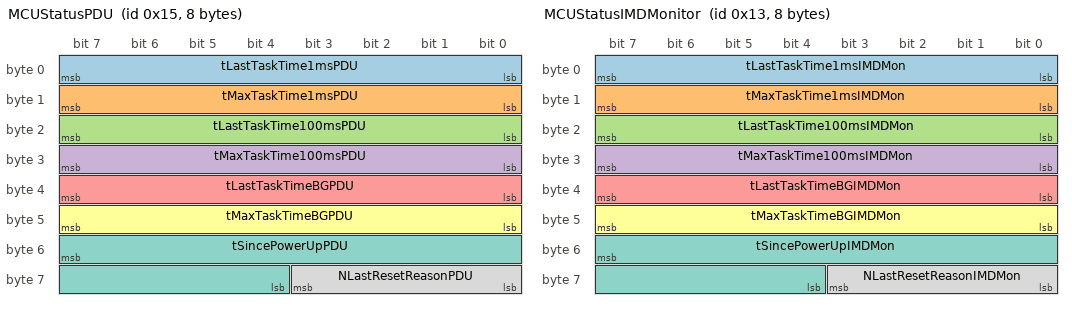
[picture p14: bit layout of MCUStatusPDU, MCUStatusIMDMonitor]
BO_ 21 MCUStatusPDU: 8 PDU
 SG_ tLastTaskTime1msPDU : 7|8@0+ (50.000000,0.000000) [0.000000|12750.000000] "us"  Logger
 SG_ tMaxTaskTime1msPDU : 15|8@0+ (50.000000,0.000000) [0.000000|12750.000000] "us"  Logger
 SG_ tLastTaskTime100msPDU : 23|8@0+ (500.000000,0.000000) [0.000000|127500.000000] "us"  Logger
 SG_ tMaxTaskTime100msPDU : 31|8@0+ (500.000000,0.000000) [0.000000|127500.000000] "us"  Logger
 SG_ tLastTaskTimeBGPDU : 39|8@0+ (500.000000,0.000000) [0.000000|127500.000000] "us"  Logger
 SG_ tMaxTaskTimeBGPDU : 47|8@0+ (500.000000,0.000000) [0.000000|127500.000000] "us"  Logger
 SG_ tSincePowerUpPDU : 55|12@0+ (4.000000,0.000000) [0.000000|16380.000000] "s"  Logger
 SG_ NLastResetReasonPDU : 59|4@0+ (1.000000,0.000000) [0.000000|15.000000] ""  Logger

BO_ 19 MCUStatusIMDMonitor: 8 IMD_Monitor
 SG_ tLastTaskTime1msIMDMon : 7|8@0+ (50.000000,0.000000) [0.000000|12750.000000] "us"  Logger
 SG_ tMaxTaskTime1msIMDMon : 15|8@0+ (50.000000,0.000000) [0.000000|12750.000000] "us"  Logger
 SG_ tLastTaskTime100msIMDMon : 23|8@0+ (500.000000,0.000000) [0.000000|127500.000000] "us"  Logger
 SG_ tMaxTaskTime100msIMDMon : 31|8@0+ (500.000000,0.000000) [0.000000|127500.000000] "us"  Logger
 SG_ tLastTaskTimeBGIMDMon : 39|8@0+ (500.000000,0.000000) [0.000000|127500.000000] "us"  Logger
 SG_ tMaxTaskTimeBGIMDMon : 47|8@0+ (500.000000,0.000000) [0.000000|127500.000000] "us"  Logger
 SG_ tSincePowerUpIMDMon : 55|12@0+ (4.000000,0.000000) [0.000000|16380.000000] "s"  Logger
 SG_ NLastResetReasonIMDMon : 59|4@0+ (1.000000,0.000000) [0.000000|15.000000] ""  Logger

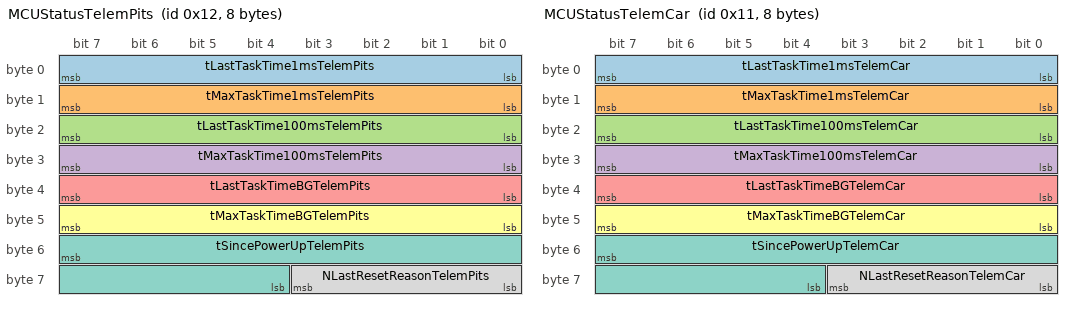
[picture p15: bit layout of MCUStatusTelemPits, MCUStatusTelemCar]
BO_ 18 MCUStatusTelemPits: 8 TelemetryPits
 SG_ tLastTaskTime1msTelemPits : 7|8@0+ (50.000000,0.000000) [0.000000|12750.000000] "us"  Logger
 SG_ tMaxTaskTime1msTelemPits : 15|8@0+ (50.000000,0.000000) [0.000000|12750.000000] "us"  Logger
 SG_ tLastTaskTime100msTelemPits : 23|8@0+ (500.000000,0.000000) [0.000000|127500.000000] "us"  Logger
 SG_ tMaxTaskTime100msTelemPits : 31|8@0+ (500.000000,0.000000) [0.000000|127500.000000] "us"  Logger
 SG_ tLastTaskTimeBGTelemPits : 39|8@0+ (500.000000,0.000000) [0.000000|127500.000000] "us"  Logger
 SG_ tMaxTaskTimeBGTelemPits : 47|8@0+ (500.000000,0.000000) [0.000000|127500.000000] "us"  Logger
 SG_ tSincePowerUpTelemPits : 55|12@0+ (4.000000,0.000000) [0.000000|16380.000000] "s"  Logger
 SG_ NLastResetReasonTelemPits : 59|4@0+ (1.000000,0.000000) [0.000000|15.000000] ""  Logger

BO_ 17 MCUStatusTelemCar: 8 TelemetryCar
 SG_ tLastTaskTime1msTelemCar : 7|8@0+ (50.000000,0.000000) [0.000000|12750.000000] "us"  Logger
 SG_ tMaxTaskTime1msTelemCar : 15|8@0+ (50.000000,0.000000) [0.000000|12750.000000] "us"  Logger
 SG_ tLastTaskTime100msTelemCar : 23|8@0+ (500.000000,0.000000) [0.000000|127500.000000] "us"  Logger
 SG_ tMaxTaskTime100msTelemCar : 31|8@0+ (500.000000,0.000000) [0.000000|127500.000000] "us"  Logger
 SG_ tLastTaskTimeBGTelemCar : 39|8@0+ (500.000000,0.000000) [0.000000|127500.000000] "us"  Logger
 SG_ tMaxTaskTimeBGTelemCar : 47|8@0+ (500.000000,0.000000) [0.000000|127500.000000] "us"  Logger
 SG_ tSincePowerUpTelemCar : 55|12@0+ (4.000000,0.000000) [0.000000|16380.000000] "s"  Logger
 SG_ NLastResetReasonTelemCar : 59|4@0+ (1.000000,0.000000) [0.000000|15.000000] ""  Logger

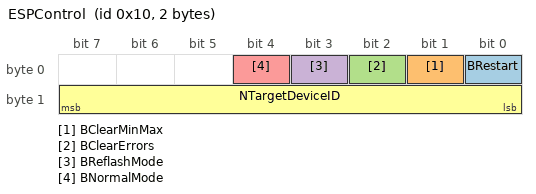
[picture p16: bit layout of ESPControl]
BO_ 16 ESPControl: 2 Dash
 SG_ BRestart : 0|1@1+ (1.000000,0.000000) [0.000000|1.000000] ""  APPS,IMD_Monitor,Logger,TelemetryCar
 SG_ BClearMinMax : 1|1@1+ (1.000000,0.000000) [0.000000|1.000000] ""  APPS,IMD_Monitor,Logger,TelemetryCar
 SG_ BClearErrors : 2|1@1+ (1.000000,0.000000) [0.000000|1.000000] ""  APPS,IMD_Monitor,Logger,TelemetryCar
 SG_ BReflashMode : 3|1@1+ (1.000000,0.000000) [1.000000|1.000000] ""  APPS,IMD_Monitor,Logger,TelemetryCar
 SG_ BNormalMode : 4|1@1+ (1.000000,0.000000) [1.000000|1.000000] ""  APPS,IMD_Monitor,Logger,TelemetryCar
 SG_ NTargetDeviceID : 15|8@0+ (1.000000,0.000000) [1.000000|255.000000] ""  APPS,IMD_Monitor,Logger,TelemetryCar

CM_ BO_ 2565799808 "J1939 Address Claim Broadcast";
CM_ BO_ 2553934720 "Thermistor Module -> BMS BroadcastClaim Broadcast";
CM_ BO_ 2553869184 "Thermistor General Broadcast";
CM_ BO_ 2550589940 "Elcon Charger to BMS Interface";
CM_ BO_ 2550589428 "Elcon Charger to BMS Interface";
CM_ BO_ 2550588916 "Elcon Charger to BMS Interface";
CM_ BO_ 1715 "Cell Statistics";
CM_ BO_ 1714 "Cell Statistics";
CM_ BO_ 1713 "Cell Statistics";
CM_ BO_ 1712 "Cell Statistics";
CM_ BO_ 1696 "Cell Temp Information";
CM_ BO_ 1220 "Node ID: 4 (decimal)";
CM_ BO_ 1188 "Node ID: 4 (decimal)";
CM_ BO_ 1156 "Node ID: 4 (decimal)";
CM_ BO_ 1124 "Node ID: 4 (decimal)";
CM_ BO_ 1092 "Node ID: 4 (decimal)";
CM_ BO_ 1060 "Node ID: 4 (decimal)";
CM_ BO_ 1028 "Node ID: 4 (decimal)";
CM_ BO_ 996 "Node ID: 4 (decimal)";
CM_ BO_ 388 "Node ID: 4 (decimal)";
CM_ BO_ 356 "Node ID: 4 (decimal)";
CM_ BO_ 324 "Node ID: 4 (decimal)";
CM_ BO_ 292 "Node ID: 4 (decimal)";
CM_ BO_ 260 "Node ID: 4 (decimal)";
CM_ BO_ 228 "Node ID: 4 (decimal)";
CM_ BO_ 178 "PDU Statistics";
CM_ BO_ 177 "PDU Statistics";
CM_ BO_ 176 "PDU Statistics";
CM_ BO_ 164 "Node ID: 4 (decimal)";
CM_ BO_ 148 "Fan and Pump control for dyno";
CM_ BO_ 147 "Sensor data from the dyno_";
CM_ BO_ 146 "Sensor data from the dyno_";
CM_ BO_ 145 "Sensor data from the data_ Raw input voltage_";
CM_ BO_ 144 "Sensor data from the data_ Raw input voltage_";
CM_ BO_ 129 "APPS Sensor Status";
CM_ BO_ 64 "Bender IMD Measurements";
CM_ BO_ 54 "All Cell Voltages";
CM_ BO_ 27 "MCU Status Message";
CM_ BO_ 26 "MCU Status Message";
CM_ BO_ 25 "MCU Status Message";
CM_ BO_ 24 "MCU Status Message";
CM_ BO_ 23 "MCU Status Message";
CM_ BO_ 22 "MCU Status Message";
CM_ BO_ 21 "MCU Status Message";
CM_ BO_ 19 "MCU Status Message";
CM_ BO_ 18 "MCU Status Message";
CM_ BO_ 17 "MCU Status Message";
CM_ BO_ 16 "ESP Control Message";
CM_ SG_ 2565799808 NTempMonJ1939Address "Unique identifier for J1939 compatible address claim (Default value is: 0xF3 00 80)";
CM_ SG_ 2565799808 NTempMonTargetAddress "BMS Target Address (0xF3 default)";
CM_ SG_ 2565799808 NTempMonNumber "Thermistor Module Number << 3 (Default = 0x00)";
CM_ SG_ 2565799808 Constant "Constant";
CM_ SG_ 2553934720 TCellMin "Lowest thermistor value";
CM_ SG_ 2553934720 TCellMax "Highest thermistor value";
CM_ SG_ 2553934720 TCellAvg "Average thermistor value";
CM_ SG_ 2553934720 NCellTemps "Number of thermistors enabled";
CM_ SG_ 2553934720 NTCellMaxID "Highest thermistor ID on the module";
CM_ SG_ 2553934720 NTCellMinID "Lowest thermistor ID on the module";
CM_ SG_ 2553934720 CheckSum_BMSCellTemp "CheckSum Rule 1";
CM_ SG_ 2553869184 NTCellID "Thermistor ID relative to all configured Thermistor Modules";
CM_ SG_ 2553869184 TCell001 "Thermistor value Cell001";
CM_ SG_ 2553869184 TCell002 "Thermistor value Cell002";
CM_ SG_ 2553869184 TCell003 "Thermistor value Cell003";
CM_ SG_ 2553869184 TCell004 "Thermistor value Cell004";
CM_ SG_ 2553869184 TCell005 "Thermistor value Cell005";
CM_ SG_ 2553869184 TCell006 "Thermistor value Cell006";
CM_ SG_ 1715 VCellAvg "Average cell voltage";
CM_ SG_ 1715 VIPackSensor1 "Current sensor 1 raw ADC";
CM_ SG_ 1715 VIPackSensor2 "Current sensor 2 raw ADC";
CM_ SG_ 1715 DTC_P0AA1_Precharge_Circuit_Malfunction "Error flag";
CM_ SG_ 1715 DTC_P0A11_Abnormal_State_of_Charge_Behavior "Error flag";
CM_ SG_ 1715 CheckSum_CellVoltages "Checksum Rule 2";
CM_ SG_ 1714 VCellMin "Lowest cell voltage";
CM_ SG_ 1714 VCellMax "Highest cell voltage";
CM_ SG_ 1714 DTC_P0A07_DischargeEnable_Relay_Fault "Error flag";
CM_ SG_ 1714 DTC_P0A08_Charger_Safety_Relay_Fault "Error flag";
CM_ SG_ 1714 DTC_P0A09_Internal_Hardware_Fault "Error flag";
CM_ SG_ 1714 DTC_P0A0A_Internal_Heatsink_Thermistor_Fault "Error flag";
CM_ SG_ 1714 DTC_P0A0B_Internal_Logic_Fault "Error flag";
CM_ SG_ 1714 DTC_P0A0C_Highest_Cell_Voltage_Too_High_Fault "Error flag";
CM_ SG_ 1714 DTC_P0A0E_Lowest_Cell_Voltage_Too_Low_Fault "Error flag";
CM_ SG_ 1714 DTC_P0A10_Pack_Too_Hot_Fault "Error flag";
CM_ SG_ 1713 IDischargeLimit "Pack discharge current limit";
CM_ SG_ 1713 RPack "Pack total resistance_ Estimate_";
CM_ SG_ 1713 VPackTotal "Sum of all cell voltages";
CM_ SG_ 1713 TCellMax_BMS "Max cell temperature from BMS";
CM_ SG_ 1713 TCellMin_BMS "Min cell temperature from BMS";
CM_ SG_ 1713 NFailsafeStatus "Failsafe flags";
CM_ SG_ 1712 IPack "Pack current";
CM_ SG_ 1712 VPackInstant "Pack instant voltage";
CM_ SG_ 1712 rSOC "Pack SOC";
CM_ SG_ 1712 Ready_Power_Signal "Error flag";
CM_ SG_ 1712 Charge_Power_Signal "Error flag";
CM_ SG_ 1712 Charge_Interlock "Error flag";
CM_ SG_ 1712 Balancing_Active "Error flag";
CM_ SG_ 1712 Discharge_Enable_Inverted "Error flag";
CM_ SG_ 1712 Charge_Enable_Inverted "Error flag";
CM_ SG_ 1712 Charge_Mode_Active_CAN "Error flag";
CM_ SG_ 1712 MultiPurpose_Input "Error flag";
CM_ SG_ 1712 DTC_P0A1F_Internal_Cell_Communication_Fault "Error flag";
CM_ SG_ 1712 DTC_P0A12_Cell_Balancing_Stuck_Off_Fault "Error flag";
CM_ SG_ 1712 DTC_P0A80_Weak_Cell_Fault "Error flag";
CM_ SG_ 1712 DTC_P0AFA_Low_Cell_Voltage_Fault "Error flag";
CM_ SG_ 1712 DTC_P0A04_Cell_Open_Wiring_Fault "Error flag";
CM_ SG_ 1712 DTC_P0AC0_Current_Sensor_Fault "Error flag";
CM_ SG_ 1712 DTC_P0A0D_Cell_Voltage_Over_5V_Fault "Error flag";
CM_ SG_ 1712 DTC_P0A0F_Cell_Bank_Fault "Error flag";
CM_ SG_ 1696 CellID_Temp "Multiplexer Value";
CM_ SG_ 1696 BTCell001InError "Temperature unreliable Cell001";
CM_ SG_ 1696 BTCell002InError "Temperature unreliable Cell002";
CM_ SG_ 1696 BTCell003InError "Temperature unreliable Cell003";
CM_ SG_ 1696 BTCell004InError "Temperature unreliable Cell004";
CM_ SG_ 1696 BTCell005InError "Temperature unreliable Cell005";
CM_ SG_ 1696 BTCell006InError "Temperature unreliable Cell006";
CM_ SG_ 1696 BTCell007InError "Temperature unreliable Cell007";
CM_ SG_ 1696 BTCell008InError "Temperature unreliable Cell008";
CM_ SG_ 1696 BTCell009InError "Temperature unreliable Cell009";
CM_ SG_ 1696 BTCell010InError "Temperature unreliable Cell010";
CM_ SG_ 1696 BTCell011InError "Temperature unreliable Cell011";
CM_ SG_ 1696 BTCell012InError "Temperature unreliable Cell012";
CM_ SG_ 1696 BTCell013InError "Temperature unreliable Cell013";
CM_ SG_ 1696 BTCell014InError "Temperature unreliable Cell014";
CM_ SG_ 1696 BTCell015InError "Temperature unreliable Cell015";
CM_ SG_ 1696 BTCell016InError "Temperature unreliable Cell016";
CM_ SG_ 1696 BTCell017InError "Temperature unreliable Cell017";
CM_ SG_ 1696 BTCell018InError "Temperature unreliable Cell018";
CM_ SG_ 1696 BTCell019InError "Temperature unreliable Cell019";
CM_ SG_ 1696 BTCell020InError "Temperature unreliable Cell020";
CM_ SG_ 1696 BTCell021InError "Temperature unreliable Cell021";
CM_ SG_ 1696 BTCell022InError "Temperature unreliable Cell022";
CM_ SG_ 1696 BTCell023InError "Temperature unreliable Cell023";
CM_ SG_ 1696 BTCell024InError "Temperature unreliable Cell024";
CM_ SG_ 1696 BTCell025InError "Temperature unreliable Cell025";
CM_ SG_ 1696 BTCell026InError "Temperature unreliable Cell026";
CM_ SG_ 1696 BTCell027InError "Temperature unreliable Cell027";
CM_ SG_ 1696 BTCell028InError "Temperature unreliable Cell028";
CM_ SG_ 1696 BTCell029InError "Temperature unreliable Cell029";
CM_ SG_ 1696 BTCell030InError "Temperature unreliable Cell030";
CM_ SG_ 1696 BTCell031InError "Temperature unreliable Cell031";
CM_ SG_ 1696 BTCell032InError "Temperature unreliable Cell032";
CM_ SG_ 1696 BTCell033InError "Temperature unreliable Cell033";
CM_ SG_ 1696 BTCell034InError "Temperature unreliable Cell034";
CM_ SG_ 1696 BTCell035InError "Temperature unreliable Cell035";
CM_ SG_ 1696 BTCell036InError "Temperature unreliable Cell036";
CM_ SG_ 1696 BTCell037InError "Temperature unreliable Cell037";
CM_ SG_ 1696 BTCell038InError "Temperature unreliable Cell038";
CM_ SG_ 1696 BTCell039InError "Temperature unreliable Cell039";
CM_ SG_ 1696 BTCell040InError "Temperature unreliable Cell040";
CM_ SG_ 1696 BTCell041InError "Temperature unreliable Cell041";
CM_ SG_ 1696 BTCell042InError "Temperature unreliable Cell042";
CM_ SG_ 1696 BTCell043InError "Temperature unreliable Cell043";
CM_ SG_ 1696 BTCell044InError "Temperature unreliable Cell044";
CM_ SG_ 1696 BTCell045InError "Temperature unreliable Cell045";
CM_ SG_ 1696 BTCell046InError "Temperature unreliable Cell046";
CM_ SG_ 1696 BTCell047InError "Temperature unreliable Cell047";
CM_ SG_ 1696 BTCell048InError "Temperature unreliable Cell048";
CM_ SG_ 1696 BTCell049InError "Temperature unreliable Cell049";
CM_ SG_ 1696 BTCell050InError "Temperature unreliable Cell050";
CM_ SG_ 1696 BTCell051InError "Temperature unreliable Cell051";
CM_ SG_ 1696 BTCell052InError "Temperature unreliable Cell052";
CM_ SG_ 1696 BTCell053InError "Temperature unreliable Cell053";
CM_ SG_ 1696 BTCell054InError "Temperature unreliable Cell054";
CM_ SG_ 1696 BTCell055InError "Temperature unreliable Cell055";
CM_ SG_ 1696 BTCell056InError "Temperature unreliable Cell056";
CM_ SG_ 1220 MaxDcCurrent "Max DC current configured with the DTI CAN tool_";
CM_ SG_ 1220 AvailableMaxDcCurrent "Available max DC current_ This value affected by the limitation functions (igbt temp_ motortemp etc_) Defines how much current available from the configured one_";
CM_ SG_ 1220 MinDcCurrent "Min DC current configured with the DTI CAN tool_";
CM_ SG_ 1220 AvailableMinDcCurrent "Available min DC current_ This value affected by the limitation functions (igbt temp_ motortemp etc_) Defines how much current available from the configured one_";
CM_ SG_ 1188 MaxAcCurrent "Max AC current configured with the DTI CAN tool_";
CM_ SG_ 1188 AvailableMaxAcCurrent "Available max AC current_ This value affected by the limitation functions (igbt temp_ motortemp etc_) Defines how much current available from the configured one_";
CM_ SG_ 1188 MinAcCurrent "Min AC current configured with the DTI CAN tool_";
CM_ SG_ 1188 AvailableMinAcCurrent "Available min AC current_ This value affected by the limitation functions (igbt temp_ motortemp etc_) Defines how much current available from the configured one_";
CM_ SG_ 1156 Actual_Throttle "Throttle signal derived from analog inputs or CAN2_";
CM_ SG_ 1156 Actual_Brake "Brake signal derived from analog inputs or CAN2_";
CM_ SG_ 1156 CAN_map_version "Indicates the CAN map version_ For ex: 23 -> 2_3 (V2_3)";
CM_ SG_ 1124 Actual_FOC_id "FOC algorithm component Id_";
CM_ SG_ 1124 Actual_FOC_iq "FOC algorithm component Iq";
CM_ SG_ 1092 Actual_TempController "Temperature of the inverter semiconductors_";
CM_ SG_ 1092 Actual_TempMotor "Temperature of the motor measured by the inverter_";
CM_ SG_ 1092 Actual_FaultCode "Fault codes_";
CM_ SG_ 1060 Actual_ACCurrent "The motor current_ The sign of this value represents whether the motor is running(positive) current or regenerating (negative) current_";
CM_ SG_ 1060 Actual_DCCurrent "DC Current: Current on DC side_ The sign of this value represents whether the motor is running(positive) current or regenerating (negative) current_";
CM_ SG_ 1028 Actual_ERPM "Electrical RPM
 Equation: ERPM = Motor RPM * number of the motor pole pairs_";
CM_ SG_ 1028 Actual_Duty "The controller duty cycle_ The sign of this value will represent whether the motor is running(positive) current or regenerating (negative) current_";
CM_ SG_ 1028 Actual_InputVoltage "Input voltage is the DC voltage_";
CM_ SG_ 996 ControlMode "1: CONTROL_MODE_SPEED
 2: CONTROL_MODE_CURRENT
 3: CONTROL_MODE_CURRENT_BRAKE
 4: CONTROL_MODE_POS
 7: CONTROL_MODE_NONE
 0_ 5_ 6: NOT USED";
CM_ SG_ 996 TargetIq "The value represent how much Iq current the inverter is targeted to reach_ This value excludes limits_ For ex_ if the target Iq is 50 A and temperature limit is hit_ the values keep 50 A in any case_ not including the deration of the temp_ limit_ This is useful in multi-inverter configuration to let know the secondary inverter the target Iq_";
CM_ SG_ 996 MotorPosition "Motor position expressed in degrees_";
CM_ SG_ 996 isMotorStill "Represents if the motor in still position or not_ 1: still_ 0: rotating";
CM_ SG_ 356 CMD_MaxDcBrakeCurrent "Minimum DC current value depends on inverter configuration_";
CM_ SG_ 292 CMD_MaxAcBrakeCurrent "Minimum AC current value depends on inverter configuration_";
CM_ SG_ 228 CMD_SetDigOutput4 "0: OFF
 1: ON";
CM_ SG_ 228 CMD_SetDigOutput3 "0: OFF
 1: ON";
CM_ SG_ 228 CMD_SetDigOutput2 "0: OFF
 1: ON";
CM_ SG_ 228 CMD_SetDigOutput1 "0: OFF
 1: ON";
CM_ SG_ 178 IAccuFan2 "Accumulator fan 2 current draw";
CM_ SG_ 178 IHorn "Horn current draw";
CM_ SG_ 177 NPump2Mode "Water pump 2 operation mode";
CM_ SG_ 177 IPump2 "Water pump 2 current draw";
CM_ SG_ 177 rAccuFan1Duty "Accumulator fan 1 duty cycle";
CM_ SG_ 177 NAccuFan1Mode "Accumulator fan 1 operation mode";
CM_ SG_ 177 IAccuFan1 "Accumulator fan 1 current draw";
CM_ SG_ 177 rAccuFan2Duty "Accumulator fan 2 duty cycle";
CM_ SG_ 177 NAccuFan2Mode "Accumulator fan 2 operation mode";
CM_ SG_ 176 rRadFanDuty "Radiator fan duty cycle";
CM_ SG_ 176 NRadFanMode "Radiator fan operation mode";
CM_ SG_ 176 IRadFan "Radiator fan current draw";
CM_ SG_ 176 rPump1Duty "Water pump 1 duty cycle";
CM_ SG_ 176 NPump1Mode "Water pump 1 operation mode";
CM_ SG_ 176 IPump1 "Water pump 1 current draw";
CM_ SG_ 176 rPump2Duty "Water pump 2 duty cycle";
CM_ SG_ 148 rDynoFanDutyManual "Duty Cycle for fan in manual mode";
CM_ SG_ 148 rDynoPumpDutyManual "Duty cycle for pump in manual mode";
CM_ SG_ 148 NDynoFanMode "Mode for cooling fan";
CM_ SG_ 148 NDynoPumpMode "Mode for cooling pump";
CM_ SG_ 147 TDynoTemp1 "Dyno Temperature Sensor 1";
CM_ SG_ 147 TDynoTemp2 "Dyno Temperature Sensor 2";
CM_ SG_ 147 TDynoTemp3 "Dyno Temperature Sensor 3";
CM_ SG_ 146 pDynoPressure1 "Dyno Pressure Sensor 1";
CM_ SG_ 146 pDynoPressure2 "Dyno Pressure Sensor 2";
CM_ SG_ 146 pDynoPressure3 "Dyno Pressure Sensor 3";
CM_ SG_ 146 VDynoCoolantFlow "Dyno Coolant Flow Rate";
CM_ SG_ 145 VDynoTemp1Raw "Dyno Temperature Sensor 1 Raw Voltage";
CM_ SG_ 145 VDynoTemp2Raw "Dyno Temperature Sensor 2 Raw Voltage";
CM_ SG_ 145 VDynoTemp3Raw "Dyno Temperature Sensor 3 Raw Voltage";
CM_ SG_ 144 VDynoPressure1Raw "Dyno Pressure Sensor 1 Raw Voltage";
CM_ SG_ 144 VDynoPressure2Raw "Dyno Pressure Sensor 2 Raw Voltage";
CM_ SG_ 144 VDynoPressure3Raw "Dyno Pressure Sensor 3 Raw Voltage";
CM_ SG_ 144 VDynoCoolantFlowRaw "Dyno Coolant Flow Rate Raw Voltage";
CM_ SG_ 129 rAPPs1 "Signal from APPS 1";
CM_ SG_ 64 BIMDOff "IMD is off";
CM_ SG_ 64 BIMDUnderVoltage "IMD detected undervoltage";
CM_ SG_ 64 BIMDStarting "IMD is starting up";
CM_ SG_ 64 BIMDSSTGood "IMD insulation state good during start up";
CM_ SG_ 64 BIMDDeviceError "IMD device is in fault";
CM_ SG_ 64 BIMDGroundConnectionFault "IMD connection to ground is broken";
CM_ SG_ 64 BIMDInvalidState "IMD is in a invalid state";
CM_ SG_ 64 RIsolation "IMD Insulation measurement";
CM_ SG_ 64 fIMDPWM "IMD PWM frequency";
CM_ SG_ 64 rIMDPWM "IMD PWM duty cycle";
CM_ SG_ 54 CellID "Multplexer number";
CM_ SG_ 54 VCell001 "Voltage of Cell 001";
CM_ SG_ 54 VCell002 "Voltage of Cell 002";
CM_ SG_ 54 VCell003 "Voltage of Cell 003";
CM_ SG_ 54 VCell004 "Voltage of Cell 004";
CM_ SG_ 51 BDashSwitchState "Dashboard switch input";
CM_ SG_ 51 BDashButtonState1 "Dashboard button input 1";
CM_ SG_ 51 BDashButtonState2 "Dashboard button input 2";
CM_ SG_ 27 tLastTaskTime1msContactorDriver "MCU 1ms Last Task Time";
CM_ SG_ 27 tMaxTaskTime1msContactorDriver "MCU 1ms Max Task Time";
CM_ SG_ 27 tLastTaskTime100msContactorDriver "MCU 100ms Last Task Time";
CM_ SG_ 27 tMaxTaskTime100msContactorDriver "MCU 100ms Max Task Time";
CM_ SG_ 27 tLastTaskTimeBGContactorDriver "MCU Background Last Task Time";
CM_ SG_ 27 tMaxTaskTimeBGContactorDriver "MCU Background Max Task Time";
CM_ SG_ 27 tSincePowerUpContactorDriver "MCU time since power up";
CM_ SG_ 27 NLastResetReasonContactorDriver "MCU Last Reset Reason";
CM_ SG_ 26 tLastTaskTime1msTempMon "MCU 1ms Last Task Time";
CM_ SG_ 26 tMaxTaskTime1msTempMon "MCU 1ms Max Task Time";
CM_ SG_ 26 tLastTaskTime100msTempMon "MCU 100ms Last Task Time";
CM_ SG_ 26 tMaxTaskTime100msTempMon "MCU 100ms Max Task Time";
CM_ SG_ 26 tLastTaskTimeBGTempMon "MCU Background Last Task Time";
CM_ SG_ 26 tMaxTaskTimeBGTempMon "MCU Background Max Task Time";
CM_ SG_ 26 tSincePowerUpTempMon "MCU time since power up";
CM_ SG_ 26 NLastResetReasonTempMon "MCU Last Reset Reason";
CM_ SG_ 25 tLastTaskTime1msDyno "MCU 1ms Last Task Time";
CM_ SG_ 25 tMaxTaskTime1msDyno "MCU 1ms Max Task Time";
CM_ SG_ 25 tLastTaskTime100msDyno "MCU 100ms Last Task Time";
CM_ SG_ 25 tMaxTaskTime100msDyno "MCU 100ms Max Task Time";
CM_ SG_ 25 tLastTaskTimeBGDyno "MCU Background Last Task Time";
CM_ SG_ 25 tMaxTaskTimeBGDyno "MCU Background Max Task Time";
CM_ SG_ 25 tSincePowerUpDyno "MCU time since power up";
CM_ SG_ 25 NLastResetReasonDyno "MCU Last Reset Reason";
CM_ SG_ 24 tLastTaskTime1msDash "MCU 1ms Last Task Time";
CM_ SG_ 24 tMaxTaskTime1msDash "MCU 1ms Max Task Time";
CM_ SG_ 24 tLastTaskTime100msDash "MCU 100ms Last Task Time";
CM_ SG_ 24 tMaxTaskTime100msDash "MCU 100ms Max Task Time";
CM_ SG_ 24 tLastTaskTimeBGDash "MCU Background Last Task Time";
CM_ SG_ 24 tMaxTaskTimeBGDash "MCU Background Max Task Time";
CM_ SG_ 24 tSincePowerUpDash "MCU time since power up";
CM_ SG_ 24 NLastResetReasonDash "MCU Last Reset Reason";
CM_ SG_ 23 tLastTaskTime1msScreen "MCU 1ms Last Task Time";
CM_ SG_ 23 tMaxTaskTime1msScreen "MCU 1ms Max Task Time";
CM_ SG_ 23 tLastTaskTime100msScreen "MCU 100ms Last Task Time";
CM_ SG_ 23 tMaxTaskTime100msScreen "MCU 100ms Max Task Time";
CM_ SG_ 23 tLastTaskTimeBGScreen "MCU Background Last Task Time";
CM_ SG_ 23 tMaxTaskTimeBGScreen "MCU Background Max Task Time";
CM_ SG_ 23 tSincePowerUpScreen "MCU time since power up";
CM_ SG_ 23 NLastResetReasonScreen "MCU Last Reset Reason";
CM_ SG_ 22 tLastTaskTime1msAPPS "MCU 1ms Last Task Time";
CM_ SG_ 22 tMaxTaskTime1msAPPS "MCU 1ms Max Task Time";
CM_ SG_ 22 tLastTaskTime100msAPPS "MCU 100ms Last Task Time";
CM_ SG_ 22 tMaxTaskTime100msAPPS "MCU 100ms Max Task Time";
CM_ SG_ 22 tLastTaskTimeBGAPPS "MCU Background Last Task Time";
CM_ SG_ 22 tMaxTaskTimeBGAPPS "MCU Background Max Task Time";
CM_ SG_ 22 tSincePowerUpAPPS "MCU time since power up";
CM_ SG_ 22 NLastResetReasonAPPS "MCU Last Reset Reason";
CM_ SG_ 21 tLastTaskTime1msPDU "MCU 1ms Last Task Time";
CM_ SG_ 21 tMaxTaskTime1msPDU "MCU 1ms Max Task Time";
CM_ SG_ 21 tLastTaskTime100msPDU "MCU 100ms Last Task Time";
CM_ SG_ 21 tMaxTaskTime100msPDU "MCU 100ms Max Task Time";
CM_ SG_ 21 tLastTaskTimeBGPDU "MCU Background Last Task Time";
CM_ SG_ 21 tMaxTaskTimeBGPDU "MCU Background Max Task Time";
CM_ SG_ 21 tSincePowerUpPDU "MCU time since power up";
CM_ SG_ 21 NLastResetReasonPDU "MCU Last Reset Reason";
CM_ SG_ 19 tLastTaskTime1msIMDMon "MCU 1ms Last Task Time";
CM_ SG_ 19 tMaxTaskTime1msIMDMon "MCU 1ms Max Task Time";
CM_ SG_ 19 tLastTaskTime100msIMDMon "MCU 100ms Last Task Time";
CM_ SG_ 19 tMaxTaskTime100msIMDMon "MCU 100ms Max Task Time";
CM_ SG_ 19 tLastTaskTimeBGIMDMon "MCU Background Last Task Time";
CM_ SG_ 19 tMaxTaskTimeBGIMDMon "MCU Background Max Task Time";
CM_ SG_ 19 tSincePowerUpIMDMon "MCU time since power up";
CM_ SG_ 19 NLastResetReasonIMDMon "MCU Last Reset Reason";
CM_ SG_ 18 tLastTaskTime1msTelemPits "MCU 1ms Last Task Time";
CM_ SG_ 18 tMaxTaskTime1msTelemPits "MCU 1ms Max Task Time";
CM_ SG_ 18 tLastTaskTime100msTelemPits "MCU 100ms Last Task Time";
CM_ SG_ 18 tMaxTaskTime100msTelemPits "MCU 100ms Max Task Time";
CM_ SG_ 18 tLastTaskTimeBGTelemPits "MCU Background Last Task Time";
CM_ SG_ 18 tMaxTaskTimeBGTelemPits "MCU Background Max Task Time";
CM_ SG_ 18 tSincePowerUpTelemPits "MCU time since power up";
CM_ SG_ 18 NLastResetReasonTelemPits "MCU Last Reset Reason";
CM_ SG_ 17 tLastTaskTime1msTelemCar "MCU 1ms Last Task Time";
CM_ SG_ 17 tMaxTaskTime1msTelemCar "MCU 1ms Max Task Time";
CM_ SG_ 17 tLastTaskTime100msTelemCar "MCU 100ms Last Task Time";
CM_ SG_ 17 tMaxTaskTime100msTelemCar "MCU 100ms Max Task Time";
CM_ SG_ 17 tLastTaskTimeBGTelemCar "MCU Background Last Task Time";
CM_ SG_ 17 tMaxTaskTimeBGTelemCar "MCU Background Max Task Time";
CM_ SG_ 17 tSincePowerUpTelemCar "MCU time since power up";
CM_ SG_ 17 NLastResetReasonTelemCar "MCU Last Reset Reason";
CM_ SG_ 16 BRestart "Restart all MCUs";
CM_ SG_ 16 BClearMinMax "Clear Min/ Max Recorded Values";
CM_ SG_ 16 BClearErrors "Clear Any Latched Values";
CM_ SG_ 16 BReflashMode "Enter Reflash mode";
CM_ SG_ 16 BNormalMode "Enter normal mode";
CM_ SG_ 16 NTargetDeviceID "Target device for command";

BA_DEF_  "BusType" STRING
;BA_DEF_DEF_  "MultiplexExtEnabled" "Yes";
BA_DEF_DEF_  "BusType" "CAN";
